VERSION "dbc-export 1 2025.20.8"

NS_ :

BS_:

BU_: APP BMS CC CMP CMPD CP DAS DI DIF DIR EPBL EPBR EVSE FC GTW HCML HCMR HVP ICR PCS PM PMF PMR PTC SCCM SCM SCS SDCR TAS UMC VC VCFRONT VCLEFT VCRIGHT VCSEC

BO_ 1962 HVP_debugMessage: 8 HVP
 SG_ HVP_debugMessageMultiplexer M : 0|4@1+ (1,0) [0|15] "" Vector__XXX
 SG_ HVP_gpioPassivePyroDepl m0 : 4|1@1+ (1,0) [0|1] "" Vector__XXX
 SG_ HVP_gpioPyroIsoEn m0 : 5|1@1+ (1,0) [0|1] "" Vector__XXX
 SG_ HVP_gpioCpFaultIn m0 : 6|1@1+ (1,0) [0|1] "" Vector__XXX
 SG_ HVP_gpioPackContPowerEn m0 : 7|1@1+ (1,0) [0|1] "" Vector__XXX
 SG_ HVP_gpioHvCablesOk m0 : 8|1@1+ (1,0) [0|1] "" Vector__XXX
 SG_ HVP_gpioHvpSelfEnable m0 : 9|1@1+ (1,0) [0|1] "" Vector__XXX
 SG_ HVP_gpioLed m0 : 10|1@1+ (1,0) [0|1] "" Vector__XXX
 SG_ HVP_gpioCrashSignal m0 : 11|1@1+ (1,0) [0|1] "" Vector__XXX
 SG_ HVP_gpioShuntDataReady m0 : 12|1@1+ (1,0) [0|1] "" Vector__XXX
 SG_ HVP_gpioFcContPosAux m0 : 13|1@1+ (1,0) [0|1] "" Vector__XXX
 SG_ HVP_gpioFcContNegAux m0 : 14|1@1+ (1,0) [0|1] "" Vector__XXX
 SG_ HVP_gpioBmsEout m0 : 15|1@1+ (1,0) [0|1] "" Vector__XXX
 SG_ HVP_gpioCpFaultOut m0 : 16|1@1+ (1,0) [0|1] "" Vector__XXX
 SG_ HVP_gpioPyroPor m0 : 17|1@1+ (1,0) [0|1] "" Vector__XXX
 SG_ HVP_gpioShuntEn m0 : 18|1@1+ (1,0) [0|1] "" Vector__XXX
 SG_ HVP_gpioHvpVerEn m0 : 19|1@1+ (1,0) [0|1] "" Vector__XXX
 SG_ HVP_gpioFcContFlywheelEnable m0 : 20|1@1+ (1,0) [0|1] "" Vector__XXX
 SG_ HVP_gpioCpLatchEnable m0 : 21|1@1+ (1,0) [0|1] "" Vector__XXX
 SG_ HVP_gpioFcContPowerEnable m0 : 22|1@1+ (1,0) [0|1] "" Vector__XXX
 SG_ HVP_gpioHvilEnable m0 : 23|1@1+ (1,0) [0|1] "" Vector__XXX
 SG_ HVP_gpioPortSelSpiRdy m0 : 24|1@1+ (1,0) [0|1] "" Vector__XXX
 SG_ HVP_gpioPyroUnlock m0 : 25|1@1+ (1,0) [0|1] "" Vector__XXX
 SG_ HVP_hvp1v5Ref m0 : 26|12@1+ (0.1,0) [0|3] "V" Vector__XXX
 SG_ HVP_packCurrentMia m0 : 38|1@1+ (1,0) [0|1] "" Vector__XXX
 SG_ HVP_auxCurrentMia m0 : 39|1@1+ (1,0) [0|1] "" Vector__XXX
 SG_ HVP_currentSenseMia m0 : 40|1@1+ (1,0) [0|1] "" Vector__XXX
 SG_ HVP_shuntRefVoltageMismatch m0 : 41|1@1+ (1,0) [0|1] "" Vector__XXX
 SG_ HVP_shuntThermistorMissing m0 : 42|1@1+ (1,0) [0|1] "" Vector__XXX
 SG_ HVP_shuntThermistorExpected m0 : 43|1@1+ (1,0) [0|1] "" Vector__XXX
 SG_ HVP_shuntThermistorMia m0 : 44|1@1+ (1,0) [0|1] "" Vector__XXX
 SG_ HVP_shuntUnexpectedThermistor m0 : 45|1@1+ (1,0) [0|1] "" Vector__XXX
 SG_ HVP_shuntHwMia m0 : 46|1@1+ (1,0) [0|1] "" Vector__XXX
 SG_ HVP_shuntCurrentIrrational m0 : 47|1@1+ (1,0) [0|1] "" Vector__XXX
 SG_ HVP_shuntAsicTCompActive m0 : 48|1@1+ (1,0) [0|1] "" Vector__XXX
 SG_ HVP_ecuLogUploadRequest m0 : 49|2@1+ (1,0) [0|3] "" Vector__XXX
 SG_ HVP_packContVoltage m2 : 4|12@1+ (0.1,0) [0|30] "V" Vector__XXX
 SG_ HVP_packNegativeV m2 : 16|16@1- (0.1,0) [-550|550] "V" Vector__XXX
 SG_ HVP_packPositiveV m2 : 32|16@1- (0.1,0) [-550|550] "V" Vector__XXX
 SG_ HVP_pyroAnalog m2 : 48|12@1+ (0.1,0) [0|3] "V" Vector__XXX
 SG_ HVP_fcContCoilCurrent m4 : 4|12@1+ (0.1,0) [0|7.5] "A" Vector__XXX
 SG_ HVP_fcContVoltage m4 : 16|12@1+ (0.1,0) [0|30] "V" Vector__XXX
 SG_ HVP_hvilInVoltage m4 : 28|12@1+ (0.1,0) [0|30] "V" Vector__XXX
 SG_ HVP_hvilOutVoltage m4 : 40|12@1+ (0.1,0) [0|30] "V" Vector__XXX
 SG_ HVP_shuntGainInvalidCountDbg m4 : 56|8@1+ (1,0) [0|255] "counts" Vector__XXX
 SG_ HVP_fcLinkPositiveV m5 : 8|16@1- (0.1,0) [-550|550] "V" Vector__XXX
 SG_ HVP_packContCoilCurrent m5 : 24|12@1+ (0.1,0) [0|7.5] "A" Vector__XXX
 SG_ HVP_battery12V m5 : 36|12@1+ (0.1,0) [0|30] "V" Vector__XXX
 SG_ HVP_shuntRefVoltageDbg m5 : 48|16@1- (0.001,0) [-32.768|32.767] "V" Vector__XXX

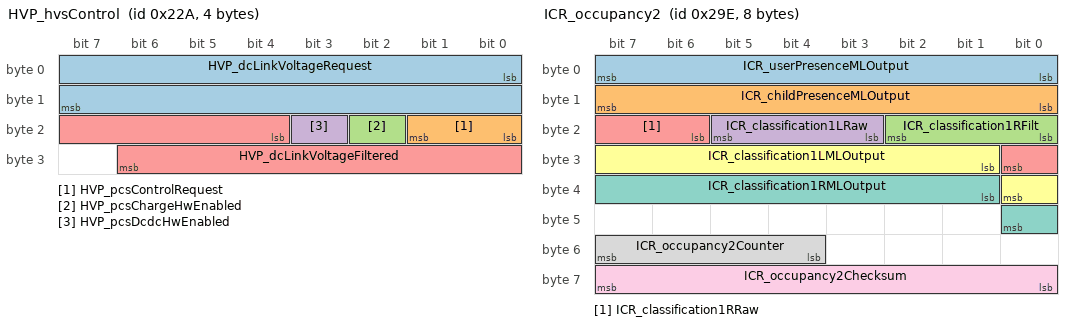
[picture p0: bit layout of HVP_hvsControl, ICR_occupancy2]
BO_ 554 HVP_hvsControl: 4 HVP
 SG_ HVP_dcLinkVoltageRequest : 0|16@1- (0.1,0) [-550|550] "V" Vector__XXX
 SG_ HVP_pcsControlRequest : 16|2@1+ (1,0) [0|3] "" Vector__XXX
 SG_ HVP_pcsChargeHwEnabled : 18|1@1+ (1,0) [0|1] "" Vector__XXX
 SG_ HVP_pcsDcdcHwEnabled : 19|1@1+ (1,0) [0|1] "" Vector__XXX
 SG_ HVP_dcLinkVoltageFiltered : 20|11@1- (1,0) [-550|550] "V" Vector__XXX

BO_ 784 HVP_info: 8 HVP
 SG_ HVP_infoIndex M : 0|8@1+ (1,0) [0|255] "" Vector__XXX
 SG_ HVP_buildType m10 : 8|3@1+ (1,0) [0|7] "" Vector__XXX
 SG_ HVP_buildConfigId m10 : 16|16@1+ (1,0) [0|65535] "" Vector__XXX
 SG_ HVP_hardwareId m10 : 32|16@1+ (1,0) [0|65535] "" Vector__XXX
 SG_ HVP_componentId m10 : 48|16@1+ (1,0) [0|65535] "" Vector__XXX
 SG_ HVP_pcbaId m11 : 16|8@1+ (1,0) [0|255] "" Vector__XXX
 SG_ HVP_assemblyId m11 : 24|8@1+ (1,0) [0|255] "" Vector__XXX
 SG_ HVP_usageId m11 : 32|16@1+ (1,0) [0|65535] "" Vector__XXX
 SG_ HVP_subUsageId m11 : 48|16@1+ (1,0) [0|65535] "" Vector__XXX
 SG_ HVP_platformType m13 : 8|8@1+ (1,0) [0|255] "" Vector__XXX
 SG_ HVP_appCrc m13 : 32|32@1+ (1,0) [0|4294967295] "" Vector__XXX
 SG_ HVP_appGitHash m17 : 8|56@1+ (1,0) [0|7.20575940379e+16] "" Vector__XXX
 SG_ HVP_bootGitHash m18 : 8|56@1+ (1,0) [0|7.20575940379e+16] "" Vector__XXX
 SG_ HVP_bootUdsProtoVersion m20 : 8|8@1+ (1,0) [0|255] "" Vector__XXX
 SG_ HVP_bootCrc m20 : 32|32@1+ (1,0) [0|4294967295] "" Vector__XXX

BO_ 1914 HVP_log1hz: 8 HVP
 SG_ HVP_log1HzIndex M : 0|3@1+ (1,0) [0|7] "" Vector__XXX
 SG_ HVP_bmbAsicType m0 : 3|2@1+ (1,0) [0|3] "" Vector__XXX
 SG_ HVP_shuntCurrentAuxLog m0 : 8|24@1- (0.001,0) [-8388.607|8388.607] "A" Vector__XXX
 SG_ HVP_pyroSquibResistance m0 : 32|16@1+ (0.001,0) [0|65.534] "Ohm" Vector__XXX
 SG_ HVP_shuntAsicChipXCoordinate m0 : 48|8@1+ (1,0) [0|255] "" Vector__XXX
 SG_ HVP_shuntAsicChipYCoordinate m0 : 56|8@1+ (1,0) [0|255] "" Vector__XXX
 SG_ HVP_hvilCalType m1 : 3|2@1+ (1,0) [0|3] "" Vector__XXX
 SG_ HVP_gpioPcsDcdcPwmEnable m1 : 5|1@1+ (1,0) [0|1] "" Vector__XXX
 SG_ HVP_gpioPcsChargePwmEnable m1 : 6|1@1+ (1,0) [0|1] "" Vector__XXX
 SG_ HVP_gpioPcsEnable m1 : 7|1@1+ (1,0) [0|1] "" Vector__XXX
 SG_ HVP_shuntAsicChipWaferNumber m1 : 8|8@1+ (1,0) [0|255] "" Vector__XXX
 SG_ HVP_energyReserveMin m1 : 16|16@1- (0.001,0) [-32.768|32.767] "V" Vector__XXX
 SG_ HVP_energyReserveMax m1 : 32|16@1- (0.001,0) [-32.768|32.767] "V" Vector__XXX
 SG_ HVP_energyReserveAvg m1 : 48|16@1- (0.001,0) [-32.768|32.767] "V" Vector__XXX

BO_ 1208 ICR_alertLog: 8 ICR
 SG_ ICR_alertID M : 0|8@1+ (1,0) [0|255] "" Vector__XXX
 SG_ ICR_alertState : 15|1@1+ (1,0) [0|1] "" Vector__XXX
 SG_ ICR_a001_watchdogTaskAppDPM m1 : 16|1@1+ (1,0) [0|1] "" Vector__XXX
 SG_ ICR_a001_watchdogTaskMMWControl m1 : 17|1@1+ (1,0) [0|1] "" Vector__XXX
 SG_ ICR_a001_watchdogTaskSentinelInt m1 : 18|1@1+ (1,0) [0|1] "" Vector__XXX
 SG_ ICR_a001_watchdogTaskSentinelMod m1 : 19|1@1+ (1,0) [0|1] "" Vector__XXX
 SG_ ICR_a001_watchdogTaskComTXRAD m1 : 20|1@1+ (1,0) [0|1] "" Vector__XXX
 SG_ ICR_a001_watchdogTaskComRX m1 : 21|1@1+ (1,0) [0|1] "" Vector__XXX
 SG_ ICR_a001_watchdogTaskComTXVEH m1 : 22|1@1+ (1,0) [0|1] "" Vector__XXX
 SG_ ICR_a001_watchdogTaskComUDS m1 : 23|1@1+ (1,0) [0|1] "" Vector__XXX
 SG_ ICR_a001_watchdogTaskCommonError m1 : 24|1@1+ (1,0) [0|1] "" Vector__XXX
 SG_ ICR_a001_watchdogTaskUARTLog m1 : 25|1@1+ (1,0) [0|1] "" Vector__XXX
 SG_ ICR_a001_watchdogTaskDataDump m1 : 26|1@1+ (1,0) [0|1] "" Vector__XXX
 SG_ ICR_a001_watchdogRTOSAppRun10MS m1 : 27|1@1+ (1,0) [0|1] "" Vector__XXX
 SG_ ICR_a001_watchdogRTOSAppRun1MS m1 : 28|1@1+ (1,0) [0|1] "" Vector__XXX
 SG_ ICR_a001_InternalWatchdog m1 : 29|1@1+ (1,0) [0|1] "" Vector__XXX
 SG_ ICR_a002_CPUUndervoltage m2 : 16|1@1+ (1,0) [0|1] "" Vector__XXX
 SG_ ICR_a002_PowerOnReset m2 : 17|1@1+ (1,0) [0|1] "" Vector__XXX
 SG_ ICR_a015_NVMMMemOverflow m15 : 16|1@1+ (1,0) [0|1] "" Vector__XXX
 SG_ ICR_a015_NVMMFilesystemError m15 : 17|1@1+ (1,0) [0|1] "" Vector__XXX
 SG_ ICR_a015_NVMMRecordIDError m15 : 18|1@1+ (1,0) [0|1] "" Vector__XXX
 SG_ ICR_a059_voltageDrop m59 : 16|12@1+ (0.005443676,0) [0|22.29185322] "V" Vector__XXX
 SG_ ICR_a059_resistanceEstimate m59 : 28|12@1+ (0.00244,0) [0|9.9918] "Ohms" Vector__XXX
 SG_ ICR_a059_current m59 : 40|12@1+ (0.05,0) [0|204.75] "A" Vector__XXX
 SG_ ICR_a063_switchChannel m63 : 16|8@1+ (1,0) [0|255] "" Vector__XXX
 SG_ ICR_a063_switchType m63 : 24|8@1+ (1,0) [0|255] "" Vector__XXX
 SG_ ICR_a063_ADCVoltage m63 : 32|8@1+ (0.025,0) [0|6.375] "V" Vector__XXX
 SG_ ICR_a063_disconnected m63 : 40|1@1+ (1,0) [0|1] "" Vector__XXX
 SG_ ICR_a063_indeterminate m63 : 41|1@1+ (1,0) [0|1] "" Vector__XXX
 SG_ ICR_a063_stuckActive m63 : 42|1@1+ (1,0) [0|1] "" Vector__XXX
 SG_ ICR_a063_faulted m63 : 43|1@1+ (1,0) [0|1] "" Vector__XXX
 SG_ ICR_a133_nearClutter m133 : 16|8@1- (0.2,0) [-25.6|25.4] "dB" Vector__XXX
 SG_ ICR_a133_farClutter m133 : 24|8@1- (0.2,0) [-25.6|25.4] "dB" Vector__XXX
 SG_ ICR_a137_nearClutter m137 : 16|8@1- (0.2,0) [-25.6|25.4] "dB" Vector__XXX
 SG_ ICR_a137_farClutter m137 : 24|8@1- (0.2,0) [-25.6|25.4] "dB" Vector__XXX
 SG_ ICR_a139_nearClutter m139 : 16|8@1- (0.2,0) [-25.6|25.4] "dB" Vector__XXX
 SG_ ICR_a139_farClutter m139 : 24|8@1- (0.2,0) [-25.6|25.4] "dB" Vector__XXX

BO_ 952 ICR_alertMatrix: 8 ICR
 SG_ ICR_matrixIndex M : 0|4@1+ (1,0) [0|15] "" Vector__XXX
 SG_ ICR_a001_WatchdogReset m0 : 4|1@1+ (1,0) [0|1] "" Vector__XXX
 SG_ ICR_a002_PowerLossReset m0 : 5|1@1+ (1,0) [0|1] "" Vector__XXX
 SG_ ICR_a003_SWAssertion m0 : 6|1@1+ (1,0) [0|1] "" Vector__XXX
 SG_ ICR_a005_CANTXError m0 : 8|1@1+ (1,0) [0|1] "" Vector__XXX
 SG_ ICR_a006_CANTX_cyclicError m0 : 9|1@1+ (1,0) [0|1] "" Vector__XXX
 SG_ ICR_a012_CPUReset m0 : 15|1@1+ (1,0) [0|1] "" Vector__XXX
 SG_ ICR_a013_AlertManagerFault m0 : 16|1@1+ (1,0) [0|1] "" Vector__XXX
 SG_ ICR_a015_NVMMError m0 : 18|1@1+ (1,0) [0|1] "" Vector__XXX
 SG_ ICR_a016_NVMMRecordError m0 : 19|1@1+ (1,0) [0|1] "" Vector__XXX
 SG_ ICR_a021_TaskSchedulerError m0 : 24|1@1+ (1,0) [0|1] "" Vector__XXX
 SG_ ICR_a022_TaskInitError m0 : 25|1@1+ (1,0) [0|1] "" Vector__XXX
 SG_ ICR_a029_CoreDump m0 : 32|1@1+ (1,0) [0|1] "" Vector__XXX
 SG_ ICR_a030_ECULogUploadRequest m0 : 33|1@1+ (1,0) [0|1] "" Vector__XXX
 SG_ ICR_a031_UDSActive m0 : 34|1@1+ (1,0) [0|1] "" Vector__XXX
 SG_ ICR_a041_HighCPULoad m0 : 44|1@1+ (1,0) [0|1] "" Vector__XXX
 SG_ ICR_a042_HighStackUsage m0 : 45|1@1+ (1,0) [0|1] "" Vector__XXX
 SG_ ICR_a043_Task1msError m0 : 46|1@1+ (1,0) [0|1] "" Vector__XXX
 SG_ ICR_a044_Task10msError m0 : 47|1@1+ (1,0) [0|1] "" Vector__XXX
 SG_ ICR_a045_Task100msError m0 : 48|1@1+ (1,0) [0|1] "" Vector__XXX
 SG_ ICR_a046_Task1000msError m0 : 49|1@1+ (1,0) [0|1] "" Vector__XXX
 SG_ ICR_a058_inputRHighSyncDebug m0 : 61|1@1+ (1,0) [0|1] "" Vector__XXX
 SG_ ICR_a059_inputResistanceHigh m0 : 62|1@1+ (1,0) [0|1] "" Vector__XXX
 SG_ ICR_a060_engineeringBuild m0 : 63|1@1+ (1,0) [0|1] "" Vector__XXX
 SG_ ICR_a061_XCPConnected m1 : 4|1@1+ (1,0) [0|1] "" Vector__XXX
 SG_ ICR_a062_XCPWasConnected m1 : 5|1@1+ (1,0) [0|1] "" Vector__XXX
 SG_ ICR_a063_SwitchFault m1 : 6|1@1+ (1,0) [0|1] "" Vector__XXX
 SG_ ICR_a064_busSleepReqTimeout m1 : 7|1@1+ (1,0) [0|1] "" Vector__XXX
 SG_ ICR_a133_radarBlocked m2 : 16|1@1+ (1,0) [0|1] "" Vector__XXX
 SG_ ICR_a134_radarPgood m2 : 17|1@1+ (1,0) [0|1] "" Vector__XXX
 SG_ ICR_a135_radarTxBallBreak m2 : 18|1@1+ (1,0) [0|1] "" Vector__XXX
 SG_ ICR_a136_radarHighTemperature m2 : 19|1@1+ (1,0) [0|1] "" Vector__XXX
 SG_ ICR_a137_radarBlocked m2 : 20|1@1+ (1,0) [0|1] "" Vector__XXX
 SG_ ICR_a138_DriverSideMismatch m2 : 21|1@1+ (1,0) [0|1] "" Vector__XXX
 SG_ ICR_a139_AbnormalBlockageDetecte m2 : 22|1@1+ (1,0) [0|1] "" Vector__XXX
 SG_ ICR_a140_OccupancyExceptionEncou m2 : 23|1@1+ (1,0) [0|1] "" Vector__XXX
 SG_ ICR_a141_RequiresReplacement m2 : 24|1@1+ (1,0) [0|1] "" Vector__XXX
 SG_ ICR_a142_ModeOverrideActive m2 : 25|1@1+ (1,0) [0|1] "" Vector__XXX

BO_ 941 ICR_info: 8 ICR
 SG_ ICR_infoIndex M : 0|8@1+ (1,0) [0|255] "" Vector__XXX
 SG_ ICR_infoBuildType m10 : 8|3@1+ (1,0) [0|7] "" Vector__XXX
 SG_ ICR_infoPcbaId m11 : 32|8@1+ (1,0) [0|255] "" Vector__XXX
 SG_ ICR_infoAssemblyId m11 : 40|8@1+ (1,0) [0|255] "" Vector__XXX
 SG_ ICR_infoUsageId m11 : 48|16@1+ (1,0) [0|65535] "" Vector__XXX
 SG_ ICR_infoAppCrc m13 : 8|32@1+ (1,0) [0|4294967295] "" Vector__XXX
 SG_ ICR_infoBoardPartNumber17 m25 : 8|56@1+ (1,0) [0|7.20575940379e+16] "" Vector__XXX
 SG_ ICR_infoBoardPartNumber814 m26 : 8|56@1+ (1,0) [0|7.20575940379e+16] "" Vector__XXX
 SG_ ICR_infoBoardPartNumber1520 m27 : 8|48@1+ (1,0) [0|281474976710655] "" Vector__XXX

BO_ 536 ICR_occupancy: 8 ICR
 SG_ ICR_occupancy1LRaw : 0|2@1+ (1,0) [0|2] "" Vector__XXX
 SG_ ICR_occupancy1RRaw : 2|2@1+ (1,0) [0|2] "" Vector__XXX
 SG_ ICR_occupancy1LVoteCnt : 4|6@1- (1,0) [-32|31] "" Vector__XXX
 SG_ ICR_occupancy1RVoteCnt : 10|6@1- (1,0) [-32|31] "" Vector__XXX
 SG_ ICR_userPresenceFilt : 16|2@1+ (1,0) [0|2] "" Vector__XXX
 SG_ ICR_userPresenceRaw : 19|2@1+ (1,0) [0|2] "" Vector__XXX
 SG_ ICR_occupancy1LFilt : 21|2@1+ (1,0) [0|2] "" Vector__XXX
 SG_ ICR_occupancy1RFilt : 23|2@1+ (1,0) [0|2] "" Vector__XXX
 SG_ ICR_occupancy2LFilt : 25|2@1+ (1,0) [0|2] "" Vector__XXX
 SG_ ICR_occupancy2CFilt : 27|2@1+ (1,0) [0|2] "" Vector__XXX
 SG_ ICR_occupancy2RFilt : 29|2@1+ (1,0) [0|2] "" Vector__XXX
 SG_ ICR_childPresenceFilt : 31|3@1+ (1,0) [1|7] "" Vector__XXX
 SG_ ICR_childPresenceRaw : 34|3@1+ (1,0) [1|7] "" Vector__XXX
 SG_ ICR_classification1LFilt : 37|3@1+ (1,0) [1|7] "" Vector__XXX
 SG_ ICR_classification1RqF : 40|1@1+ (1,0) [0|1] "" Vector__XXX
 SG_ ICR_occupancy1RFiltExp : 41|2@1+ (1,0) [0|2] "" Vector__XXX
 SG_ ICR_occupancyCounter : 52|4@1+ (1,0) [0|15] "" Vector__XXX
 SG_ ICR_occupancyChecksum : 56|8@1+ (1,0) [0|255] "" Vector__XXX

BO_ 670 ICR_occupancy2: 8 ICR
 SG_ ICR_userPresenceMLOutput : 0|8@1+ (0.004,0) [0|1.016] "points" Vector__XXX
 SG_ ICR_childPresenceMLOutput : 8|8@1+ (0.004,0) [0|1.016] "points" Vector__XXX
 SG_ ICR_classification1RFilt : 16|3@1+ (1,0) [1|7] "" Vector__XXX
 SG_ ICR_classification1LRaw : 19|3@1+ (1,0) [1|7] "" Vector__XXX
 SG_ ICR_classification1RRaw : 22|3@1+ (1,0) [1|7] "" Vector__XXX
 SG_ ICR_classification1LMLOutput : 25|8@1+ (0.004,0) [0|1.016] "points" Vector__XXX
 SG_ ICR_classification1RMLOutput : 33|8@1+ (0.004,0) [0|1.016] "points" Vector__XXX
 SG_ ICR_occupancy2Counter : 52|4@1+ (1,0) [0|15] "" Vector__XXX
 SG_ ICR_occupancy2Checksum : 56|8@1+ (1,0) [0|255] "" Vector__XXX

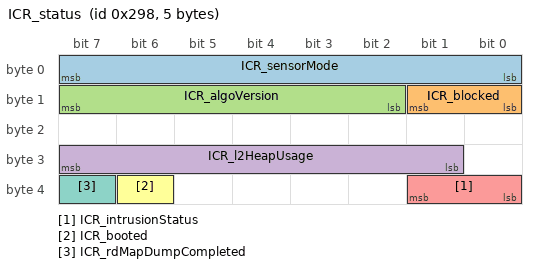
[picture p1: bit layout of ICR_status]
BO_ 664 ICR_status: 5 ICR
 SG_ ICR_sensorMode : 0|8@1+ (1,0) [0|255] "" Vector__XXX
 SG_ ICR_blocked : 8|2@1+ (1,0) [1|3] "" Vector__XXX
 SG_ ICR_algoVersion : 10|6@1+ (1,0) [0|63] "" Vector__XXX
 SG_ ICR_l2HeapUsage : 25|7@1+ (1,0) [0|127] "PCT" Vector__XXX
 SG_ ICR_intrusionStatus : 32|2@1+ (1,0) [0|3] "" Vector__XXX
 SG_ ICR_booted : 38|1@1+ (1,0) [0|1] "" Vector__XXX
 SG_ ICR_rdMapDumpCompleted : 39|1@1+ (1,0) [0|1] "" Vector__XXX

BO_ 1012 LS_lightShow: 8 GTW
 SG_ LS_lightShowIndex M : 0|5@1+ (1,0) [0|31] "" Vector__XXX
 SG_ LS_lightLeftRampedChannel1Reques m0 : 5|1@1+ (1,0) [0|1] "" Vector__XXX
 SG_ LS_lightLeftRampedChannel1Durati m0 : 6|2@1+ (1,0) [0|3] "" Vector__XXX
 SG_ LS_lightLeftRampedChannel2Reques m0 : 8|1@1+ (1,0) [0|1] "" Vector__XXX
 SG_ LS_lightLeftRampedChannel2Durati m0 : 9|2@1+ (1,0) [0|3] "" Vector__XXX
 SG_ LS_lightLeftRampedChannel3Reques m0 : 11|1@1+ (1,0) [0|1] "" Vector__XXX
 SG_ LS_lightLeftRampedChannel3Durati m0 : 12|2@1+ (1,0) [0|3] "" Vector__XXX
 SG_ LS_lightLeftRampedChannel4Reques m0 : 14|1@1+ (1,0) [0|1] "" Vector__XXX
 SG_ LS_lightLeftRampedChannel4Durati m0 : 16|2@1+ (1,0) [0|3] "" Vector__XXX
 SG_ LS_lightLeftRampedChannel5Reques m0 : 18|1@1+ (1,0) [0|1] "" Vector__XXX
 SG_ LS_lightLeftRampedChannel5Durati m0 : 19|2@1+ (1,0) [0|3] "" Vector__XXX
 SG_ LS_lightLeftRampedChannel6Reques m0 : 21|1@1+ (1,0) [0|1] "" Vector__XXX
 SG_ LS_lightLeftRampedChannel6Durati m0 : 22|2@1+ (1,0) [0|3] "" Vector__XXX
 SG_ LS_lightLeftRampedChannel7Reques m0 : 24|1@1+ (1,0) [0|1] "" Vector__XXX
 SG_ LS_lightLeftRampedChannel7Durati m0 : 25|2@1+ (1,0) [0|3] "" Vector__XXX
 SG_ LS_lightRightRampedChannel1Reque m0 : 27|1@1+ (1,0) [0|1] "" Vector__XXX
 SG_ LS_lightRightRampedChannel1Durat m0 : 28|2@1+ (1,0) [0|3] "" Vector__XXX
 SG_ LS_lightRightRampedChannel2Reque m0 : 30|1@1+ (1,0) [0|1] "" Vector__XXX
 SG_ LS_lightRightRampedChannel2Durat m0 : 31|2@1+ (1,0) [0|3] "" Vector__XXX
 SG_ LS_lightRightRampedChannel3Reque m0 : 33|1@1+ (1,0) [0|1] "" Vector__XXX
 SG_ LS_lightRightRampedChannel3Durat m0 : 34|2@1+ (1,0) [0|3] "" Vector__XXX
 SG_ LS_lightRightRampedChannel4Reque m0 : 36|1@1+ (1,0) [0|1] "" Vector__XXX
 SG_ LS_lightRightRampedChannel4Durat m0 : 37|2@1+ (1,0) [0|3] "" Vector__XXX
 SG_ LS_lightRightRampedChannel5Reque m0 : 39|1@1+ (1,0) [0|1] "" Vector__XXX
 SG_ LS_lightRightRampedChannel5Durat m0 : 40|2@1+ (1,0) [0|3] "" Vector__XXX
 SG_ LS_lightRightRampedChannel6Reque m0 : 42|1@1+ (1,0) [0|1] "" Vector__XXX
 SG_ LS_lightRightRampedChannel6Durat m0 : 43|2@1+ (1,0) [0|3] "" Vector__XXX
 SG_ LS_lightRightRampedChannel7Reque m0 : 45|1@1+ (1,0) [0|1] "" Vector__XXX
 SG_ LS_lightRightRampedChannel7Durat m0 : 46|2@1+ (1,0) [0|3] "" Vector__XXX
 SG_ LS_lightRearTurnLeftRequest m0 : 48|1@1+ (1,0) [0|1] "" Vector__XXX
 SG_ LS_lightRearTurnRightRequest m0 : 49|1@1+ (1,0) [0|1] "" Vector__XXX
 SG_ LS_lightSideRepeaterLeftRequest m0 : 50|1@1+ (1,0) [0|1] "" Vector__XXX
 SG_ LS_lightSideRepeaterRightRequest m0 : 51|1@1+ (1,0) [0|1] "" Vector__XXX
 SG_ LS_lightSideMarkerLeftRequest m0 : 52|1@1+ (1,0) [0|1] "" Vector__XXX
 SG_ LS_lightSideMarkerRightRequest m0 : 53|1@1+ (1,0) [0|1] "" Vector__XXX
 SG_ LS_lightFrontFogLeftRequest m0 : 54|1@1+ (1,0) [0|1] "" Vector__XXX
 SG_ LS_lightFrontFogRightRequest m0 : 55|1@1+ (1,0) [0|1] "" Vector__XXX
 SG_ LS_lightRearFogRequest m0 : 56|1@1+ (1,0) [0|1] "" Vector__XXX
 SG_ LS_lightBrakeRequest m0 : 57|1@1+ (1,0) [0|1] "" Vector__XXX
 SG_ LS_lightTailLeftRequest m0 : 58|1@1+ (1,0) [0|1] "" Vector__XXX
 SG_ LS_lightTailRightRequest m0 : 59|1@1+ (1,0) [0|1] "" Vector__XXX
 SG_ LS_lightLicensePlateRequest m0 : 60|1@1+ (1,0) [0|1] "" Vector__XXX
 SG_ LS_lightReverseRequest m0 : 61|1@1+ (1,0) [0|1] "" Vector__XXX
 SG_ LS_lightAuxParkLeftRequest m0 : 62|1@1+ (1,0) [0|1] "" Vector__XXX
 SG_ LS_lightAuxParkRightRequest m0 : 63|1@1+ (1,0) [0|1] "" Vector__XXX
 SG_ LS_mirrorRequestLeft m1 : 5|3@1+ (1,0) [0|7] "" Vector__XXX
 SG_ LS_mirrorRequestRight m1 : 8|3@1+ (1,0) [0|7] "" Vector__XXX
 SG_ LS_liftgateRequest m1 : 11|3@1+ (1,0) [0|7] "" Vector__XXX
 SG_ LS_windowRequestLF m1 : 16|3@1+ (1,0) [0|7] "" Vector__XXX
 SG_ LS_windowRequestLR m1 : 19|3@1+ (1,0) [0|7] "" Vector__XXX
 SG_ LS_windowRequestRF m1 : 24|3@1+ (1,0) [0|7] "" Vector__XXX
 SG_ LS_windowRequestRR m1 : 27|3@1+ (1,0) [0|7] "" Vector__XXX
 SG_ LS_presentingHandleRequestLF m1 : 32|3@1+ (1,0) [0|7] "" Vector__XXX
 SG_ LS_presentingHandleRequestLR m1 : 35|3@1+ (1,0) [0|7] "" Vector__XXX
 SG_ LS_presentingHandleRequestRF m1 : 40|3@1+ (1,0) [0|7] "" Vector__XXX
 SG_ LS_presentingHandleRequestRR m1 : 43|3@1+ (1,0) [0|7] "" Vector__XXX
 SG_ LS_powerFrontDoorRequestLeft m1 : 46|3@1+ (1,0) [0|7] "" Vector__XXX
 SG_ LS_powerFrontDoorRequestRight m1 : 49|3@1+ (1,0) [0|7] "" Vector__XXX
 SG_ LS_falconDoorRequestLeft m1 : 52|3@1+ (1,0) [0|7] "" Vector__XXX
 SG_ LS_falconDoorRequestRight m1 : 55|3@1+ (1,0) [0|7] "" Vector__XXX
 SG_ LS_chargePortRequest m1 : 58|2@1+ (1,0) [0|2] "" Vector__XXX
 SG_ LS_chargePortRaveRequest m1 : 60|1@1+ (1,0) [0|1] "" Vector__XXX
 SG_ LS_suspensionRequest m1 : 61|2@1+ (1,0) [0|2] "" Vector__XXX
 SG_ LS_rgbIPFLRed m2 : 8|8@1+ (1,0) [0|255] "" Vector__XXX
 SG_ LS_rgbIPFLGreen m2 : 16|8@1+ (1,0) [0|255] "" Vector__XXX
 SG_ LS_rgbIPFLBlue m2 : 24|8@1+ (1,0) [0|255] "" Vector__XXX
 SG_ LS_rgbIPFRRed m2 : 32|8@1+ (1,0) [0|255] "" Vector__XXX
 SG_ LS_rgbIPFRGreen m2 : 40|8@1+ (1,0) [0|255] "" Vector__XXX
 SG_ LS_rgbIPFRBlue m2 : 48|8@1+ (1,0) [0|255] "" Vector__XXX
 SG_ LS_rgbDoorFLForeRed m3 : 8|8@1+ (1,0) [0|255] "" Vector__XXX
 SG_ LS_rgbDoorFLForeGreen m3 : 16|8@1+ (1,0) [0|255] "" Vector__XXX
 SG_ LS_rgbDoorFLForeBlue m3 : 24|8@1+ (1,0) [0|255] "" Vector__XXX
 SG_ LS_rgbDoorFLAftRed m3 : 32|8@1+ (1,0) [0|255] "" Vector__XXX
 SG_ LS_rgbDoorFLAftGreen m3 : 40|8@1+ (1,0) [0|255] "" Vector__XXX
 SG_ LS_rgbDoorFLAftBlue m3 : 48|8@1+ (1,0) [0|255] "" Vector__XXX
 SG_ LS_rgbDoorFRForeRed m4 : 8|8@1+ (1,0) [0|255] "" Vector__XXX
 SG_ LS_rgbDoorFRForeGreen m4 : 16|8@1+ (1,0) [0|255] "" Vector__XXX
 SG_ LS_rgbDoorFRForeBlue m4 : 24|8@1+ (1,0) [0|255] "" Vector__XXX
 SG_ LS_rgbDoorFRAftRed m4 : 32|8@1+ (1,0) [0|255] "" Vector__XXX
 SG_ LS_rgbDoorFRAftGreen m4 : 40|8@1+ (1,0) [0|255] "" Vector__XXX
 SG_ LS_rgbDoorFRAftBlue m4 : 48|8@1+ (1,0) [0|255] "" Vector__XXX
 SG_ LS_rgbDoorRLForeRed m5 : 8|8@1+ (1,0) [0|255] "" Vector__XXX
 SG_ LS_rgbDoorRLForeGreen m5 : 16|8@1+ (1,0) [0|255] "" Vector__XXX
 SG_ LS_rgbDoorRLForeBlue m5 : 24|8@1+ (1,0) [0|255] "" Vector__XXX
 SG_ LS_rgbDoorRLAftRed m5 : 32|8@1+ (1,0) [0|255] "" Vector__XXX
 SG_ LS_rgbDoorRLAftGreen m5 : 40|8@1+ (1,0) [0|255] "" Vector__XXX
 SG_ LS_rgbDoorRLAftBlue m5 : 48|8@1+ (1,0) [0|255] "" Vector__XXX
 SG_ LS_rgbDoorRRForeRed m6 : 8|8@1+ (1,0) [0|255] "" Vector__XXX
 SG_ LS_rgbDoorRRForeGreen m6 : 16|8@1+ (1,0) [0|255] "" Vector__XXX
 SG_ LS_rgbDoorRRForeBlue m6 : 24|8@1+ (1,0) [0|255] "" Vector__XXX
 SG_ LS_rgbDoorRRAftRed m6 : 32|8@1+ (1,0) [0|255] "" Vector__XXX
 SG_ LS_rgbDoorRRAftGreen m6 : 40|8@1+ (1,0) [0|255] "" Vector__XXX
 SG_ LS_rgbDoorRRAftBlue m6 : 48|8@1+ (1,0) [0|255] "" Vector__XXX
 SG_ LS_frontMatrix0 m7 : 8|8@1+ (1,0) [0|255] "" Vector__XXX
 SG_ LS_frontMatrix1 m7 : 16|8@1+ (1,0) [0|255] "" Vector__XXX
 SG_ LS_frontMatrix2 m7 : 24|8@1+ (1,0) [0|255] "" Vector__XXX
 SG_ LS_frontMatrix3 m7 : 32|8@1+ (1,0) [0|255] "" Vector__XXX
 SG_ LS_frontMatrix4 m7 : 40|8@1+ (1,0) [0|255] "" Vector__XXX
 SG_ LS_frontMatrix5 m7 : 48|8@1+ (1,0) [0|255] "" Vector__XXX
 SG_ LS_frontMatrix6 m7 : 56|8@1+ (1,0) [0|255] "" Vector__XXX
 SG_ LS_frontMatrix7 m8 : 8|8@1+ (1,0) [0|255] "" Vector__XXX
 SG_ LS_frontMatrix8 m8 : 16|8@1+ (1,0) [0|255] "" Vector__XXX
 SG_ LS_frontMatrix9 m8 : 24|8@1+ (1,0) [0|255] "" Vector__XXX
 SG_ LS_frontMatrix10 m8 : 32|8@1+ (1,0) [0|255] "" Vector__XXX
 SG_ LS_frontMatrix11 m8 : 40|8@1+ (1,0) [0|255] "" Vector__XXX
 SG_ LS_frontMatrix12 m8 : 48|8@1+ (1,0) [0|255] "" Vector__XXX
 SG_ LS_frontMatrix13 m8 : 56|8@1+ (1,0) [0|255] "" Vector__XXX
 SG_ LS_frontMatrix14 m9 : 8|8@1+ (1,0) [0|255] "" Vector__XXX
 SG_ LS_frontMatrix15 m9 : 16|8@1+ (1,0) [0|255] "" Vector__XXX
 SG_ LS_frontMatrix16 m9 : 24|8@1+ (1,0) [0|255] "" Vector__XXX
 SG_ LS_frontMatrix17 m9 : 32|8@1+ (1,0) [0|255] "" Vector__XXX
 SG_ LS_frontMatrix18 m9 : 40|8@1+ (1,0) [0|255] "" Vector__XXX
 SG_ LS_frontMatrix19 m9 : 48|8@1+ (1,0) [0|255] "" Vector__XXX
 SG_ LS_frontMatrix20 m9 : 56|8@1+ (1,0) [0|255] "" Vector__XXX
 SG_ LS_frontMatrix21 m10 : 8|8@1+ (1,0) [0|255] "" Vector__XXX
 SG_ LS_frontMatrix22 m10 : 16|8@1+ (1,0) [0|255] "" Vector__XXX
 SG_ LS_frontMatrix23 m10 : 24|8@1+ (1,0) [0|255] "" Vector__XXX
 SG_ LS_frontMatrix24 m10 : 32|8@1+ (1,0) [0|255] "" Vector__XXX
 SG_ LS_frontMatrix25 m10 : 40|8@1+ (1,0) [0|255] "" Vector__XXX
 SG_ LS_frontMatrix26 m10 : 48|8@1+ (1,0) [0|255] "" Vector__XXX
 SG_ LS_frontMatrix27 m10 : 56|8@1+ (1,0) [0|255] "" Vector__XXX
 SG_ LS_frontMatrix28 m11 : 8|8@1+ (1,0) [0|255] "" Vector__XXX
 SG_ LS_frontMatrix29 m11 : 16|8@1+ (1,0) [0|255] "" Vector__XXX
 SG_ LS_frontMatrix30 m11 : 24|8@1+ (1,0) [0|255] "" Vector__XXX
 SG_ LS_frontMatrix31 m11 : 32|8@1+ (1,0) [0|255] "" Vector__XXX
 SG_ LS_frontMatrix32 m11 : 40|8@1+ (1,0) [0|255] "" Vector__XXX
 SG_ LS_frontMatrix33 m11 : 48|8@1+ (1,0) [0|255] "" Vector__XXX
 SG_ LS_frontMatrix34 m11 : 56|8@1+ (1,0) [0|255] "" Vector__XXX
 SG_ LS_frontMatrix35 m12 : 8|8@1+ (1,0) [0|255] "" Vector__XXX
 SG_ LS_frontMatrix36 m12 : 16|8@1+ (1,0) [0|255] "" Vector__XXX
 SG_ LS_frontMatrix37 m12 : 24|8@1+ (1,0) [0|255] "" Vector__XXX
 SG_ LS_frontMatrix38 m12 : 32|8@1+ (1,0) [0|255] "" Vector__XXX
 SG_ LS_frontMatrix39 m12 : 40|8@1+ (1,0) [0|255] "" Vector__XXX
 SG_ LS_frontMatrix40 m12 : 48|8@1+ (1,0) [0|255] "" Vector__XXX
 SG_ LS_frontMatrix41 m12 : 56|8@1+ (1,0) [0|255] "" Vector__XXX
 SG_ LS_frontMatrix42 m13 : 8|8@1+ (1,0) [0|255] "" Vector__XXX
 SG_ LS_frontMatrix43 m13 : 16|8@1+ (1,0) [0|255] "" Vector__XXX
 SG_ LS_frontMatrix44 m13 : 24|8@1+ (1,0) [0|255] "" Vector__XXX
 SG_ LS_frontMatrix45 m13 : 32|8@1+ (1,0) [0|255] "" Vector__XXX
 SG_ LS_frontMatrix46 m13 : 40|8@1+ (1,0) [0|255] "" Vector__XXX
 SG_ LS_frontMatrix47 m13 : 48|8@1+ (1,0) [0|255] "" Vector__XXX
 SG_ LS_frontMatrix48 m13 : 56|8@1+ (1,0) [0|255] "" Vector__XXX
 SG_ LS_frontMatrix49 m14 : 8|8@1+ (1,0) [0|255] "" Vector__XXX
 SG_ LS_frontMatrix50 m14 : 16|8@1+ (1,0) [0|255] "" Vector__XXX
 SG_ LS_frontMatrix51 m14 : 24|8@1+ (1,0) [0|255] "" Vector__XXX
 SG_ LS_frontMatrix52 m14 : 32|8@1+ (1,0) [0|255] "" Vector__XXX
 SG_ LS_frontMatrix53 m14 : 40|8@1+ (1,0) [0|255] "" Vector__XXX
 SG_ LS_frontMatrix54 m14 : 48|8@1+ (1,0) [0|255] "" Vector__XXX
 SG_ LS_frontMatrix55 m14 : 56|8@1+ (1,0) [0|255] "" Vector__XXX
 SG_ LS_frontMatrix56 m15 : 8|8@1+ (1,0) [0|255] "" Vector__XXX
 SG_ LS_frontMatrix57 m15 : 16|8@1+ (1,0) [0|255] "" Vector__XXX
 SG_ LS_frontMatrix58 m15 : 24|8@1+ (1,0) [0|255] "" Vector__XXX
 SG_ LS_frontMatrix59 m15 : 32|8@1+ (1,0) [0|255] "" Vector__XXX
 SG_ LS_rearMatrix0 m15 : 40|8@1+ (1,0) [0|255] "" Vector__XXX
 SG_ LS_rearMatrix1 m15 : 48|8@1+ (1,0) [0|255] "" Vector__XXX
 SG_ LS_rearMatrix2 m15 : 56|8@1+ (1,0) [0|255] "" Vector__XXX
 SG_ LS_rearMatrix3 m16 : 8|8@1+ (1,0) [0|255] "" Vector__XXX
 SG_ LS_rearMatrix4 m16 : 16|8@1+ (1,0) [0|255] "" Vector__XXX
 SG_ LS_rearMatrix5 m16 : 24|8@1+ (1,0) [0|255] "" Vector__XXX
 SG_ LS_rearMatrix6 m16 : 32|8@1+ (1,0) [0|255] "" Vector__XXX
 SG_ LS_rearMatrix7 m16 : 40|8@1+ (1,0) [0|255] "" Vector__XXX
 SG_ LS_rearMatrix8 m16 : 48|8@1+ (1,0) [0|255] "" Vector__XXX
 SG_ LS_rearMatrix9 m16 : 56|8@1+ (1,0) [0|255] "" Vector__XXX
 SG_ LS_rearMatrix10 m17 : 8|8@1+ (1,0) [0|255] "" Vector__XXX
 SG_ LS_rearMatrix11 m17 : 16|8@1+ (1,0) [0|255] "" Vector__XXX
 SG_ LS_rearMatrix12 m17 : 24|8@1+ (1,0) [0|255] "" Vector__XXX
 SG_ LS_rearMatrix13 m17 : 32|8@1+ (1,0) [0|255] "" Vector__XXX
 SG_ LS_rearMatrix14 m17 : 40|8@1+ (1,0) [0|255] "" Vector__XXX
 SG_ LS_rearMatrix15 m17 : 48|8@1+ (1,0) [0|255] "" Vector__XXX
 SG_ LS_rearMatrix16 m17 : 56|8@1+ (1,0) [0|255] "" Vector__XXX
 SG_ LS_rearMatrix17 m18 : 8|8@1+ (1,0) [0|255] "" Vector__XXX
 SG_ LS_rearMatrix18 m18 : 16|8@1+ (1,0) [0|255] "" Vector__XXX
 SG_ LS_rearMatrix19 m18 : 24|8@1+ (1,0) [0|255] "" Vector__XXX
 SG_ LS_rearMatrix20 m18 : 32|8@1+ (1,0) [0|255] "" Vector__XXX
 SG_ LS_rearMatrix21 m18 : 40|8@1+ (1,0) [0|255] "" Vector__XXX
 SG_ LS_rearMatrix22 m18 : 48|8@1+ (1,0) [0|255] "" Vector__XXX
 SG_ LS_rearMatrix23 m18 : 56|8@1+ (1,0) [0|255] "" Vector__XXX
 SG_ LS_rearMatrix24 m19 : 8|8@1+ (1,0) [0|255] "" Vector__XXX
 SG_ LS_rearMatrix25 m19 : 16|8@1+ (1,0) [0|255] "" Vector__XXX
 SG_ LS_rearMatrix26 m19 : 24|8@1+ (1,0) [0|255] "" Vector__XXX
 SG_ LS_rearMatrix27 m19 : 32|8@1+ (1,0) [0|255] "" Vector__XXX
 SG_ LS_rearMatrix28 m19 : 40|8@1+ (1,0) [0|255] "" Vector__XXX
 SG_ LS_rearMatrix29 m19 : 48|8@1+ (1,0) [0|255] "" Vector__XXX
 SG_ LS_rearMatrix30 m19 : 56|8@1+ (1,0) [0|255] "" Vector__XXX
 SG_ LS_rearMatrix31 m20 : 8|8@1+ (1,0) [0|255] "" Vector__XXX
 SG_ LS_rearMatrix32 m20 : 16|8@1+ (1,0) [0|255] "" Vector__XXX
 SG_ LS_rearMatrix33 m20 : 24|8@1+ (1,0) [0|255] "" Vector__XXX
 SG_ LS_rearMatrix34 m20 : 32|8@1+ (1,0) [0|255] "" Vector__XXX
 SG_ LS_rearMatrix35 m20 : 40|8@1+ (1,0) [0|255] "" Vector__XXX
 SG_ LS_rearMatrix36 m20 : 48|8@1+ (1,0) [0|255] "" Vector__XXX
 SG_ LS_rearMatrix37 m20 : 56|8@1+ (1,0) [0|255] "" Vector__XXX
 SG_ LS_rearMatrix38 m21 : 8|8@1+ (1,0) [0|255] "" Vector__XXX
 SG_ LS_rearMatrix39 m21 : 16|8@1+ (1,0) [0|255] "" Vector__XXX
 SG_ LS_rearMatrix40 m21 : 24|8@1+ (1,0) [0|255] "" Vector__XXX
 SG_ LS_rearMatrix41 m21 : 32|8@1+ (1,0) [0|255] "" Vector__XXX
 SG_ LS_rearMatrix42 m21 : 40|8@1+ (1,0) [0|255] "" Vector__XXX
 SG_ LS_rearMatrix43 m21 : 48|8@1+ (1,0) [0|255] "" Vector__XXX
 SG_ LS_rearMatrix44 m21 : 56|8@1+ (1,0) [0|255] "" Vector__XXX
 SG_ LS_rearMatrix45 m22 : 8|8@1+ (1,0) [0|255] "" Vector__XXX
 SG_ LS_rearMatrix46 m22 : 16|8@1+ (1,0) [0|255] "" Vector__XXX
 SG_ LS_rearMatrix47 m22 : 24|8@1+ (1,0) [0|255] "" Vector__XXX
 SG_ LS_rearMatrix48 m22 : 32|8@1+ (1,0) [0|255] "" Vector__XXX
 SG_ LS_rearMatrix49 m22 : 40|8@1+ (1,0) [0|255] "" Vector__XXX
 SG_ LS_rearMatrix50 m22 : 48|8@1+ (1,0) [0|255] "" Vector__XXX
 SG_ LS_rearMatrix51 m22 : 56|8@1+ (1,0) [0|255] "" Vector__XXX
 SG_ LS_rearMatrix52 m23 : 8|8@1+ (1,0) [0|255] "" Vector__XXX
 SG_ LS_rearMatrix53 m23 : 16|8@1+ (1,0) [0|255] "" Vector__XXX
 SG_ LS_rearMatrix54 m23 : 24|8@1+ (1,0) [0|255] "" Vector__XXX
 SG_ LS_rearMatrix55 m23 : 32|8@1+ (1,0) [0|255] "" Vector__XXX
 SG_ LS_rearMatrix56 m23 : 40|8@1+ (1,0) [0|255] "" Vector__XXX
 SG_ LS_rearMatrix57 m23 : 48|8@1+ (1,0) [0|255] "" Vector__XXX
 SG_ LS_rearMatrix58 m23 : 56|8@1+ (1,0) [0|255] "" Vector__XXX
 SG_ LS_rearMatrix59 m24 : 8|8@1+ (1,0) [0|255] "" Vector__XXX
 SG_ LS_offroadLightBar0 m24 : 16|8@1+ (1,0) [0|255] "" Vector__XXX
 SG_ LS_offroadLightBar1 m24 : 24|8@1+ (1,0) [0|255] "" Vector__XXX
 SG_ LS_offroadLightBar2 m24 : 32|8@1+ (1,0) [0|255] "" Vector__XXX
 SG_ LS_offroadLightBar3 m24 : 40|8@1+ (1,0) [0|255] "" Vector__XXX
 SG_ LS_offroadLightBar4 m24 : 48|8@1+ (1,0) [0|255] "" Vector__XXX
 SG_ LS_offroadLightBar5 m24 : 56|8@1+ (1,0) [0|255] "" Vector__XXX

BO_ 1060 PCS_alertLog: 8 PCS
 SG_ PCS_alertID M : 0|7@1+ (1,0) [0|127] "" Vector__XXX
 SG_ PCS_alertSet : 15|1@1+ (1,0) [0|1] "" Vector__XXX
 SG_ PCS_alertSource : 61|3@1+ (1,0) [0|7] "" Vector__XXX
 SG_ PCS_a001_llcFrequency m1 : 16|8@1+ (1,50) [50|305] "kHz" Vector__XXX
 SG_ PCS_a001_llcCurrent m1 : 24|8@1+ (0.1,0) [0|25.5] "A" Vector__XXX
 SG_ PCS_a001_phState m1 : 32|4@1+ (1,0) [0|15] "" Vector__XXX
 SG_ PCS_a001_pfcCurrentRms m1 : 36|9@1+ (0.1,0) [0|51.1] "A" Vector__XXX
 SG_ PCS_a001_intBusV m1 : 45|9@1+ (1,0) [0|511] "V" Vector__XXX
 SG_ PCS_a002_phState m2 : 16|4@1+ (1,0) [0|15] "" Vector__XXX
 SG_ PCS_a003_phState m3 : 16|4@1+ (1,0) [0|15] "" Vector__XXX
 SG_ PCS_a004_phState m4 : 16|4@1+ (1,0) [0|15] "" Vector__XXX
 SG_ PCS_a005_outputV m5 : 16|8@1+ (2,0) [0|510] "V" Vector__XXX
 SG_ PCS_a005_outputVOvThreshold m5 : 24|8@1+ (2,0) [0|510] "V" Vector__XXX
 SG_ PCS_a006_phState m6 : 16|4@1+ (1,0) [0|15] "" Vector__XXX
 SG_ PCS_a006_intBusPrechargeTarget m6 : 20|9@1+ (1,0) [0|511] "V" Vector__XXX
 SG_ PCS_a006_intBusV m6 : 29|9@1+ (1,0) [0|511] "V" Vector__XXX
 SG_ PCS_a006_inputVrms m6 : 38|9@1+ (1,0) [0|511] "V" Vector__XXX
 SG_ PCS_a006_inputVToIntBusDeltaMax m6 : 47|7@1+ (1,0) [0|127] "V" Vector__XXX
 SG_ PCS_a006_inputFrequency m6 : 54|7@1+ (1,40) [40|167] "Hz" Vector__XXX
 SG_ PCS_a007_phATemperature m7 : 16|7@1+ (1,0) [0|127] "C" Vector__XXX
 SG_ PCS_a007_phBTemperature m7 : 23|7@1+ (1,0) [0|127] "C" Vector__XXX
 SG_ PCS_a007_phCTemperature m7 : 30|7@1+ (1,0) [0|127] "C" Vector__XXX
 SG_ PCS_a007_ambientTemperature m7 : 37|7@1+ (1,0) [0|127] "C" Vector__XXX
 SG_ PCS_a007_inputVrms m7 : 44|9@1+ (1,0) [0|511] "V" Vector__XXX
 SG_ PCS_a007_inputIrms m7 : 53|8@1+ (0.5,0) [0|127.5] "A" Vector__XXX
 SG_ PCS_a008_phState m8 : 16|4@1+ (1,0) [0|15] "" Vector__XXX
 SG_ PCS_a008_phaseTemperature m8 : 20|11@1- (0.1,40) [-62.4|142.3] "C" Vector__XXX
 SG_ PCS_a008_inputVrms m8 : 31|9@1+ (1,0) [0|511] "V" Vector__XXX
 SG_ PCS_a008_inputIrms m8 : 40|10@1+ (0.1,0) [0|102.3] "A" Vector__XXX
 SG_ PCS_a009_phState m9 : 16|4@1+ (1,0) [0|15] "" Vector__XXX
 SG_ PCS_a009_pfcCurrentRms m9 : 20|9@1+ (0.1,0) [0|51.1] "A" Vector__XXX
 SG_ PCS_a009_pfcCurrentTarget m9 : 32|12@1+ (0.01,0) [0|40.95] "A" Vector__XXX
 SG_ PCS_a009_llcCurrent m9 : 44|8@1+ (0.1,0) [0|25.5] "A" Vector__XXX
 SG_ PCS_a009_intBusV m9 : 52|8@1+ (2,0) [0|510] "V" Vector__XXX
 SG_ PCS_a010_phState m10 : 16|4@1+ (1,0) [0|15] "" Vector__XXX
 SG_ PCS_a010_pfcCurrentRms m10 : 20|9@1+ (0.1,0) [0|51.1] "A" Vector__XXX
 SG_ PCS_a010_llcCurrent m10 : 32|8@1+ (0.1,0) [0|25.5] "A" Vector__XXX
 SG_ PCS_a010_intBusV m10 : 40|9@1+ (1,0) [0|511] "V" Vector__XXX
 SG_ PCS_a010_intBusVTarget m10 : 49|9@1+ (1,0) [0|511] "V" Vector__XXX
 SG_ PCS_a011_phState m11 : 16|4@1+ (1,0) [0|15] "" Vector__XXX
 SG_ PCS_a011_llcCurrent m11 : 20|8@1+ (0.1,0) [0|25.5] "A" Vector__XXX
 SG_ PCS_a011_llcCurrentTarget m11 : 28|8@1+ (0.1,0) [0|25.5] "A" Vector__XXX
 SG_ PCS_a011_llcFrequency m11 : 36|8@1+ (1,50) [50|305] "kHz" Vector__XXX
 SG_ PCS_a011_intBusV m11 : 44|8@1+ (2,0) [0|510] "V" Vector__XXX
 SG_ PCS_a011_outputV m11 : 52|8@1+ (2,0) [0|510] "V" Vector__XXX
 SG_ PCS_a012_phState m12 : 16|4@1+ (1,0) [0|15] "" Vector__XXX
 SG_ PCS_a012_llcFrequency m12 : 20|8@1+ (1,50) [50|305] "kHz" Vector__XXX
 SG_ PCS_a012_llcCurrent m12 : 28|8@1+ (0.1,0) [0|25.5] "A" Vector__XXX
 SG_ PCS_a012_outOfIBandDuration m12 : 36|7@1+ (0.05,0) [0|6.35] "us" Vector__XXX
 SG_ PCS_a012_batteryV m12 : 43|9@1+ (1,0) [0|511] "V" Vector__XXX
 SG_ PCS_a012_transientRetryCount m12 : 52|9@1+ (0.1,0) [0|51.1] "-" Vector__XXX
 SG_ PCS_a013_phState m13 : 16|4@1+ (1,0) [0|15] "" Vector__XXX
 SG_ PCS_a013_intBusPrechargeTarget m13 : 20|9@1+ (1,0) [0|511] "V" Vector__XXX
 SG_ PCS_a013_intBusV m13 : 29|9@1+ (1,0) [0|511] "V" Vector__XXX
 SG_ PCS_a013_inputVrms m13 : 38|9@1+ (1,0) [0|511] "V" Vector__XXX
 SG_ PCS_a013_inputVToIntBusDeltaMax m13 : 47|7@1+ (1,0) [0|127] "V" Vector__XXX
 SG_ PCS_a013_inputFrequency m13 : 54|7@1+ (1,40) [40|167] "Hz" Vector__XXX
 SG_ PCS_a014_phaTemperature m14 : 16|11@1- (0.1,40) [-62.4|142.3] "C" Vector__XXX
 SG_ PCS_a014_phbTemperature m14 : 27|11@1- (0.1,40) [-62.4|142.3] "C" Vector__XXX
 SG_ PCS_a014_phcTemperature m14 : 40|11@1- (0.1,40) [-62.4|142.3] "C" Vector__XXX
 SG_ PCS_a015_lvBusVoltage m15 : 16|8@1+ (0.15625,0) [0|39.84375] "V" Vector__XXX
 SG_ PCS_a016_phAVoltSrcMissingDetect m16 : 16|1@1+ (1,0) [0|1] "" Vector__XXX
 SG_ PCS_a016_phBVoltSrcMissingDetect m16 : 17|1@1+ (1,0) [0|1] "" Vector__XXX
 SG_ PCS_a016_phCVoltSrcMissingDetect m16 : 18|1@1+ (1,0) [0|1] "" Vector__XXX
 SG_ PCS_a018_PhaseDiff_L1N_L2N m18 : 16|9@1+ (1,-1) [-1|510] "deg" Vector__XXX
 SG_ PCS_a018_PhaseDiff_L2N_L3N m18 : 25|9@1+ (1,-1) [-1|510] "deg" Vector__XXX
 SG_ PCS_a018_PhaseDiff_L1N_L3N m18 : 34|9@1+ (1,-1) [-1|510] "deg" Vector__XXX
 SG_ PCS_a018_PhaseDiff_L1L2_L1N m18 : 43|9@1+ (1,-1) [-1|510] "deg" Vector__XXX
 SG_ PCS_a018_L1NLocked m18 : 52|1@1+ (1,0) [0|1] "" Vector__XXX
 SG_ PCS_a018_L2NLocked m18 : 53|1@1+ (1,0) [0|1] "" Vector__XXX
 SG_ PCS_a018_L3NLocked m18 : 54|1@1+ (1,0) [0|1] "" Vector__XXX
 SG_ PCS_a018_L1L2Locked m18 : 55|1@1+ (1,0) [0|1] "" Vector__XXX
 SG_ PCS_a019_pcsMaxAvailablePower m19 : 16|8@1+ (0.1,0) [0|25.5] "kW" Vector__XXX
 SG_ PCS_a019_utilityPowerAvailable m19 : 24|8@1+ (0.1,0) [0|25.5] "kW" Vector__XXX
 SG_ PCS_a019_userPowerRequest m19 : 32|8@1+ (0.1,0) [0|25.5] "kW" Vector__XXX
 SG_ PCS_a019_phAFaulted m19 : 40|1@1+ (1,0) [0|1] "" Vector__XXX
 SG_ PCS_a019_phBFaulted m19 : 41|1@1+ (1,0) [0|1] "" Vector__XXX
 SG_ PCS_a019_phCFaulted m19 : 42|1@1+ (1,0) [0|1] "" Vector__XXX
 SG_ PCS_a020_chargeEnableLine m20 : 16|1@1+ (1,0) [0|1] "" Vector__XXX
 SG_ PCS_a020_chargeEnableCan m20 : 17|1@1+ (1,0) [0|1] "" Vector__XXX
 SG_ PCS_a021_HVP_hvsControl m21 : 16|1@1+ (1,0) [0|1] "" Vector__XXX
 SG_ PCS_a022_BMS_pcsRequest m22 : 16|1@1+ (1,0) [0|1] "" Vector__XXX
 SG_ PCS_a022_BMS_chargeStatus m22 : 17|1@1+ (1,0) [0|1] "" Vector__XXX
 SG_ PCS_a023_CP_chargeStatus m23 : 16|1@1+ (1,0) [0|1] "" Vector__XXX
 SG_ PCS_a023_CP_status m23 : 17|1@1+ (1,0) [0|1] "" Vector__XXX
 SG_ PCS_a024_VCFRONT_sensors m24 : 16|1@1+ (1,0) [0|1] "" Vector__XXX
 SG_ PCS_a024_VCFRONT_vehicleStatus m24 : 17|1@1+ (1,0) [0|1] "" Vector__XXX
 SG_ PCS_a024_VCFRONT_systemStatus m24 : 18|1@1+ (1,0) [0|1] "" Vector__XXX
 SG_ PCS_a024_VCFRONT_coolant m24 : 19|1@1+ (1,0) [0|1] "" Vector__XXX
 SG_ PCS_a024_VCFRONT_vehNm m24 : 20|1@1+ (1,0) [0|1] "" Vector__XXX
 SG_ PCS_a025_cpu2ErrorCode m25 : 16|4@1+ (1,0) [0|15] "" Vector__XXX
 SG_ PCS_a025_bootromStatus m25 : 20|4@1+ (1,0) [0|15] "" Vector__XXX
 SG_ PCS_a025_bootloaderStatus m25 : 24|4@1+ (1,0) [0|15] "" Vector__XXX
 SG_ PCS_a025_bootromRequestFlag m25 : 28|1@1+ (1,0) [0|1] "" Vector__XXX
 SG_ PCS_a025_bootromRequestStatusFla m25 : 29|1@1+ (1,0) [0|1] "" Vector__XXX
 SG_ PCS_a025_cpu2StoredAppCrcLsb16 m25 : 32|16@1+ (1,0) [0|65535] "" Vector__XXX
 SG_ PCS_a027_chgPhATemp m27 : 16|8@1- (1,40) [-88|167] "C" Vector__XXX
 SG_ PCS_a027_chgPhBTemp m27 : 24|8@1- (1,40) [-88|167] "C" Vector__XXX
 SG_ PCS_a027_chgPhCTemp m27 : 32|8@1- (1,40) [-88|167] "C" Vector__XXX
 SG_ PCS_a027_chgPhANoFlowBucket m27 : 40|5@1+ (0.2,0) [0|6.2] "-" Vector__XXX
 SG_ PCS_a027_chgPhBNoFlowBucket m27 : 48|5@1+ (0.2,0) [0|6.2] "-" Vector__XXX
 SG_ PCS_a027_chgPhCNoFlowBucket m27 : 56|5@1+ (0.2,0) [0|6.2] "-" Vector__XXX
 SG_ PCS_a028_outputV m28 : 16|10@1+ (0.5,0) [0|511.5] "V" Vector__XXX
 SG_ PCS_a028_outputVUvThreshold m28 : 26|10@1+ (0.5,0) [0|511.5] "V" Vector__XXX
 SG_ PCS_a029_inputVrms m29 : 16|9@1+ (1,0) [0|511] "V" Vector__XXX
 SG_ PCS_a029_chgInputPower m29 : 32|8@1+ (0.1,0) [0|25.5] "kW" Vector__XXX
 SG_ PCS_a029_bmsPowerCommand m29 : 40|8@1+ (0.1,0) [0|25.5] "kW" Vector__XXX
 SG_ PCS_a029_phaseConfig m29 : 48|4@1+ (1,0) [1|15] "" Vector__XXX
 SG_ PCS_a030_canRxErrorType m30 : 16|3@1+ (1,0) [0|7] "" Vector__XXX
 SG_ PCS_a030_canID m30 : 24|16@1+ (1,0) [0|65535] "" Vector__XXX
 SG_ PCS_a032_phATransientRetryCount m32 : 16|9@1+ (0.1,0) [0|51.1] "-" Vector__XXX
 SG_ PCS_a032_phBTransientRetryCount m32 : 25|9@1+ (0.1,0) [0|51.1] "-" Vector__XXX
 SG_ PCS_a032_phCTransientRetryCount m32 : 34|9@1+ (0.1,0) [0|51.1] "-" Vector__XXX
 SG_ PCS_a032_phAFaulted m32 : 43|1@1+ (1,0) [0|1] "" Vector__XXX
 SG_ PCS_a032_phBFaulted m32 : 44|1@1+ (1,0) [0|1] "" Vector__XXX
 SG_ PCS_a032_phCFaulted m32 : 45|1@1+ (1,0) [0|1] "" Vector__XXX
 SG_ PCS_a033_HV_busV m33 : 16|12@1+ (0.146484375,0) [0|599.853515625] "V" Vector__XXX
 SG_ PCS_a034_HV_busV m34 : 16|12@1+ (0.146484375,0) [0|599.853515625] "V" Vector__XXX
 SG_ PCS_a035_LV_busV m35 : 16|12@1+ (0.009765625,0) [0|39.990234375] "V" Vector__XXX
 SG_ PCS_a036_LV_busV m36 : 16|12@1+ (0.009765625,0) [0|39.990234375] "V" Vector__XXX
 SG_ PCS_a037_dcdcPwmDeassertedCount m37 : 16|8@1+ (1,0) [0|255] "" Vector__XXX
 SG_ PCS_a038_dcdcClaFaultCode m38 : 16|4@1+ (1,0) [0|15] "" Vector__XXX
 SG_ PCS_a038_dcdcSubState m38 : 20|5@1+ (1,0) [0|31] "" Vector__XXX
 SG_ PCS_a038_dcdcLvBusV m38 : 25|8@1+ (0.15625,0) [0|39.84375] "V" Vector__XXX
 SG_ PCS_a038_dcdcHvBusV m38 : 33|10@1+ (0.5859375,0) [0|599.4140625] "V" Vector__XXX
 SG_ PCS_a038_dcdcLvBusCurrent_A m38 : 43|10@1- (0.78125,0) [-400|399.21875] "A" Vector__XXX
 SG_ PCS_a038_dcdcPwmEnableDeasserted m38 : 53|7@1+ (1,0) [0|127] "" Vector__XXX
 SG_ PCS_a038_dcdcPwmEnableLine m38 : 60|1@1+ (1,0) [0|1] "" Vector__XXX
 SG_ PCS_a039_SDModuleClockFault_HV m39 : 16|1@1+ (1,0) [0|1] "" Vector__XXX
 SG_ PCS_a039_SDModuleClockFault_LV m39 : 17|1@1+ (1,0) [0|1] "" Vector__XXX
 SG_ PCS_a040_dcdcLvVoltageTarget m40 : 16|8@1+ (0.1,0) [0|25.5] "V" Vector__XXX
 SG_ PCS_a040_dcdcLvVoltage m40 : 24|8@1+ (0.1,0) [0|25.5] "V" Vector__XXX
 SG_ PCS_a040_dcdcLvOutputCurrent m40 : 32|13@1- (0.1,0) [-409.6|409.5] "A" Vector__XXX
 SG_ PCS_a041_dcdcTemperature m41 : 16|11@1- (0.1,40) [-62.4|142.3] "C" Vector__XXX
 SG_ PCS_a042_dcdcEnableLine m42 : 16|1@1+ (1,0) [0|1] "" Vector__XXX
 SG_ PCS_a042_dcdcEnableCan m42 : 17|1@1+ (1,0) [0|1] "" Vector__XXX
 SG_ PCS_a043_dcdcLvBusV m43 : 16|10@1+ (0.0390625,0) [0|39.9609375] "V" Vector__XXX
 SG_ PCS_a043_dcdcHvBusV m43 : 26|12@1+ (0.146484375,0) [0|599.853515625] "V" Vector__XXX
 SG_ PCS_a043_hvPrechargeTargetV m43 : 40|12@1+ (0.146484375,0) [0|599.853515625] "V" Vector__XXX
 SG_ PCS_a044_FaultReasonCode m44 : 16|2@1+ (1,0) [1|3] "" Vector__XXX
 SG_ PCS_a044_shortTime_us m44 : 18|10@1+ (0.0312805473804,0) [0|31.9999999701] "us" Vector__XXX
 SG_ PCS_a044_dcdcLvBusCurrent_A m44 : 28|10@1+ (0.391006857157,0) [0|400.000014872] "A" Vector__XXX
 SG_ PCS_a044_vTankPeak_abs_V m44 : 38|10@1+ (1,0) [0|1023] "V" Vector__XXX
 SG_ PCS_a045_hvBusEstimated_C_uF m45 : 16|10@1+ (7.820137,0) [0|8000.000151] "uF" Vector__XXX
 SG_ PCS_a045_hvBusEstimated_R_kOhm m45 : 26|10@1+ (0.0488758571446,0) [0|50.0000018589] "kOhm" Vector__XXX
 SG_ PCS_a046_hvBusEstimated_C_uF m46 : 16|10@1+ (7.820137,0) [0|8000.000151] "uF" Vector__XXX
 SG_ PCS_a046_hvBusEstimated_R_kOhm m46 : 26|10@1+ (0.0488758571446,0) [0|50.0000018589] "kOhm" Vector__XXX
 SG_ PCS_a047_cpu1BootLoaderCrcMismat m47 : 16|1@1+ (1,0) [0|1] "" Vector__XXX
 SG_ PCS_a047_cpu2BootLoaderCrcMismat m47 : 17|1@1+ (1,0) [0|1] "" Vector__XXX
 SG_ PCS_a047_calculatedBootloaderCrc m47 : 24|32@1+ (1,0) [0|4294967295] "" Vector__XXX
 SG_ PCS_a049_dcdcTemperature m49 : 16|11@1- (0.1,40) [-62.4|142.3] "C" Vector__XXX
 SG_ PCS_a051_phState m51 : 16|4@1+ (1,0) [0|15] "" Vector__XXX
 SG_ PCS_a051_pfcCurrentRms m51 : 20|9@1+ (0.1,0) [0|51.1] "A" Vector__XXX
 SG_ PCS_a051_llcCurrent m51 : 29|8@1+ (0.1,0) [0|25.5] "A" Vector__XXX
 SG_ PCS_a051_intBusV m51 : 37|9@1+ (1,0) [0|511] "V" Vector__XXX
 SG_ PCS_a051_intBusVTarget m51 : 46|9@1+ (1,0) [0|511] "V" Vector__XXX
 SG_ PCS_a051_intBusStaticRipple m51 : 55|6@1+ (1,0) [0|63] "V" Vector__XXX
 SG_ PCS_a052_inputVrms m52 : 16|9@1+ (1,0) [0|511] "V" Vector__XXX
 SG_ PCS_a053_inputVrms m53 : 16|9@1+ (1,0) [0|511] "V" Vector__XXX
 SG_ PCS_a053_inputIrms m53 : 25|10@1+ (0.1,0) [0|102.3] "A" Vector__XXX
 SG_ PCS_a053_acChargeCurrentLimit m53 : 40|7@1+ (1,0) [0|127] "A" Vector__XXX
 SG_ PCS_a053_startingInputVrms m53 : 47|9@1+ (1,0) [0|511] "V" Vector__XXX
 SG_ PCS_a053_phaseConfig m53 : 56|4@1+ (1,0) [1|15] "" Vector__XXX
 SG_ PCS_a054_inputVrms m54 : 16|9@1+ (1,0) [0|511] "V" Vector__XXX
 SG_ PCS_a054_inputIrms m54 : 25|10@1+ (0.1,0) [0|102.3] "A" Vector__XXX
 SG_ PCS_a054_acChargeCurrentLimit m54 : 40|7@1+ (1,0) [0|127] "A" Vector__XXX
 SG_ PCS_a054_startingInputVrms m54 : 47|9@1+ (1,0) [0|511] "V" Vector__XXX
 SG_ PCS_a054_phaseConfig m54 : 56|4@1+ (1,0) [1|15] "" Vector__XXX
 SG_ PCS_a057_inputVrms m57 : 16|10@1+ (0.5,0) [0|511.5] "V" Vector__XXX
 SG_ PCS_a057_inputFrequency m57 : 26|9@1+ (0.1,40) [40|91.1] "Hz" Vector__XXX
 SG_ PCS_a058_inputVrms m58 : 16|10@1+ (0.5,0) [0|511.5] "V" Vector__XXX
 SG_ PCS_a058_inputFrequency m58 : 26|12@1+ (0.01,40) [40|80.95] "Hz" Vector__XXX
 SG_ PCS_a059_inputVrms m59 : 16|10@1+ (0.5,0) [0|511.5] "V" Vector__XXX
 SG_ PCS_a059_inputOvRmsThreshold m59 : 26|10@1+ (0.5,0) [0|511.5] "V" Vector__XXX
 SG_ PCS_a060_inputVPeak m60 : 16|10@1+ (0.5,0) [0|511.5] "V" Vector__XXX
 SG_ PCS_a060_inputOvPeakThreshold m60 : 26|10@1+ (0.5,0) [0|511.5] "V" Vector__XXX
 SG_ PCS_a061_chgInputVdcOffset_L1N m61 : 16|8@1+ (1,0) [0|255] "V" Vector__XXX
 SG_ PCS_a061_chgInputVdcOffset_L2N m61 : 24|8@1+ (1,0) [0|255] "V" Vector__XXX
 SG_ PCS_a061_chgInputVdcOffset_L3N m61 : 32|8@1+ (1,0) [0|255] "V" Vector__XXX
 SG_ PCS_a061_chgInputVdcOffset_L1L2 m61 : 40|8@1+ (1,0) [0|255] "V" Vector__XXX
 SG_ PCS_a061_PllSourceIrrational_L1N m61 : 48|1@1+ (1,0) [0|1] "" Vector__XXX
 SG_ PCS_a061_PllSourceIrrational_L2N m61 : 49|1@1+ (1,0) [0|1] "" Vector__XXX
 SG_ PCS_a061_PllSourceIrrational_L3N m61 : 50|1@1+ (1,0) [0|1] "" Vector__XXX
 SG_ PCS_a061_PllSourceIrrational_L1L m61 : 51|1@1+ (1,0) [0|1] "" Vector__XXX
 SG_ PCS_a062_chgInputIOffset m62 : 16|12@1- (0.01,0) [-20.48|20.47] "A" Vector__XXX
 SG_ PCS_a063_chgOutputV m63 : 16|10@1+ (1,0) [0|1023] "V" Vector__XXX
 SG_ PCS_a063_hvpHvLinkVoltage m63 : 26|11@1- (1,0) [-1024|1023] "V" Vector__XXX
 SG_ PCS_a064_chgOutputIOffset m64 : 16|12@1- (0.01,0) [-20.48|20.47] "A" Vector__XXX
 SG_ PCS_a065_inputVrms m65 : 16|10@1+ (0.5,0) [0|511.5] "V" Vector__XXX
 SG_ PCS_a065_inputFrequency m65 : 26|9@1+ (0.1,40) [40|91.1] "Hz" Vector__XXX
 SG_ PCS_a066_dcdcHvBusVolt m66 : 16|14@1+ (0.1,0) [0|1638.3] "V" Vector__XXX
 SG_ PCS_a066_hvpHvLinkVoltage m66 : 32|11@1- (1,0) [-1024|1023] "V" Vector__XXX
 SG_ PCS_a067_dcdcLvBusVolt m67 : 16|13@1+ (0.01,0) [0|81.91] "V" Vector__XXX
 SG_ PCS_a067_vcfrontPcsEFuseV m67 : 29|10@1+ (0.1,0) [0|102.2] "V" Vector__XXX
 SG_ PCS_a067_vcfrontVcrightVoltage m67 : 40|10@1+ (0.1,0) [0|102.2] "V" Vector__XXX
 SG_ PCS_a068_dcdcTankVolt m68 : 16|16@1- (0.030517578125,0) [-1000|999.969482422] "V" Vector__XXX
 SG_ PCS_a068_dcdcTankVoltOffset m68 : 32|16@1- (0.00152587890625,0) [-50|49.9984741211] "V" Vector__XXX
 SG_ PCS_a069_phState m69 : 16|4@1+ (1,0) [0|15] "" Vector__XXX
 SG_ PCS_a069_inputIDelta m69 : 20|10@1+ (0.1,0) [0|102.3] "A" Vector__XXX
 SG_ PCS_a069_inputVrms m69 : 30|10@1+ (0.5,0) [0|511.5] "V" Vector__XXX
 SG_ PCS_a069_intBusV m69 : 40|9@1+ (1,0) [0|511] "V" Vector__XXX
 SG_ PCS_a069_inputFrequency m69 : 49|9@1+ (0.1,40) [40|91.1] "Hz" Vector__XXX
 SG_ PCS_a070_phState m70 : 16|4@1+ (1,0) [0|15] "" Vector__XXX
 SG_ PCS_a070_inputVDelta m70 : 20|10@1+ (0.1,0) [0|102.3] "V" Vector__XXX
 SG_ PCS_a070_inputVrms m70 : 30|10@1+ (0.5,0) [0|511.5] "V" Vector__XXX
 SG_ PCS_a070_intBusV m70 : 40|9@1+ (1,0) [0|511] "V" Vector__XXX
 SG_ PCS_a070_inputFrequency m70 : 49|9@1+ (0.1,40) [40|91.1] "Hz" Vector__XXX
 SG_ PCS_a071_phState m71 : 16|4@1+ (1,0) [0|15] "" Vector__XXX
 SG_ PCS_a071_inputVrms m71 : 20|10@1+ (0.5,0) [0|511.5] "V" Vector__XXX
 SG_ PCS_a071_intBusV m71 : 30|9@1+ (1,0) [0|511] "V" Vector__XXX
 SG_ PCS_a071_inputFrequency m71 : 39|9@1+ (0.1,40) [40|91.1] "Hz" Vector__XXX
 SG_ PCS_a071_llcFrequency m71 : 48|8@1+ (1,50) [50|305] "kHz" Vector__XXX
 SG_ PCS_a072_task1Stopped m72 : 16|1@1+ (1,0) [0|1] "" Vector__XXX
 SG_ PCS_a072_task2Stopped m72 : 17|1@1+ (1,0) [0|1] "" Vector__XXX
 SG_ PCS_a073_inputL1NVrms m73 : 16|9@1+ (1,0) [0|511] "V" Vector__XXX
 SG_ PCS_a073_inputL2NVrms m73 : 25|9@1+ (1,0) [0|511] "V" Vector__XXX
 SG_ PCS_a073_inputL3NVrms m73 : 34|9@1+ (1,0) [0|511] "V" Vector__XXX
 SG_ PCS_a073_inputNGVrms m73 : 43|9@1+ (1,0) [0|511] "V" Vector__XXX
 SG_ PCS_a073_phaseConfig m73 : 52|4@1+ (1,0) [1|15] "" Vector__XXX
 SG_ PCS_a073_cpType m73 : 56|2@1+ (1,0) [0|3] "" Vector__XXX
 SG_ PCS_a074_dcdcLvBusV m74 : 16|10@1+ (0.0390625,0) [0|39.9609375] "V" Vector__XXX
 SG_ PCS_a074_dcdcHvBusV m74 : 26|12@1+ (0.146484375,0) [0|599.853515625] "V" Vector__XXX
 SG_ PCS_a075_dcdcLvBusV m75 : 16|10@1+ (0.0390625,0) [0|39.9609375] "V" Vector__XXX
 SG_ PCS_a075_dcdcHvBusV m75 : 26|12@1+ (0.146484375,0) [0|599.853515625] "V" Vector__XXX
 SG_ PCS_a075_dcdcSubState m75 : 40|5@1+ (1,0) [0|31] "" Vector__XXX
 SG_ PCS_a076_pcsControlRequest m76 : 16|2@1+ (1,0) [0|3] "" Vector__XXX
 SG_ PCS_a076_dcdcSubState m76 : 18|5@1+ (1,0) [0|31] "" Vector__XXX
 SG_ PCS_a076_dcdcEnableLine m76 : 23|1@1+ (1,0) [0|1] "" Vector__XXX
 SG_ PCS_a076_dcdcPwmEnableDeasserted m76 : 24|8@1+ (1,0) [0|255] "" Vector__XXX
 SG_ PCS_a078_phaTemperature m78 : 16|8@1- (1,40) [-88|167] "C" Vector__XXX
 SG_ PCS_a078_phbTemperature m78 : 24|8@1- (1,40) [-88|167] "C" Vector__XXX
 SG_ PCS_a078_phcTemperature m78 : 32|8@1- (1,40) [-88|167] "C" Vector__XXX
 SG_ PCS_a078_dcdcTemperature m78 : 40|8@1- (1,40) [-88|167] "C" Vector__XXX
 SG_ PCS_a078_ptCoolantTemp m78 : 48|8@1- (1,40) [-88|167] "C" Vector__XXX
 SG_ PCS_a079_eepromOperation m79 : 16|4@1+ (1,0) [0|14] "" Vector__XXX
 SG_ PCS_a079_eepromOperationRegion m79 : 20|2@1+ (1,0) [0|3] "" Vector__XXX
 SG_ PCS_a079_recordID m79 : 24|8@1+ (1,0) [0|255] "" Vector__XXX
 SG_ PCS_a079_eepromOperationErrorCod m79 : 32|5@1+ (1,0) [0|31] "" Vector__XXX
 SG_ PCS_a079_operationAddress m79 : 40|16@1+ (1,0) [0|65535] "" Vector__XXX
 SG_ PCS_a079_eepromErrorCount m79 : 56|5@1+ (1,0) [0|31] "" Vector__XXX
 SG_ PCS_a080_phADamaged m80 : 16|1@1+ (1,0) [0|1] "" Vector__XXX
 SG_ PCS_a080_phBDamaged m80 : 17|1@1+ (1,0) [0|1] "" Vector__XXX
 SG_ PCS_a080_phCDamaged m80 : 18|1@1+ (1,0) [0|1] "" Vector__XXX
 SG_ PCS_a080_phANVRAMStoredState m80 : 19|3@1+ (1,0) [0|7] "" Vector__XXX
 SG_ PCS_a080_phBNVRAMStoredState m80 : 24|3@1+ (1,0) [0|7] "" Vector__XXX
 SG_ PCS_a080_phCNVRAMStoredState m80 : 27|3@1+ (1,0) [0|7] "" Vector__XXX
 SG_ PCS_a081_dcdcLvBusV m81 : 16|10@1+ (0.0390625,0) [0|39.9609375] "V" Vector__XXX
 SG_ PCS_a081_dcdcHvBusV m81 : 26|12@1+ (0.146484375,0) [0|599.853515625] "V" Vector__XXX
 SG_ PCS_a081_faultedSubstate m81 : 40|5@1+ (1,0) [0|31] "" Vector__XXX
 SG_ PCS_a082_dcdcLvBusV m82 : 16|10@1+ (0.0390625,0) [0|39.9609375] "V" Vector__XXX
 SG_ PCS_a082_dcdcHvBusV m82 : 26|12@1+ (0.146484375,0) [0|599.853515625] "V" Vector__XXX
 SG_ PCS_a082_faultedSubstate m82 : 40|5@1+ (1,0) [0|31] "" Vector__XXX
 SG_ PCS_a085_dcdcHalfPeriodUs m85 : 16|16@1+ (0.005,0) [0|327.675] "us" Vector__XXX
 SG_ PCS_a086_dcdcTemperature m86 : 16|12@1- (0.1,0) [-204.8|204.7] "C" Vector__XXX
 SG_ PCS_a086_pcsAmbientTemperature m86 : 28|12@1- (0.1,0) [-204.8|204.7] "C" Vector__XXX
 SG_ PCS_a086_vcfrontPTCoolantTemp m86 : 40|12@1- (0.1,0) [-204.8|204.7] "C" Vector__XXX
 SG_ PCS_a088_gridConfig m88 : 16|4@1+ (1,0) [1|15] "" Vector__XXX
 SG_ PCS_a088_phAFrequency m88 : 20|12@1+ (0.01,40) [40|80.95] "Hz" Vector__XXX
 SG_ PCS_a088_phBFrequency m88 : 32|12@1+ (0.01,40) [40|80.95] "Hz" Vector__XXX
 SG_ PCS_a088_phCFrequency m88 : 44|12@1+ (0.01,40) [40|80.95] "Hz" Vector__XXX
 SG_ PCS_a089_hvSlewRate m89 : 16|8@1- (2,0) [-256|254] "V/sec" Vector__XXX
 SG_ PCS_a089_avgSlewRate m89 : 24|8@1- (2,0) [-256|254] "V/sec" Vector__XXX
 SG_ PCS_a089_G m89 : 32|4@1+ (0.2,0) [0|3] "-" Vector__XXX
 SG_ PCS_a089_HV_busV m89 : 36|9@1+ (0.8203125,0) [0|419.1796875] "V" Vector__XXX
 SG_ PCS_a089_PhaseShift m89 : 45|5@1+ (0.5,0) [0|15.5] "-" Vector__XXX
 SG_ PCS_a089_Freq m89 : 50|9@1+ (1,0) [0|511] "kHz" Vector__XXX
 SG_ PCS_a089_fastDischargeMode m89 : 59|1@1+ (1,0) [0|1] "" Vector__XXX
 SG_ PCS_a089_slowDischargeMode m89 : 60|1@1+ (1,0) [0|1] "" Vector__XXX
 SG_ PCS_a090_vRmsL1N m90 : 16|9@1+ (1,0) [0|511] "V" Vector__XXX
 SG_ PCS_a090_vRmsL2N m90 : 25|9@1+ (1,0) [0|511] "V" Vector__XXX
 SG_ PCS_a090_vRmsL3N m90 : 34|9@1+ (1,0) [0|511] "V" Vector__XXX
 SG_ PCS_a090_vRmsL1L2 m90 : 43|9@1+ (1,0) [0|511] "V" Vector__XXX
 SG_ PCS_a090_evaluatedGridConfig m90 : 52|4@1+ (1,0) [1|15] "" Vector__XXX
 SG_ PCS_a090_phASourceMissing m90 : 56|1@1+ (1,0) [0|1] "" Vector__XXX
 SG_ PCS_a090_phBSourceMissing m90 : 57|1@1+ (1,0) [0|1] "" Vector__XXX
 SG_ PCS_a090_phCSourceMissing m90 : 58|1@1+ (1,0) [0|1] "" Vector__XXX
 SG_ PCS_a091_intBusTarget m91 : 16|9@1+ (1,0) [0|511] "V" Vector__XXX
 SG_ PCS_a091_intBusMaxRippleLevel m91 : 25|9@1+ (0.1,0) [0|51.1] "V" Vector__XXX
 SG_ PCS_a091_pfcCurrentIrms m91 : 34|8@1+ (0.1,0) [0|25.5] "A" Vector__XXX
 SG_ PCS_a091_phaseInputVrms m91 : 42|9@1+ (1,0) [0|511] "A" Vector__XXX
 SG_ PCS_a091_phaseTemp m91 : 51|8@1- (1,0) [-128|127] "C" Vector__XXX
 SG_ PCS_a092_pfcIrmsPhA m92 : 16|7@1+ (0.2,0) [0|25.4] "A" Vector__XXX
 SG_ PCS_a092_pfcIrmsPhB m92 : 23|7@1+ (0.2,0) [0|25.4] "A" Vector__XXX
 SG_ PCS_a092_pfcIrmsPhC m92 : 30|7@1+ (0.2,0) [0|25.4] "A" Vector__XXX
 SG_ PCS_a092_chgTempPhA m92 : 37|8@1- (1,40) [-88|167] "C" Vector__XXX
 SG_ PCS_a092_chgTempPhB m92 : 45|8@1- (1,40) [-88|167] "C" Vector__XXX
 SG_ PCS_a092_chgTempPhC m92 : 53|8@1- (1,40) [-88|167] "C" Vector__XXX
 SG_ PCS_a093_powerRail5VN m93 : 16|10@1+ (0.01,0) [0|10.23] "V" Vector__XXX
 SG_ PCS_a093_powerRail3V3 m93 : 26|10@1+ (0.01,0) [0|10.23] "V" Vector__XXX
 SG_ PCS_a093_powerRail1V5 m93 : 40|8@1+ (0.01,0) [0|2.55] "V" Vector__XXX
 SG_ PCS_a093_powerRail1V2 m93 : 48|8@1+ (0.01,0) [0|2.55] "V" Vector__XXX
 SG_ PCS_a093_irrational1V2Rail m93 : 56|1@1+ (1,0) [0|1] "" Vector__XXX
 SG_ PCS_a093_irrational1V5Rail m93 : 57|1@1+ (1,0) [0|1] "" Vector__XXX
 SG_ PCS_a093_irrational3V3Rail m93 : 58|1@1+ (1,0) [0|1] "" Vector__XXX
 SG_ PCS_a093_irrational5VNRail m93 : 59|1@1+ (1,0) [0|1] "" Vector__XXX
 SG_ PCS_a094_malfunctionCode m94 : 16|2@1+ (1,0) [0|3] "" Vector__XXX
 SG_ PCS_a095_powerRail5VN m95 : 16|10@1+ (0.01,0) [0|10.23] "V" Vector__XXX
 SG_ PCS_a095_pcsControlRequest m95 : 26|2@1+ (1,0) [0|3] "" Vector__XXX
 SG_ PCS_a096_gridConfig m96 : 16|4@1+ (1,0) [1|15] "" Vector__XXX
 SG_ PCS_a096_phAFrequency m96 : 20|12@1+ (0.01,40) [40|80.95] "Hz" Vector__XXX
 SG_ PCS_a096_phBFrequency m96 : 32|12@1+ (0.01,40) [40|80.95] "Hz" Vector__XXX
 SG_ PCS_a096_phCFrequency m96 : 44|12@1+ (0.01,40) [40|80.95] "Hz" Vector__XXX
 SG_ PCS_a097_phADamaged m97 : 16|1@1+ (1,0) [0|1] "" Vector__XXX
 SG_ PCS_a097_phBDamaged m97 : 17|1@1+ (1,0) [0|1] "" Vector__XXX
 SG_ PCS_a097_phCDamaged m97 : 18|1@1+ (1,0) [0|1] "" Vector__XXX
 SG_ PCS_a097_phANVRAMStoredState m97 : 19|3@1+ (1,0) [0|7] "" Vector__XXX
 SG_ PCS_a097_phBNVRAMStoredState m97 : 24|3@1+ (1,0) [0|7] "" Vector__XXX
 SG_ PCS_a097_phCNVRAMStoredState m97 : 27|3@1+ (1,0) [0|7] "" Vector__XXX
 SG_ PCS_a100_inputVrms m100 : 16|9@1+ (1,0) [0|511] "V" Vector__XXX
 SG_ PCS_a100_phIntBusVolt m100 : 25|9@1+ (1,0) [0|511] "V" Vector__XXX
 SG_ PCS_a100_phKwhCounter m100 : 34|13@1+ (1,0) [0|8191] "kwh" Vector__XXX
 SG_ PCS_a100_phKwhCounterDeltaFromMa m100 : 48|13@1+ (1,0) [0|8191] "kwh" Vector__XXX
 SG_ PCS_a102_pcsControlRequest m102 : 16|2@1+ (1,0) [0|3] "" Vector__XXX
 SG_ PCS_a102_NMIFlagRegisters m102 : 18|11@1+ (1,0) [0|2047] "" Vector__XXX
 SG_ PCS_a102_systemResetRegisters m102 : 29|11@1+ (1,0) [0|2047] "" Vector__XXX
 SG_ PCS_a102_dcdcEnableLine m102 : 40|1@1+ (1,0) [0|1] "" Vector__XXX
 SG_ PCS_a104_ambientTemperature m104 : 16|11@1- (0.1,40) [-62.4|142.3] "C" Vector__XXX
 SG_ PCS_a107_VC_pcsInterface m107 : 16|1@1+ (1,0) [0|1] "" Vector__XXX
 SG_ PCS_a108_installedInAWrongPlatfo m108 : 16|1@1+ (1,0) [0|1] "" Vector__XXX
 SG_ PCS_a109_inputL2NVrms m109 : 16|9@1+ (1,0) [0|511] "V" Vector__XXX
 SG_ PCS_a109_inputL3NVrms m109 : 25|9@1+ (1,0) [0|511] "V" Vector__XXX

BO_TX_BU_ 1962 : HVP;
BO_TX_BU_ 554 : HVP;
BO_TX_BU_ 784 : HVP;
BO_TX_BU_ 1914 : HVP;
BO_TX_BU_ 1208 : ICR;
BO_TX_BU_ 952 : ICR;
BO_TX_BU_ 941 : ICR;
BO_TX_BU_ 536 : ICR;
BO_TX_BU_ 670 : ICR;
BO_TX_BU_ 664 : ICR;
BO_TX_BU_ 1012 : GTW;
BO_TX_BU_ 1060 : PCS;
CM_ BO_ 1962 "High-voltage processor (pack contactor and isolation controller) message: debug message";
CM_ SG_ 1962 HVP_debugMessageMultiplexer "High-voltage processor (pack contactor and isolation controller): debug message multiplexer";
CM_ SG_ 1962 HVP_gpioPassivePyroDepl "High-voltage processor (pack contactor and isolation controller): gpio passive pyro depl";
CM_ SG_ 1962 HVP_gpioPyroIsoEn "High-voltage processor (pack contactor and isolation controller): gpio pyro iso en";
CM_ SG_ 1962 HVP_gpioCpFaultIn "High-voltage processor (pack contactor and isolation controller): gpio cp fault in";
CM_ SG_ 1962 HVP_gpioPackContPowerEn "High-voltage processor (pack contactor and isolation controller): gpio pack cont power en";
CM_ SG_ 1962 HVP_gpioHvCablesOk "CPIL fault monitoring signal";
CM_ SG_ 1962 HVP_gpioHvpSelfEnable "High-voltage processor (pack contactor and isolation controller): gpio hvp self enable";
CM_ SG_ 1962 HVP_gpioLed "High-voltage processor (pack contactor and isolation controller): gpio led";
CM_ SG_ 1962 HVP_gpioCrashSignal "Crash signal from RCM";
CM_ SG_ 1962 HVP_gpioShuntDataReady "High-voltage processor (pack contactor and isolation controller): gpio shunt data ready";
CM_ SG_ 1962 HVP_gpioFcContPosAux "Aux contact line from positive FC contactor";
CM_ SG_ 1962 HVP_gpioFcContNegAux "Aux contact line from negative FC contactor";
CM_ SG_ 1962 HVP_gpioBmsEout "High-voltage processor (pack contactor and isolation controller): gpio bms eout";
CM_ SG_ 1962 HVP_gpioCpFaultOut "High-voltage processor (pack contactor and isolation controller): gpio cp fault out";
CM_ SG_ 1962 HVP_gpioPyroPor "High-voltage processor (pack contactor and isolation controller): gpio pyro por";
CM_ SG_ 1962 HVP_gpioShuntEn "High-voltage processor (pack contactor and isolation controller): gpio shunt en";
CM_ SG_ 1962 HVP_gpioHvpVerEn "High-voltage processor (pack contactor and isolation controller): gpio hvp ver en";
CM_ SG_ 1962 HVP_gpioFcContFlywheelEnable "High-voltage processor (pack contactor and isolation controller): gpio fc cont flywheel enable";
CM_ SG_ 1962 HVP_gpioCpLatchEnable "High-voltage processor (pack contactor and isolation controller): gpio cp latch enable";
CM_ SG_ 1962 HVP_gpioFcContPowerEnable "High-voltage processor (pack contactor and isolation controller): gpio fc cont power enable";
CM_ SG_ 1962 HVP_gpioHvilEnable "High-voltage processor (pack contactor and isolation controller): gpio hvil enable";
CM_ SG_ 1962 HVP_gpioPortSelSpiRdy "High-voltage processor (pack contactor and isolation controller): gpio port sel spi rdy";
CM_ SG_ 1962 HVP_gpioPyroUnlock "High-voltage processor (pack contactor and isolation controller): gpio pyro unlock";
CM_ SG_ 1962 HVP_hvp1v5Ref "High-voltage processor (pack contactor and isolation controller): hvp1v5 ref";
CM_ SG_ 1962 HVP_packCurrentMia "High-voltage processor (pack contactor and isolation controller): pack current mia";
CM_ SG_ 1962 HVP_auxCurrentMia "High-voltage processor (pack contactor and isolation controller): aux current mia";
CM_ SG_ 1962 HVP_currentSenseMia "High-voltage processor (pack contactor and isolation controller): current sense mia";
CM_ SG_ 1962 HVP_shuntRefVoltageMismatch "High-voltage processor (pack contactor and isolation controller): shunt ref voltage mismatch";
CM_ SG_ 1962 HVP_shuntThermistorMissing "High-voltage processor (pack contactor and isolation controller): shunt thermistor missing";
CM_ SG_ 1962 HVP_shuntThermistorExpected "High-voltage processor (pack contactor and isolation controller): shunt thermistor expected";
CM_ SG_ 1962 HVP_shuntThermistorMia "High-voltage processor (pack contactor and isolation controller): shunt thermistor mia";
CM_ SG_ 1962 HVP_shuntUnexpectedThermistor "High-voltage processor (pack contactor and isolation controller): shunt unexpected thermistor";
CM_ SG_ 1962 HVP_shuntHwMia "High-voltage processor (pack contactor and isolation controller): shunt hw mia";
CM_ SG_ 1962 HVP_shuntCurrentIrrational "High-voltage processor (pack contactor and isolation controller): shunt current irrational";
CM_ SG_ 1962 HVP_shuntAsicTCompActive "High-voltage processor (pack contactor and isolation controller): shunt asic t comp active";
CM_ SG_ 1962 HVP_ecuLogUploadRequest "High-voltage processor (pack contactor and isolation controller): ecu log upload request";
CM_ SG_ 1962 HVP_packContVoltage "High-voltage processor (pack contactor and isolation controller): pack cont voltage";
CM_ SG_ 1962 HVP_packNegativeV "The HVP's common-mode measurement of PACK-HV-SENSE-NEG relative to chassis ground";
CM_ SG_ 1962 HVP_packPositiveV "The HVP's common-mode measurement of PACK-HV-SENSE-POS relative to chassis ground";
CM_ SG_ 1962 HVP_pyroAnalog "High-voltage processor (pack contactor and isolation controller): pyro analog";
CM_ SG_ 1962 HVP_fcContCoilCurrent "High-voltage processor (pack contactor and isolation controller): fc cont coil current";
CM_ SG_ 1962 HVP_fcContVoltage "High-voltage processor (pack contactor and isolation controller): fc cont voltage";
CM_ SG_ 1962 HVP_hvilInVoltage "Measured HVIL input voltage";
CM_ SG_ 1962 HVP_hvilOutVoltage "Measured HVIL output voltage";
CM_ SG_ 1962 HVP_shuntGainInvalidCountDbg "High-voltage processor (pack contactor and isolation controller): shunt gain invalid count dbg";
CM_ SG_ 1962 HVP_fcLinkPositiveV "High-voltage processor (pack contactor and isolation controller): fc link positive v";
CM_ SG_ 1962 HVP_packContCoilCurrent "High-voltage processor (pack contactor and isolation controller): pack cont coil current";
CM_ SG_ 1962 HVP_battery12V "Monitored voltage sense of 12V battery";
CM_ SG_ 1962 HVP_shuntRefVoltageDbg "High-voltage processor (pack contactor and isolation controller): shunt ref voltage dbg";
CM_ BO_ 554 "High-voltage processor (pack contactor and isolation controller) message: hvs control";
CM_ SG_ 554 HVP_dcLinkVoltageRequest "High-voltage processor (pack contactor and isolation controller): dc link voltage request";
CM_ SG_ 554 HVP_pcsControlRequest "The operating state that the HVP would like the PCS to be in";
CM_ SG_ 554 HVP_pcsChargeHwEnabled "The state of the PCS's charge enable line";
CM_ SG_ 554 HVP_pcsDcdcHwEnabled "The state of the PCS's DCDC enable line";
CM_ SG_ 554 HVP_dcLinkVoltageFiltered "High-voltage processor (pack contactor and isolation controller): dc link voltage filtered; raw 1498 = signal not available (SNA)";
CM_ BO_ 784 "High-voltage processor (pack contactor and isolation controller) message: info";
CM_ SG_ 784 HVP_infoIndex "High-voltage processor (pack contactor and isolation controller): info index";
CM_ SG_ 784 HVP_buildType "High-voltage processor (pack contactor and isolation controller): build type";
CM_ SG_ 784 HVP_buildConfigId "High-voltage processor (pack contactor and isolation controller): build config id";
CM_ SG_ 784 HVP_hardwareId "High-voltage processor (pack contactor and isolation controller): hardware id";
CM_ SG_ 784 HVP_componentId "High-voltage processor (pack contactor and isolation controller): component id";
CM_ SG_ 784 HVP_pcbaId "High-voltage processor (pack contactor and isolation controller): pcba id";
CM_ SG_ 784 HVP_assemblyId "HVP's assigned assembly ID";
CM_ SG_ 784 HVP_usageId "HVP's assigned usage ID";
CM_ SG_ 784 HVP_subUsageId "HVP's assigned subusage ID";
CM_ SG_ 784 HVP_platformType "High-voltage processor (pack contactor and isolation controller): platform type";
CM_ SG_ 784 HVP_appCrc "High-voltage processor (pack contactor and isolation controller): app crc";
CM_ SG_ 784 HVP_appGitHash "High-voltage processor (pack contactor and isolation controller): app git hash";
CM_ SG_ 784 HVP_bootGitHash "High-voltage processor (pack contactor and isolation controller): boot git hash";
CM_ SG_ 784 HVP_bootUdsProtoVersion "High-voltage processor (pack contactor and isolation controller): boot uds proto version";
CM_ SG_ 784 HVP_bootCrc "High-voltage processor (pack contactor and isolation controller): boot crc";
CM_ BO_ 1914 "High-voltage processor (pack contactor and isolation controller) message: log1hz";
CM_ SG_ 1914 HVP_log1HzIndex "High-voltage processor (pack contactor and isolation controller): log1 hz index";
CM_ SG_ 1914 HVP_bmbAsicType "The BMB Asic type being used by this battery pack for reading brick data";
CM_ SG_ 1914 HVP_shuntCurrentAuxLog "High-voltage processor (pack contactor and isolation controller): shunt current aux log";
CM_ SG_ 1914 HVP_pyroSquibResistance "The pyro resistance measured on attempt to close contactor or by the Pyro selftest; raw 65535 = signal not available (SNA)";
CM_ SG_ 1914 HVP_shuntAsicChipXCoordinate "High-voltage processor (pack contactor and isolation controller): shunt asic chip x coordinate";
CM_ SG_ 1914 HVP_shuntAsicChipYCoordinate "High-voltage processor (pack contactor and isolation controller): shunt asic chip y coordinate";
CM_ SG_ 1914 HVP_hvilCalType "High-voltage processor (pack contactor and isolation controller): hvil cal type";
CM_ SG_ 1914 HVP_gpioPcsDcdcPwmEnable "High-voltage processor (pack contactor and isolation controller): gpio pcs dcdc pwm enable";
CM_ SG_ 1914 HVP_gpioPcsChargePwmEnable "High-voltage processor (pack contactor and isolation controller): gpio pcs charge pwm enable";
CM_ SG_ 1914 HVP_gpioPcsEnable "HVP GPIO control for PCS logic power enable line";
CM_ SG_ 1914 HVP_shuntAsicChipWaferNumber "High-voltage processor (pack contactor and isolation controller): shunt asic chip wafer number";
CM_ SG_ 1914 HVP_energyReserveMin "a lowest energy reserve value measured over sliding window";
CM_ SG_ 1914 HVP_energyReserveMax "a highest energy reserve value measured over sliding window";
CM_ SG_ 1914 HVP_energyReserveAvg "an average energy reserve value measured over sliding window";
CM_ BO_ 1208 "ICR ECU message: alert log";
CM_ SG_ 1208 ICR_alertID "ICR ECU: alert ID";
CM_ SG_ 1208 ICR_alertState "ICR ECU: alert state";
CM_ SG_ 1208 ICR_a001_watchdogTaskAppDPM "ICR ECU: a001 watchdog task app DPM";
CM_ SG_ 1208 ICR_a001_watchdogTaskMMWControl "ICR ECU: a001 watchdog task MMW control";
CM_ SG_ 1208 ICR_a001_watchdogTaskSentinelInt "ICR ECU: a001 watchdog task sentinel interface";
CM_ SG_ 1208 ICR_a001_watchdogTaskSentinelMod "ICR ECU: a001 watchdog task sentinel mode change";
CM_ SG_ 1208 ICR_a001_watchdogTaskComTXRAD "ICR ECU: a001 watchdog task com TXRAD";
CM_ SG_ 1208 ICR_a001_watchdogTaskComRX "ICR ECU: a001 watchdog task com RX";
CM_ SG_ 1208 ICR_a001_watchdogTaskComTXVEH "ICR ECU: a001 watchdog task com TXVEH";
CM_ SG_ 1208 ICR_a001_watchdogTaskComUDS "ICR ECU: a001 watchdog task com UDS";
CM_ SG_ 1208 ICR_a001_watchdogTaskCommonError "ICR ECU: a001 watchdog task common error";
CM_ SG_ 1208 ICR_a001_watchdogTaskUARTLog "ICR ECU: a001 watchdog task UART log";
CM_ SG_ 1208 ICR_a001_watchdogTaskDataDump "ICR ECU: a001 watchdog task data dump";
CM_ SG_ 1208 ICR_a001_watchdogRTOSAppRun10MS "ICR ECU: a001 watchdog RTOS app run10 MS";
CM_ SG_ 1208 ICR_a001_watchdogRTOSAppRun1MS "ICR ECU: a001 watchdog RTOS app run1 MS";
CM_ SG_ 1208 ICR_a001_InternalWatchdog "ICR ECU: a001 internal watchdog";
CM_ SG_ 1208 ICR_a002_CPUUndervoltage "ICR ECU: a002 CPU undervoltage";
CM_ SG_ 1208 ICR_a002_PowerOnReset "ICR ECU: a002 power on reset";
CM_ SG_ 1208 ICR_a015_NVMMMemOverflow "ICR ECU: a015 NVMM mem overflow";
CM_ SG_ 1208 ICR_a015_NVMMFilesystemError "ICR ECU: a015 NVMM filesystem error";
CM_ SG_ 1208 ICR_a015_NVMMRecordIDError "ICR ECU: a015 NVMM record ID error";
CM_ SG_ 1208 ICR_a059_voltageDrop "ICR ECU: a059 voltage drop";
CM_ SG_ 1208 ICR_a059_resistanceEstimate "ICR ECU: a059 resistance estimate";
CM_ SG_ 1208 ICR_a059_current "ICR ECU: a059 current";
CM_ SG_ 1208 ICR_a063_switchChannel "ICR ECU: a063 switch channel";
CM_ SG_ 1208 ICR_a063_switchType "ICR ECU: a063 switch type";
CM_ SG_ 1208 ICR_a063_ADCVoltage "ICR ECU: a063 ADC voltage";
CM_ SG_ 1208 ICR_a063_disconnected "ICR ECU: a063 disconnected";
CM_ SG_ 1208 ICR_a063_indeterminate "ICR ECU: a063 indeterminate";
CM_ SG_ 1208 ICR_a063_stuckActive "ICR ECU: a063 stuck active";
CM_ SG_ 1208 ICR_a063_faulted "ICR ECU: a063 faulted";
CM_ SG_ 1208 ICR_a133_nearClutter "ICR ECU: a133 near clutter";
CM_ SG_ 1208 ICR_a133_farClutter "ICR ECU: a133 far clutter";
CM_ SG_ 1208 ICR_a137_nearClutter "ICR ECU: a137 near clutter";
CM_ SG_ 1208 ICR_a137_farClutter "ICR ECU: a137 far clutter";
CM_ SG_ 1208 ICR_a139_nearClutter "ICR ECU: a139 near clutter";
CM_ SG_ 1208 ICR_a139_farClutter "ICR ECU: a139 far clutter";
CM_ BO_ 952 "ICR ECU message: alert matrix";
CM_ SG_ 952 ICR_matrixIndex "ICR ECU: matrix index";
CM_ SG_ 952 ICR_a001_WatchdogReset "ICR ECU: a001 watchdog reset";
CM_ SG_ 952 ICR_a002_PowerLossReset "ICR ECU: a002 power loss reset";
CM_ SG_ 952 ICR_a003_SWAssertion "ICR ECU: a003 SW assertion";
CM_ SG_ 952 ICR_a005_CANTXError "ICR ECU: a005 CANTX error";
CM_ SG_ 952 ICR_a006_CANTX_cyclicError "ICR ECU: a006 CANTX cyclic error";
CM_ SG_ 952 ICR_a012_CPUReset "ICR ECU: a012 CPU reset";
CM_ SG_ 952 ICR_a013_AlertManagerFault "ICR ECU: a013 alert manager fault";
CM_ SG_ 952 ICR_a015_NVMMError "ICR ECU: a015 NVMM error";
CM_ SG_ 952 ICR_a016_NVMMRecordError "ICR ECU: a016 NVMM record error";
CM_ SG_ 952 ICR_a021_TaskSchedulerError "ICR ECU: a021 task scheduler error";
CM_ SG_ 952 ICR_a022_TaskInitError "ICR ECU: a022 task init error";
CM_ SG_ 952 ICR_a029_CoreDump "ICR ECU: a029 core dump";
CM_ SG_ 952 ICR_a030_ECULogUploadRequest "ICR ECU: a030 ECU log upload request";
CM_ SG_ 952 ICR_a031_UDSActive "ICR ECU: a031 UDS active";
CM_ SG_ 952 ICR_a041_HighCPULoad "ICR ECU: a041 high CPU load";
CM_ SG_ 952 ICR_a042_HighStackUsage "ICR ECU: a042 high stack usage";
CM_ SG_ 952 ICR_a043_Task1msError "ICR ECU: a043 task1ms error";
CM_ SG_ 952 ICR_a044_Task10msError "ICR ECU: a044 task10ms error";
CM_ SG_ 952 ICR_a045_Task100msError "ICR ECU: a045 task100ms error";
CM_ SG_ 952 ICR_a046_Task1000msError "ICR ECU: a046 task1000ms error";
CM_ SG_ 952 ICR_a058_inputRHighSyncDebug "ICR ECU: a058 input r high sync debug";
CM_ SG_ 952 ICR_a059_inputResistanceHigh "ICR ECU: a059 input resistance high";
CM_ SG_ 952 ICR_a060_engineeringBuild "ICR ECU: a060 engineering build";
CM_ SG_ 952 ICR_a061_XCPConnected "ICR ECU: a061 XCP connected";
CM_ SG_ 952 ICR_a062_XCPWasConnected "ICR ECU: a062 XCP was connected";
CM_ SG_ 952 ICR_a063_SwitchFault "ICR ECU: a063 switch fault";
CM_ SG_ 952 ICR_a064_busSleepReqTimeout "ICR ECU: a064 bus sleep req timeout";
CM_ SG_ 952 ICR_a133_radarBlocked "ICR ECU: a133 radar blocked";
CM_ SG_ 952 ICR_a134_radarPgood "ICR ECU: a134 radar pgood";
CM_ SG_ 952 ICR_a135_radarTxBallBreak "ICR ECU: a135 radar tx ball break";
CM_ SG_ 952 ICR_a136_radarHighTemperature "ICR ECU: a136 radar high temperature";
CM_ SG_ 952 ICR_a137_radarBlocked "ICR ECU: a137 radar blocked";
CM_ SG_ 952 ICR_a138_DriverSideMismatch "ICR ECU: a138 driver side mismatch";
CM_ SG_ 952 ICR_a139_AbnormalBlockageDetecte "ICR ECU: a139 abnormal blockage detected";
CM_ SG_ 952 ICR_a140_OccupancyExceptionEncou "ICR ECU: a140 occupancy exception encountered";
CM_ SG_ 952 ICR_a141_RequiresReplacement "ICR ECU: a141 requires replacement";
CM_ SG_ 952 ICR_a142_ModeOverrideActive "ICR ECU: a142 mode override active";
CM_ BO_ 941 "ICR ECU message: info";
CM_ SG_ 941 ICR_infoIndex "ICR ECU: info index";
CM_ SG_ 941 ICR_infoBuildType "ICR ECU: info build type";
CM_ SG_ 941 ICR_infoPcbaId "ICR ECU: info pcba id";
CM_ SG_ 941 ICR_infoAssemblyId "ICR ECU: info assembly id";
CM_ SG_ 941 ICR_infoUsageId "ICR ECU: info usage id";
CM_ SG_ 941 ICR_infoAppCrc "ICR ECU: info app crc";
CM_ SG_ 941 ICR_infoBoardPartNumber17 "ICR ECU: info board part number17";
CM_ SG_ 941 ICR_infoBoardPartNumber814 "ICR ECU: info board part number814";
CM_ SG_ 941 ICR_infoBoardPartNumber1520 "ICR ECU: info board part number1520";
CM_ BO_ 536 "ICR ECU message: occupancy";
CM_ SG_ 536 ICR_occupancy1LRaw "(Non-Functional Interface) Occupancy detection status of First Row left seat; raw 3 = signal not available (SNA)";
CM_ SG_ 536 ICR_occupancy1RRaw "(Non-Functional Interface) Occupancy detection status of First Row right seat; raw 3 = signal not available (SNA)";
CM_ SG_ 536 ICR_occupancy1LVoteCnt "ICR ECU: occupancy1 l vote cnt";
CM_ SG_ 536 ICR_occupancy1RVoteCnt "ICR ECU: occupancy1 r vote cnt";
CM_ SG_ 536 ICR_userPresenceFilt "Detection status of User Presence Detection feature; raw 3 = signal not available (SNA)";
CM_ SG_ 536 ICR_userPresenceRaw "ICR ECU: user presence raw; raw 3 = signal not available (SNA)";
CM_ SG_ 536 ICR_occupancy1LFilt "(Non-Functional Interface) Occupancy detection status of First Row left seat; raw 3 = signal not available (SNA)";
CM_ SG_ 536 ICR_occupancy1RFilt "(Non-Functional Interface) Occupancy detection status of First Row right seat; raw 3 = signal not available (SNA)";
CM_ SG_ 536 ICR_occupancy2LFilt "ICR ECU: occupancy2 l filt; raw 3 = signal not available (SNA)";
CM_ SG_ 536 ICR_occupancy2CFilt "ICR ECU: occupancy2 c filt; raw 3 = signal not available (SNA)";
CM_ SG_ 536 ICR_occupancy2RFilt "ICR ECU: occupancy2 r filt; raw 3 = signal not available (SNA)";
CM_ SG_ 536 ICR_childPresenceFilt "ICR ECU: child presence filt; raw 0 = signal not available (SNA)";
CM_ SG_ 536 ICR_childPresenceRaw "ICR ECU: child presence raw; raw 0 = signal not available (SNA)";
CM_ SG_ 536 ICR_classification1LFilt "ICR ECU: classification1 l filt; raw 0 = signal not available (SNA)";
CM_ SG_ 536 ICR_classification1RqF "ICR ECU: classification1 rq f";
CM_ SG_ 536 ICR_occupancy1RFiltExp "ICR ECU: occupancy1 r filt exp; raw 3 = signal not available (SNA)";
CM_ SG_ 536 ICR_occupancyCounter "ICR ECU: occupancy counter";
CM_ SG_ 536 ICR_occupancyChecksum "ICR ECU: occupancy checksum";
CM_ BO_ 670 "ICR ECU message: occupancy2";
CM_ SG_ 670 ICR_userPresenceMLOutput "ICR ECU: user presence ML output; raw 255 = signal not available (SNA)";
CM_ SG_ 670 ICR_childPresenceMLOutput "ICR ECU: child presence ML output; raw 255 = signal not available (SNA)";
CM_ SG_ 670 ICR_classification1RFilt "Occupant classification status of First Row Right seat; raw 0 = signal not available (SNA)";
CM_ SG_ 670 ICR_classification1LRaw "ICR ECU: classification1 l raw; raw 0 = signal not available (SNA)";
CM_ SG_ 670 ICR_classification1RRaw "ICR ECU: classification1 r raw; raw 0 = signal not available (SNA)";
CM_ SG_ 670 ICR_classification1LMLOutput "ICR ECU: classification1 LML output; raw 255 = signal not available (SNA)";
CM_ SG_ 670 ICR_classification1RMLOutput "ICR ECU: classification1 RML output; raw 255 = signal not available (SNA)";
CM_ SG_ 670 ICR_occupancy2Counter "ICR ECU: occupancy2 counter";
CM_ SG_ 670 ICR_occupancy2Checksum "ICR ECU: occupancy2 checksum";
CM_ BO_ 664 "ICR ECU message: status";
CM_ SG_ 664 ICR_sensorMode "ICR ECU: sensor mode";
CM_ SG_ 664 ICR_blocked "Indicates if sensor is blocked or not; raw 0 = signal not available (SNA)";
CM_ SG_ 664 ICR_algoVersion "ICR ECU: algo version";
CM_ SG_ 664 ICR_l2HeapUsage "ICR ECU: l2 heap usage";
CM_ SG_ 664 ICR_intrusionStatus "ICR ECU: intrusion status";
CM_ SG_ 664 ICR_booted "Indicates if ICR has rebooted";
CM_ SG_ 664 ICR_rdMapDumpCompleted "ICR ECU: rd map dump completed";
CM_ BO_ 1012 "LS ECU message: light show; forwarded onto this bus by the gateway";
CM_ SG_ 1012 LS_lightShowIndex "LS ECU: light show index";
CM_ SG_ 1012 LS_lightLeftRampedChannel1Reques "LS ECU: light left ramped channel1 request";
CM_ SG_ 1012 LS_lightLeftRampedChannel1Durati "LS ECU: light left ramped channel1 duration";
CM_ SG_ 1012 LS_lightLeftRampedChannel2Reques "LS ECU: light left ramped channel2 request";
CM_ SG_ 1012 LS_lightLeftRampedChannel2Durati "LS ECU: light left ramped channel2 duration";
CM_ SG_ 1012 LS_lightLeftRampedChannel3Reques "LS ECU: light left ramped channel3 request";
CM_ SG_ 1012 LS_lightLeftRampedChannel3Durati "LS ECU: light left ramped channel3 duration";
CM_ SG_ 1012 LS_lightLeftRampedChannel4Reques "LS ECU: light left ramped channel4 request";
CM_ SG_ 1012 LS_lightLeftRampedChannel4Durati "LS ECU: light left ramped channel4 duration";
CM_ SG_ 1012 LS_lightLeftRampedChannel5Reques "LS ECU: light left ramped channel5 request";
CM_ SG_ 1012 LS_lightLeftRampedChannel5Durati "LS ECU: light left ramped channel5 duration";
CM_ SG_ 1012 LS_lightLeftRampedChannel6Reques "LS ECU: light left ramped channel6 request";
CM_ SG_ 1012 LS_lightLeftRampedChannel6Durati "LS ECU: light left ramped channel6 duration";
CM_ SG_ 1012 LS_lightLeftRampedChannel7Reques "LS ECU: light left ramped channel7 request";
CM_ SG_ 1012 LS_lightLeftRampedChannel7Durati "LS ECU: light left ramped channel7 duration";
CM_ SG_ 1012 LS_lightRightRampedChannel1Reque "LS ECU: light right ramped channel1 request";
CM_ SG_ 1012 LS_lightRightRampedChannel1Durat "LS ECU: light right ramped channel1 duration; raw 1 = signal not available (SNA)";
CM_ SG_ 1012 LS_lightRightRampedChannel2Reque "LS ECU: light right ramped channel2 request";
CM_ SG_ 1012 LS_lightRightRampedChannel2Durat "LS ECU: light right ramped channel2 duration; raw 1 = signal not available (SNA)";
CM_ SG_ 1012 LS_lightRightRampedChannel3Reque "LS ECU: light right ramped channel3 request";
CM_ SG_ 1012 LS_lightRightRampedChannel3Durat "LS ECU: light right ramped channel3 duration";
CM_ SG_ 1012 LS_lightRightRampedChannel4Reque "LS ECU: light right ramped channel4 request";
CM_ SG_ 1012 LS_lightRightRampedChannel4Durat "LS ECU: light right ramped channel4 duration";
CM_ SG_ 1012 LS_lightRightRampedChannel5Reque "LS ECU: light right ramped channel5 request";
CM_ SG_ 1012 LS_lightRightRampedChannel5Durat "LS ECU: light right ramped channel5 duration";
CM_ SG_ 1012 LS_lightRightRampedChannel6Reque "LS ECU: light right ramped channel6 request";
CM_ SG_ 1012 LS_lightRightRampedChannel6Durat "LS ECU: light right ramped channel6 duration";
CM_ SG_ 1012 LS_lightRightRampedChannel7Reque "LS ECU: light right ramped channel7 request";
CM_ SG_ 1012 LS_lightRightRampedChannel7Durat "LS ECU: light right ramped channel7 duration";
CM_ SG_ 1012 LS_lightRearTurnLeftRequest "LS ECU: light rear turn left request";
CM_ SG_ 1012 LS_lightRearTurnRightRequest "LS ECU: light rear turn right request";
CM_ SG_ 1012 LS_lightSideRepeaterLeftRequest "LS ECU: light side repeater left request";
CM_ SG_ 1012 LS_lightSideRepeaterRightRequest "LS ECU: light side repeater right request";
CM_ SG_ 1012 LS_lightSideMarkerLeftRequest "LS ECU: light side marker left request";
CM_ SG_ 1012 LS_lightSideMarkerRightRequest "LS ECU: light side marker right request";
CM_ SG_ 1012 LS_lightFrontFogLeftRequest "LS ECU: light front fog left request";
CM_ SG_ 1012 LS_lightFrontFogRightRequest "LS ECU: light front fog right request";
CM_ SG_ 1012 LS_lightRearFogRequest "LS ECU: light rear fog request";
CM_ SG_ 1012 LS_lightBrakeRequest "LS ECU: light brake request";
CM_ SG_ 1012 LS_lightTailLeftRequest "LS ECU: light tail left request";
CM_ SG_ 1012 LS_lightTailRightRequest "LS ECU: light tail right request";
CM_ SG_ 1012 LS_lightLicensePlateRequest "LS ECU: light license plate request";
CM_ SG_ 1012 LS_lightReverseRequest "LS ECU: light reverse request";
CM_ SG_ 1012 LS_lightAuxParkLeftRequest "LS ECU: light aux park left request";
CM_ SG_ 1012 LS_lightAuxParkRightRequest "LS ECU: light aux park right request";
CM_ SG_ 1012 LS_mirrorRequestLeft "LS ECU: mirror request left";
CM_ SG_ 1012 LS_mirrorRequestRight "LS ECU: mirror request right";
CM_ SG_ 1012 LS_liftgateRequest "LS ECU: liftgate request";
CM_ SG_ 1012 LS_windowRequestLF "LS ECU: window request LF";
CM_ SG_ 1012 LS_windowRequestLR "LS ECU: window request LR";
CM_ SG_ 1012 LS_windowRequestRF "LS ECU: window request RF";
CM_ SG_ 1012 LS_windowRequestRR "LS ECU: window request RR";
CM_ SG_ 1012 LS_presentingHandleRequestLF "LS ECU: presenting handle request LF";
CM_ SG_ 1012 LS_presentingHandleRequestLR "LS ECU: presenting handle request LR";
CM_ SG_ 1012 LS_presentingHandleRequestRF "LS ECU: presenting handle request RF";
CM_ SG_ 1012 LS_presentingHandleRequestRR "LS ECU: presenting handle request RR";
CM_ SG_ 1012 LS_powerFrontDoorRequestLeft "LS ECU: power front door request left";
CM_ SG_ 1012 LS_powerFrontDoorRequestRight "LS ECU: power front door request right";
CM_ SG_ 1012 LS_falconDoorRequestLeft "LS ECU: falcon door request left";
CM_ SG_ 1012 LS_falconDoorRequestRight "LS ECU: falcon door request right";
CM_ SG_ 1012 LS_chargePortRequest "LS ECU: charge port request; raw 3 = signal not available (SNA)";
CM_ SG_ 1012 LS_chargePortRaveRequest "LS ECU: charge port rave request";
CM_ SG_ 1012 LS_suspensionRequest "LS ECU: suspension request; raw 3 = signal not available (SNA)";
CM_ SG_ 1012 LS_rgbIPFLRed "LS ECU: rgb IPFL red";
CM_ SG_ 1012 LS_rgbIPFLGreen "LS ECU: rgb IPFL green";
CM_ SG_ 1012 LS_rgbIPFLBlue "LS ECU: rgb IPFL blue";
CM_ SG_ 1012 LS_rgbIPFRRed "LS ECU: rgb IPFR red";
CM_ SG_ 1012 LS_rgbIPFRGreen "LS ECU: rgb IPFR green";
CM_ SG_ 1012 LS_rgbIPFRBlue "LS ECU: rgb IPFR blue";
CM_ SG_ 1012 LS_rgbDoorFLForeRed "LS ECU: rgb door FL fore red";
CM_ SG_ 1012 LS_rgbDoorFLForeGreen "LS ECU: rgb door FL fore green";
CM_ SG_ 1012 LS_rgbDoorFLForeBlue "LS ECU: rgb door FL fore blue";
CM_ SG_ 1012 LS_rgbDoorFLAftRed "LS ECU: rgb door FL aft red";
CM_ SG_ 1012 LS_rgbDoorFLAftGreen "LS ECU: rgb door FL aft green";
CM_ SG_ 1012 LS_rgbDoorFLAftBlue "LS ECU: rgb door FL aft blue";
CM_ SG_ 1012 LS_rgbDoorFRForeRed "LS ECU: rgb door FR fore red";
CM_ SG_ 1012 LS_rgbDoorFRForeGreen "LS ECU: rgb door FR fore green";
CM_ SG_ 1012 LS_rgbDoorFRForeBlue "LS ECU: rgb door FR fore blue";
CM_ SG_ 1012 LS_rgbDoorFRAftRed "LS ECU: rgb door FR aft red";
CM_ SG_ 1012 LS_rgbDoorFRAftGreen "LS ECU: rgb door FR aft green";
CM_ SG_ 1012 LS_rgbDoorFRAftBlue "LS ECU: rgb door FR aft blue";
CM_ SG_ 1012 LS_rgbDoorRLForeRed "LS ECU: rgb door RL fore red";
CM_ SG_ 1012 LS_rgbDoorRLForeGreen "LS ECU: rgb door RL fore green";
CM_ SG_ 1012 LS_rgbDoorRLForeBlue "LS ECU: rgb door RL fore blue";
CM_ SG_ 1012 LS_rgbDoorRLAftRed "LS ECU: rgb door RL aft red";
CM_ SG_ 1012 LS_rgbDoorRLAftGreen "LS ECU: rgb door RL aft green";
CM_ SG_ 1012 LS_rgbDoorRLAftBlue "LS ECU: rgb door RL aft blue";
CM_ SG_ 1012 LS_rgbDoorRRForeRed "LS ECU: rgb door RR fore red";
CM_ SG_ 1012 LS_rgbDoorRRForeGreen "LS ECU: rgb door RR fore green";
CM_ SG_ 1012 LS_rgbDoorRRForeBlue "LS ECU: rgb door RR fore blue";
CM_ SG_ 1012 LS_rgbDoorRRAftRed "LS ECU: rgb door RR aft red";
CM_ SG_ 1012 LS_rgbDoorRRAftGreen "LS ECU: rgb door RR aft green";
CM_ SG_ 1012 LS_rgbDoorRRAftBlue "LS ECU: rgb door RR aft blue";
CM_ SG_ 1012 LS_frontMatrix0 "LS ECU: front matrix0";
CM_ SG_ 1012 LS_frontMatrix1 "LS ECU: front matrix1";
CM_ SG_ 1012 LS_frontMatrix2 "LS ECU: front matrix2";
CM_ SG_ 1012 LS_frontMatrix3 "LS ECU: front matrix3";
CM_ SG_ 1012 LS_frontMatrix4 "LS ECU: front matrix4";
CM_ SG_ 1012 LS_frontMatrix5 "LS ECU: front matrix5";
CM_ SG_ 1012 LS_frontMatrix6 "LS ECU: front matrix6";
CM_ SG_ 1012 LS_frontMatrix7 "LS ECU: front matrix7";
CM_ SG_ 1012 LS_frontMatrix8 "LS ECU: front matrix8";
CM_ SG_ 1012 LS_frontMatrix9 "LS ECU: front matrix9";
CM_ SG_ 1012 LS_frontMatrix10 "LS ECU: front matrix10";
CM_ SG_ 1012 LS_frontMatrix11 "LS ECU: front matrix11";
CM_ SG_ 1012 LS_frontMatrix12 "LS ECU: front matrix12";
CM_ SG_ 1012 LS_frontMatrix13 "LS ECU: front matrix13";
CM_ SG_ 1012 LS_frontMatrix14 "LS ECU: front matrix14";
CM_ SG_ 1012 LS_frontMatrix15 "LS ECU: front matrix15";
CM_ SG_ 1012 LS_frontMatrix16 "LS ECU: front matrix16";
CM_ SG_ 1012 LS_frontMatrix17 "LS ECU: front matrix17";
CM_ SG_ 1012 LS_frontMatrix18 "LS ECU: front matrix18";
CM_ SG_ 1012 LS_frontMatrix19 "LS ECU: front matrix19";
CM_ SG_ 1012 LS_frontMatrix20 "LS ECU: front matrix20";
CM_ SG_ 1012 LS_frontMatrix21 "LS ECU: front matrix21";
CM_ SG_ 1012 LS_frontMatrix22 "LS ECU: front matrix22";
CM_ SG_ 1012 LS_frontMatrix23 "LS ECU: front matrix23";
CM_ SG_ 1012 LS_frontMatrix24 "LS ECU: front matrix24";
CM_ SG_ 1012 LS_frontMatrix25 "LS ECU: front matrix25";
CM_ SG_ 1012 LS_frontMatrix26 "LS ECU: front matrix26";
CM_ SG_ 1012 LS_frontMatrix27 "LS ECU: front matrix27";
CM_ SG_ 1012 LS_frontMatrix28 "LS ECU: front matrix28";
CM_ SG_ 1012 LS_frontMatrix29 "LS ECU: front matrix29";
CM_ SG_ 1012 LS_frontMatrix30 "LS ECU: front matrix30";
CM_ SG_ 1012 LS_frontMatrix31 "LS ECU: front matrix31";
CM_ SG_ 1012 LS_frontMatrix32 "LS ECU: front matrix32";
CM_ SG_ 1012 LS_frontMatrix33 "LS ECU: front matrix33";
CM_ SG_ 1012 LS_frontMatrix34 "LS ECU: front matrix34";
CM_ SG_ 1012 LS_frontMatrix35 "LS ECU: front matrix35";
CM_ SG_ 1012 LS_frontMatrix36 "LS ECU: front matrix36";
CM_ SG_ 1012 LS_frontMatrix37 "LS ECU: front matrix37";
CM_ SG_ 1012 LS_frontMatrix38 "LS ECU: front matrix38";
CM_ SG_ 1012 LS_frontMatrix39 "LS ECU: front matrix39";
CM_ SG_ 1012 LS_frontMatrix40 "LS ECU: front matrix40";
CM_ SG_ 1012 LS_frontMatrix41 "LS ECU: front matrix41";
CM_ SG_ 1012 LS_frontMatrix42 "LS ECU: front matrix42";
CM_ SG_ 1012 LS_frontMatrix43 "LS ECU: front matrix43";
CM_ SG_ 1012 LS_frontMatrix44 "LS ECU: front matrix44";
CM_ SG_ 1012 LS_frontMatrix45 "LS ECU: front matrix45";
CM_ SG_ 1012 LS_frontMatrix46 "LS ECU: front matrix46";
CM_ SG_ 1012 LS_frontMatrix47 "LS ECU: front matrix47";
CM_ SG_ 1012 LS_frontMatrix48 "LS ECU: front matrix48";
CM_ SG_ 1012 LS_frontMatrix49 "LS ECU: front matrix49";
CM_ SG_ 1012 LS_frontMatrix50 "LS ECU: front matrix50";
CM_ SG_ 1012 LS_frontMatrix51 "LS ECU: front matrix51";
CM_ SG_ 1012 LS_frontMatrix52 "LS ECU: front matrix52";
CM_ SG_ 1012 LS_frontMatrix53 "LS ECU: front matrix53";
CM_ SG_ 1012 LS_frontMatrix54 "LS ECU: front matrix54";
CM_ SG_ 1012 LS_frontMatrix55 "LS ECU: front matrix55";
CM_ SG_ 1012 LS_frontMatrix56 "LS ECU: front matrix56";
CM_ SG_ 1012 LS_frontMatrix57 "LS ECU: front matrix57";
CM_ SG_ 1012 LS_frontMatrix58 "LS ECU: front matrix58";
CM_ SG_ 1012 LS_frontMatrix59 "LS ECU: front matrix59";
CM_ SG_ 1012 LS_rearMatrix0 "LS ECU: rear matrix0";
CM_ SG_ 1012 LS_rearMatrix1 "LS ECU: rear matrix1";
CM_ SG_ 1012 LS_rearMatrix2 "LS ECU: rear matrix2";
CM_ SG_ 1012 LS_rearMatrix3 "LS ECU: rear matrix3";
CM_ SG_ 1012 LS_rearMatrix4 "LS ECU: rear matrix4";
CM_ SG_ 1012 LS_rearMatrix5 "LS ECU: rear matrix5";
CM_ SG_ 1012 LS_rearMatrix6 "LS ECU: rear matrix6";
CM_ SG_ 1012 LS_rearMatrix7 "LS ECU: rear matrix7";
CM_ SG_ 1012 LS_rearMatrix8 "LS ECU: rear matrix8";
CM_ SG_ 1012 LS_rearMatrix9 "LS ECU: rear matrix9";
CM_ SG_ 1012 LS_rearMatrix10 "LS ECU: rear matrix10";
CM_ SG_ 1012 LS_rearMatrix11 "LS ECU: rear matrix11";
CM_ SG_ 1012 LS_rearMatrix12 "LS ECU: rear matrix12";
CM_ SG_ 1012 LS_rearMatrix13 "LS ECU: rear matrix13";
CM_ SG_ 1012 LS_rearMatrix14 "LS ECU: rear matrix14";
CM_ SG_ 1012 LS_rearMatrix15 "LS ECU: rear matrix15";
CM_ SG_ 1012 LS_rearMatrix16 "LS ECU: rear matrix16";
CM_ SG_ 1012 LS_rearMatrix17 "LS ECU: rear matrix17";
CM_ SG_ 1012 LS_rearMatrix18 "LS ECU: rear matrix18";
CM_ SG_ 1012 LS_rearMatrix19 "LS ECU: rear matrix19";
CM_ SG_ 1012 LS_rearMatrix20 "LS ECU: rear matrix20";
CM_ SG_ 1012 LS_rearMatrix21 "LS ECU: rear matrix21";
CM_ SG_ 1012 LS_rearMatrix22 "LS ECU: rear matrix22";
CM_ SG_ 1012 LS_rearMatrix23 "LS ECU: rear matrix23";
CM_ SG_ 1012 LS_rearMatrix24 "LS ECU: rear matrix24";
CM_ SG_ 1012 LS_rearMatrix25 "LS ECU: rear matrix25";
CM_ SG_ 1012 LS_rearMatrix26 "LS ECU: rear matrix26";
CM_ SG_ 1012 LS_rearMatrix27 "LS ECU: rear matrix27";
CM_ SG_ 1012 LS_rearMatrix28 "LS ECU: rear matrix28";
CM_ SG_ 1012 LS_rearMatrix29 "LS ECU: rear matrix29";
CM_ SG_ 1012 LS_rearMatrix30 "LS ECU: rear matrix30";
CM_ SG_ 1012 LS_rearMatrix31 "LS ECU: rear matrix31";
CM_ SG_ 1012 LS_rearMatrix32 "LS ECU: rear matrix32";
CM_ SG_ 1012 LS_rearMatrix33 "LS ECU: rear matrix33";
CM_ SG_ 1012 LS_rearMatrix34 "LS ECU: rear matrix34";
CM_ SG_ 1012 LS_rearMatrix35 "LS ECU: rear matrix35";
CM_ SG_ 1012 LS_rearMatrix36 "LS ECU: rear matrix36";
CM_ SG_ 1012 LS_rearMatrix37 "LS ECU: rear matrix37";
CM_ SG_ 1012 LS_rearMatrix38 "LS ECU: rear matrix38";
CM_ SG_ 1012 LS_rearMatrix39 "LS ECU: rear matrix39";
CM_ SG_ 1012 LS_rearMatrix40 "LS ECU: rear matrix40";
CM_ SG_ 1012 LS_rearMatrix41 "LS ECU: rear matrix41";
CM_ SG_ 1012 LS_rearMatrix42 "LS ECU: rear matrix42";
CM_ SG_ 1012 LS_rearMatrix43 "LS ECU: rear matrix43";
CM_ SG_ 1012 LS_rearMatrix44 "LS ECU: rear matrix44";
CM_ SG_ 1012 LS_rearMatrix45 "LS ECU: rear matrix45";
CM_ SG_ 1012 LS_rearMatrix46 "LS ECU: rear matrix46";
CM_ SG_ 1012 LS_rearMatrix47 "LS ECU: rear matrix47";
CM_ SG_ 1012 LS_rearMatrix48 "LS ECU: rear matrix48";
CM_ SG_ 1012 LS_rearMatrix49 "LS ECU: rear matrix49";
CM_ SG_ 1012 LS_rearMatrix50 "LS ECU: rear matrix50";
CM_ SG_ 1012 LS_rearMatrix51 "LS ECU: rear matrix51";
CM_ SG_ 1012 LS_rearMatrix52 "LS ECU: rear matrix52";
CM_ SG_ 1012 LS_rearMatrix53 "LS ECU: rear matrix53";
CM_ SG_ 1012 LS_rearMatrix54 "LS ECU: rear matrix54";
CM_ SG_ 1012 LS_rearMatrix55 "LS ECU: rear matrix55";
CM_ SG_ 1012 LS_rearMatrix56 "LS ECU: rear matrix56";
CM_ SG_ 1012 LS_rearMatrix57 "LS ECU: rear matrix57";
CM_ SG_ 1012 LS_rearMatrix58 "LS ECU: rear matrix58";
CM_ SG_ 1012 LS_rearMatrix59 "LS ECU: rear matrix59";
CM_ SG_ 1012 LS_offroadLightBar0 "LS ECU: offroad light bar0";
CM_ SG_ 1012 LS_offroadLightBar1 "LS ECU: offroad light bar1";
CM_ SG_ 1012 LS_offroadLightBar2 "LS ECU: offroad light bar2";
CM_ SG_ 1012 LS_offroadLightBar3 "LS ECU: offroad light bar3";
CM_ SG_ 1012 LS_offroadLightBar4 "LS ECU: offroad light bar4";
CM_ SG_ 1012 LS_offroadLightBar5 "LS ECU: offroad light bar5";
CM_ BO_ 1060 "Power conversion system (on-board charger and DC-DC converter) message: alert log";
CM_ SG_ 1060 PCS_alertID "Power conversion system (on-board charger and DC-DC converter): alert ID";
CM_ SG_ 1060 PCS_alertSet "Power conversion system (on-board charger and DC-DC converter): alert set";
CM_ SG_ 1060 PCS_alertSource "Power conversion system (on-board charger and DC-DC converter): alert source";
CM_ SG_ 1060 PCS_a001_llcFrequency "Power conversion system (on-board charger and DC-DC converter): a001 llc frequency";
CM_ SG_ 1060 PCS_a001_llcCurrent "Power conversion system (on-board charger and DC-DC converter): a001 llc current";
CM_ SG_ 1060 PCS_a001_phState "Power conversion system (on-board charger and DC-DC converter): a001 ph state";
CM_ SG_ 1060 PCS_a001_pfcCurrentRms "Power conversion system (on-board charger and DC-DC converter): a001 pfc current rms";
CM_ SG_ 1060 PCS_a001_intBusV "Power conversion system (on-board charger and DC-DC converter): a001 int bus v";
CM_ SG_ 1060 PCS_a002_phState "Power conversion system (on-board charger and DC-DC converter): a002 ph state";
CM_ SG_ 1060 PCS_a003_phState "Power conversion system (on-board charger and DC-DC converter): a003 ph state";
CM_ SG_ 1060 PCS_a004_phState "Power conversion system (on-board charger and DC-DC converter): a004 ph state";
CM_ SG_ 1060 PCS_a005_outputV "Power conversion system (on-board charger and DC-DC converter): a005 output v";
CM_ SG_ 1060 PCS_a005_outputVOvThreshold "Power conversion system (on-board charger and DC-DC converter): a005 output v ov threshold";
CM_ SG_ 1060 PCS_a006_phState "Power conversion system (on-board charger and DC-DC converter): a006 ph state";
CM_ SG_ 1060 PCS_a006_intBusPrechargeTarget "Power conversion system (on-board charger and DC-DC converter): a006 int bus precharge target";
CM_ SG_ 1060 PCS_a006_intBusV "Power conversion system (on-board charger and DC-DC converter): a006 int bus v";
CM_ SG_ 1060 PCS_a006_inputVrms "Power conversion system (on-board charger and DC-DC converter): a006 input vrms";
CM_ SG_ 1060 PCS_a006_inputVToIntBusDeltaMax "Power conversion system (on-board charger and DC-DC converter): a006 input v to int bus delta max";
CM_ SG_ 1060 PCS_a006_inputFrequency "Power conversion system (on-board charger and DC-DC converter): a006 input frequency";
CM_ SG_ 1060 PCS_a007_phATemperature "Power conversion system (on-board charger and DC-DC converter): a007 ph a temperature";
CM_ SG_ 1060 PCS_a007_phBTemperature "Power conversion system (on-board charger and DC-DC converter): a007 ph b temperature";
CM_ SG_ 1060 PCS_a007_phCTemperature "Power conversion system (on-board charger and DC-DC converter): a007 ph c temperature";
CM_ SG_ 1060 PCS_a007_ambientTemperature "Power conversion system (on-board charger and DC-DC converter): a007 ambient temperature";
CM_ SG_ 1060 PCS_a007_inputVrms "Power conversion system (on-board charger and DC-DC converter): a007 input vrms";
CM_ SG_ 1060 PCS_a007_inputIrms "Power conversion system (on-board charger and DC-DC converter): a007 input irms";
CM_ SG_ 1060 PCS_a008_phState "Power conversion system (on-board charger and DC-DC converter): a008 ph state";
CM_ SG_ 1060 PCS_a008_phaseTemperature "Power conversion system (on-board charger and DC-DC converter): a008 phase temperature";
CM_ SG_ 1060 PCS_a008_inputVrms "Power conversion system (on-board charger and DC-DC converter): a008 input vrms";
CM_ SG_ 1060 PCS_a008_inputIrms "Power conversion system (on-board charger and DC-DC converter): a008 input irms";
CM_ SG_ 1060 PCS_a009_phState "Power conversion system (on-board charger and DC-DC converter): a009 ph state";
CM_ SG_ 1060 PCS_a009_pfcCurrentRms "Power conversion system (on-board charger and DC-DC converter): a009 pfc current rms";
CM_ SG_ 1060 PCS_a009_pfcCurrentTarget "Power conversion system (on-board charger and DC-DC converter): a009 pfc current target";
CM_ SG_ 1060 PCS_a009_llcCurrent "Power conversion system (on-board charger and DC-DC converter): a009 llc current";
CM_ SG_ 1060 PCS_a009_intBusV "Power conversion system (on-board charger and DC-DC converter): a009 int bus v";
CM_ SG_ 1060 PCS_a010_phState "Power conversion system (on-board charger and DC-DC converter): a010 ph state";
CM_ SG_ 1060 PCS_a010_pfcCurrentRms "Power conversion system (on-board charger and DC-DC converter): a010 pfc current rms";
CM_ SG_ 1060 PCS_a010_llcCurrent "Power conversion system (on-board charger and DC-DC converter): a010 llc current";
CM_ SG_ 1060 PCS_a010_intBusV "Power conversion system (on-board charger and DC-DC converter): a010 int bus v";
CM_ SG_ 1060 PCS_a010_intBusVTarget "Power conversion system (on-board charger and DC-DC converter): a010 int bus v target";
CM_ SG_ 1060 PCS_a011_phState "Power conversion system (on-board charger and DC-DC converter): a011 ph state";
CM_ SG_ 1060 PCS_a011_llcCurrent "Power conversion system (on-board charger and DC-DC converter): a011 llc current";
CM_ SG_ 1060 PCS_a011_llcCurrentTarget "Power conversion system (on-board charger and DC-DC converter): a011 llc current target";
CM_ SG_ 1060 PCS_a011_llcFrequency "Power conversion system (on-board charger and DC-DC converter): a011 llc frequency";
CM_ SG_ 1060 PCS_a011_intBusV "Power conversion system (on-board charger and DC-DC converter): a011 int bus v";
CM_ SG_ 1060 PCS_a011_outputV "Power conversion system (on-board charger and DC-DC converter): a011 output v";
CM_ SG_ 1060 PCS_a012_phState "Power conversion system (on-board charger and DC-DC converter): a012 ph state";
CM_ SG_ 1060 PCS_a012_llcFrequency "Power conversion system (on-board charger and DC-DC converter): a012 llc frequency";
CM_ SG_ 1060 PCS_a012_llcCurrent "Power conversion system (on-board charger and DC-DC converter): a012 llc current";
CM_ SG_ 1060 PCS_a012_outOfIBandDuration "Power conversion system (on-board charger and DC-DC converter): a012 out of i band duration";
CM_ SG_ 1060 PCS_a012_batteryV "Power conversion system (on-board charger and DC-DC converter): a012 battery v";
CM_ SG_ 1060 PCS_a012_transientRetryCount "Power conversion system (on-board charger and DC-DC converter): a012 transient retry count";
CM_ SG_ 1060 PCS_a013_phState "Power conversion system (on-board charger and DC-DC converter): a013 ph state";
CM_ SG_ 1060 PCS_a013_intBusPrechargeTarget "Power conversion system (on-board charger and DC-DC converter): a013 int bus precharge target";
CM_ SG_ 1060 PCS_a013_intBusV "Power conversion system (on-board charger and DC-DC converter): a013 int bus v";
CM_ SG_ 1060 PCS_a013_inputVrms "Power conversion system (on-board charger and DC-DC converter): a013 input vrms";
CM_ SG_ 1060 PCS_a013_inputVToIntBusDeltaMax "Power conversion system (on-board charger and DC-DC converter): a013 input v to int bus delta max";
CM_ SG_ 1060 PCS_a013_inputFrequency "Power conversion system (on-board charger and DC-DC converter): a013 input frequency";
CM_ SG_ 1060 PCS_a014_phaTemperature "Power conversion system (on-board charger and DC-DC converter): a014 pha temperature";
CM_ SG_ 1060 PCS_a014_phbTemperature "Power conversion system (on-board charger and DC-DC converter): a014 phb temperature";
CM_ SG_ 1060 PCS_a014_phcTemperature "Power conversion system (on-board charger and DC-DC converter): a014 phc temperature";
CM_ SG_ 1060 PCS_a015_lvBusVoltage "Power conversion system (on-board charger and DC-DC converter): a015 lv bus voltage";
CM_ SG_ 1060 PCS_a016_phAVoltSrcMissingDetect "Power conversion system (on-board charger and DC-DC converter): a016 ph a volt src missing detected";
CM_ SG_ 1060 PCS_a016_phBVoltSrcMissingDetect "Power conversion system (on-board charger and DC-DC converter): a016 ph b volt src missing detected";
CM_ SG_ 1060 PCS_a016_phCVoltSrcMissingDetect "Power conversion system (on-board charger and DC-DC converter): a016 ph c volt src missing detected";
CM_ SG_ 1060 PCS_a018_PhaseDiff_L1N_L2N "Power conversion system (on-board charger and DC-DC converter): a018 phase diff L1 n L2 n";
CM_ SG_ 1060 PCS_a018_PhaseDiff_L2N_L3N "Power conversion system (on-board charger and DC-DC converter): a018 phase diff L2 n L3 n";
CM_ SG_ 1060 PCS_a018_PhaseDiff_L1N_L3N "Power conversion system (on-board charger and DC-DC converter): a018 phase diff L1 n L3 n";
CM_ SG_ 1060 PCS_a018_PhaseDiff_L1L2_L1N "Power conversion system (on-board charger and DC-DC converter): a018 phase diff L1 L2 L1 n";
CM_ SG_ 1060 PCS_a018_L1NLocked "Power conversion system (on-board charger and DC-DC converter): a018 L1 n locked";
CM_ SG_ 1060 PCS_a018_L2NLocked "Power conversion system (on-board charger and DC-DC converter): a018 L2 n locked";
CM_ SG_ 1060 PCS_a018_L3NLocked "Power conversion system (on-board charger and DC-DC converter): a018 L3 n locked";
CM_ SG_ 1060 PCS_a018_L1L2Locked "Power conversion system (on-board charger and DC-DC converter): a018 L1 L2 locked";
CM_ SG_ 1060 PCS_a019_pcsMaxAvailablePower "Power conversion system (on-board charger and DC-DC converter): a019 pcs max available power";
CM_ SG_ 1060 PCS_a019_utilityPowerAvailable "Power conversion system (on-board charger and DC-DC converter): a019 utility power available";
CM_ SG_ 1060 PCS_a019_userPowerRequest "Power conversion system (on-board charger and DC-DC converter): a019 user power request";
CM_ SG_ 1060 PCS_a019_phAFaulted "Power conversion system (on-board charger and DC-DC converter): a019 ph a faulted";
CM_ SG_ 1060 PCS_a019_phBFaulted "Power conversion system (on-board charger and DC-DC converter): a019 ph b faulted";
CM_ SG_ 1060 PCS_a019_phCFaulted "Power conversion system (on-board charger and DC-DC converter): a019 ph c faulted";
CM_ SG_ 1060 PCS_a020_chargeEnableLine "Power conversion system (on-board charger and DC-DC converter): a020 charge enable line";
CM_ SG_ 1060 PCS_a020_chargeEnableCan "Power conversion system (on-board charger and DC-DC converter): a020 charge enable can";
CM_ SG_ 1060 PCS_a021_HVP_hvsControl "Power conversion system (on-board charger and DC-DC converter): a021 HVP hvs control";
CM_ SG_ 1060 PCS_a022_BMS_pcsRequest "Power conversion system (on-board charger and DC-DC converter): a022 BMS pcs request";
CM_ SG_ 1060 PCS_a022_BMS_chargeStatus "Power conversion system (on-board charger and DC-DC converter): a022 BMS charge status";
CM_ SG_ 1060 PCS_a023_CP_chargeStatus "Power conversion system (on-board charger and DC-DC converter): a023 CP charge status";
CM_ SG_ 1060 PCS_a023_CP_status "Power conversion system (on-board charger and DC-DC converter): a023 CP status";
CM_ SG_ 1060 PCS_a024_VCFRONT_sensors "Power conversion system (on-board charger and DC-DC converter): a024 VCFRONT sensors";
CM_ SG_ 1060 PCS_a024_VCFRONT_vehicleStatus "Power conversion system (on-board charger and DC-DC converter): a024 VCFRONT vehicle status";
CM_ SG_ 1060 PCS_a024_VCFRONT_systemStatus "Power conversion system (on-board charger and DC-DC converter): a024 VCFRONT system status";
CM_ SG_ 1060 PCS_a024_VCFRONT_coolant "Power conversion system (on-board charger and DC-DC converter): a024 VCFRONT coolant";
CM_ SG_ 1060 PCS_a024_VCFRONT_vehNm "Power conversion system (on-board charger and DC-DC converter): a024 VCFRONT veh nm";
CM_ SG_ 1060 PCS_a025_cpu2ErrorCode "Power conversion system (on-board charger and DC-DC converter): a025 cpu2 error code";
CM_ SG_ 1060 PCS_a025_bootromStatus "Power conversion system (on-board charger and DC-DC converter): a025 bootrom status";
CM_ SG_ 1060 PCS_a025_bootloaderStatus "Power conversion system (on-board charger and DC-DC converter): a025 bootloader status";
CM_ SG_ 1060 PCS_a025_bootromRequestFlag "Power conversion system (on-board charger and DC-DC converter): a025 bootrom request flag";
CM_ SG_ 1060 PCS_a025_bootromRequestStatusFla "Power conversion system (on-board charger and DC-DC converter): a025 bootrom request status flag";
CM_ SG_ 1060 PCS_a025_cpu2StoredAppCrcLsb16 "Power conversion system (on-board charger and DC-DC converter): a025 cpu2 stored app crc lsb16";
CM_ SG_ 1060 PCS_a027_chgPhATemp "Power conversion system (on-board charger and DC-DC converter): a027 chg ph a temp";
CM_ SG_ 1060 PCS_a027_chgPhBTemp "Power conversion system (on-board charger and DC-DC converter): a027 chg ph b temp";
CM_ SG_ 1060 PCS_a027_chgPhCTemp "Power conversion system (on-board charger and DC-DC converter): a027 chg ph c temp";
CM_ SG_ 1060 PCS_a027_chgPhANoFlowBucket "Power conversion system (on-board charger and DC-DC converter): a027 chg ph a no flow bucket";
CM_ SG_ 1060 PCS_a027_chgPhBNoFlowBucket "Power conversion system (on-board charger and DC-DC converter): a027 chg ph b no flow bucket";
CM_ SG_ 1060 PCS_a027_chgPhCNoFlowBucket "Power conversion system (on-board charger and DC-DC converter): a027 chg ph c no flow bucket";
CM_ SG_ 1060 PCS_a028_outputV "Power conversion system (on-board charger and DC-DC converter): a028 output v";
CM_ SG_ 1060 PCS_a028_outputVUvThreshold "Power conversion system (on-board charger and DC-DC converter): a028 output v uv threshold";
CM_ SG_ 1060 PCS_a029_inputVrms "Power conversion system (on-board charger and DC-DC converter): a029 input vrms";
CM_ SG_ 1060 PCS_a029_chgInputPower "Power conversion system (on-board charger and DC-DC converter): a029 chg input power";
CM_ SG_ 1060 PCS_a029_bmsPowerCommand "Power conversion system (on-board charger and DC-DC converter): a029 bms power command";
CM_ SG_ 1060 PCS_a029_phaseConfig "Power conversion system (on-board charger and DC-DC converter): a029 phase config; raw 0 = signal not available (SNA)";
CM_ SG_ 1060 PCS_a030_canRxErrorType "Power conversion system (on-board charger and DC-DC converter): a030 can rx error type";
CM_ SG_ 1060 PCS_a030_canID "Power conversion system (on-board charger and DC-DC converter): a030 can ID";
CM_ SG_ 1060 PCS_a032_phATransientRetryCount "Power conversion system (on-board charger and DC-DC converter): a032 ph a transient retry count";
CM_ SG_ 1060 PCS_a032_phBTransientRetryCount "Power conversion system (on-board charger and DC-DC converter): a032 ph b transient retry count";
CM_ SG_ 1060 PCS_a032_phCTransientRetryCount "Power conversion system (on-board charger and DC-DC converter): a032 ph c transient retry count";
CM_ SG_ 1060 PCS_a032_phAFaulted "Power conversion system (on-board charger and DC-DC converter): a032 ph a faulted";
CM_ SG_ 1060 PCS_a032_phBFaulted "Power conversion system (on-board charger and DC-DC converter): a032 ph b faulted";
CM_ SG_ 1060 PCS_a032_phCFaulted "Power conversion system (on-board charger and DC-DC converter): a032 ph c faulted";
CM_ SG_ 1060 PCS_a033_HV_busV "Power conversion system (on-board charger and DC-DC converter): a033 HV bus v";
CM_ SG_ 1060 PCS_a034_HV_busV "Power conversion system (on-board charger and DC-DC converter): a034 HV bus v";
CM_ SG_ 1060 PCS_a035_LV_busV "Power conversion system (on-board charger and DC-DC converter): a035 LV bus v";
CM_ SG_ 1060 PCS_a036_LV_busV "Power conversion system (on-board charger and DC-DC converter): a036 LV bus v";
CM_ SG_ 1060 PCS_a037_dcdcPwmDeassertedCount "Power conversion system (on-board charger and DC-DC converter): a037 dcdc pwm deasserted count";
CM_ SG_ 1060 PCS_a038_dcdcClaFaultCode "Power conversion system (on-board charger and DC-DC converter): a038 dcdc cla fault code";
CM_ SG_ 1060 PCS_a038_dcdcSubState "Power conversion system (on-board charger and DC-DC converter): a038 dcdc sub state";
CM_ SG_ 1060 PCS_a038_dcdcLvBusV "Power conversion system (on-board charger and DC-DC converter): a038 dcdc lv bus v";
CM_ SG_ 1060 PCS_a038_dcdcHvBusV "Power conversion system (on-board charger and DC-DC converter): a038 dcdc hv bus v";
CM_ SG_ 1060 PCS_a038_dcdcLvBusCurrent_A "Power conversion system (on-board charger and DC-DC converter): a038 dcdc lv bus current a";
CM_ SG_ 1060 PCS_a038_dcdcPwmEnableDeasserted "Power conversion system (on-board charger and DC-DC converter): a038 dcdc pwm enable deasserted count";
CM_ SG_ 1060 PCS_a038_dcdcPwmEnableLine "Power conversion system (on-board charger and DC-DC converter): a038 dcdc pwm enable line";
CM_ SG_ 1060 PCS_a039_SDModuleClockFault_HV "Power conversion system (on-board charger and DC-DC converter): a039 SD module clock fault HV";
CM_ SG_ 1060 PCS_a039_SDModuleClockFault_LV "Power conversion system (on-board charger and DC-DC converter): a039 SD module clock fault LV";
CM_ SG_ 1060 PCS_a040_dcdcLvVoltageTarget "Power conversion system (on-board charger and DC-DC converter): a040 dcdc lv voltage target";
CM_ SG_ 1060 PCS_a040_dcdcLvVoltage "Power conversion system (on-board charger and DC-DC converter): a040 dcdc lv voltage";
CM_ SG_ 1060 PCS_a040_dcdcLvOutputCurrent "Power conversion system (on-board charger and DC-DC converter): a040 dcdc lv output current";
CM_ SG_ 1060 PCS_a041_dcdcTemperature "Power conversion system (on-board charger and DC-DC converter): a041 dcdc temperature";
CM_ SG_ 1060 PCS_a042_dcdcEnableLine "Power conversion system (on-board charger and DC-DC converter): a042 dcdc enable line";
CM_ SG_ 1060 PCS_a042_dcdcEnableCan "Power conversion system (on-board charger and DC-DC converter): a042 dcdc enable can";
CM_ SG_ 1060 PCS_a043_dcdcLvBusV "Power conversion system (on-board charger and DC-DC converter): a043 dcdc lv bus v";
CM_ SG_ 1060 PCS_a043_dcdcHvBusV "Power conversion system (on-board charger and DC-DC converter): a043 dcdc hv bus v";
CM_ SG_ 1060 PCS_a043_hvPrechargeTargetV "Power conversion system (on-board charger and DC-DC converter): a043 hv precharge target v";
CM_ SG_ 1060 PCS_a044_FaultReasonCode "Power conversion system (on-board charger and DC-DC converter): a044 fault reason code; raw 0 = signal not available (SNA)";
CM_ SG_ 1060 PCS_a044_shortTime_us "Power conversion system (on-board charger and DC-DC converter): a044 short time us";
CM_ SG_ 1060 PCS_a044_dcdcLvBusCurrent_A "Power conversion system (on-board charger and DC-DC converter): a044 dcdc lv bus current a";
CM_ SG_ 1060 PCS_a044_vTankPeak_abs_V "Power conversion system (on-board charger and DC-DC converter): a044 v tank peak abs v";
CM_ SG_ 1060 PCS_a045_hvBusEstimated_C_uF "Power conversion system (on-board charger and DC-DC converter): a045 hv bus estimated c u f";
CM_ SG_ 1060 PCS_a045_hvBusEstimated_R_kOhm "Power conversion system (on-board charger and DC-DC converter): a045 hv bus estimated r k ohm";
CM_ SG_ 1060 PCS_a046_hvBusEstimated_C_uF "Power conversion system (on-board charger and DC-DC converter): a046 hv bus estimated c u f";
CM_ SG_ 1060 PCS_a046_hvBusEstimated_R_kOhm "Power conversion system (on-board charger and DC-DC converter): a046 hv bus estimated r k ohm";
CM_ SG_ 1060 PCS_a047_cpu1BootLoaderCrcMismat "Power conversion system (on-board charger and DC-DC converter): a047 cpu1 boot loader crc mismatch";
CM_ SG_ 1060 PCS_a047_cpu2BootLoaderCrcMismat "Power conversion system (on-board charger and DC-DC converter): a047 cpu2 boot loader crc mismatch";
CM_ SG_ 1060 PCS_a047_calculatedBootloaderCrc "Power conversion system (on-board charger and DC-DC converter): a047 calculated bootloader crc";
CM_ SG_ 1060 PCS_a049_dcdcTemperature "Power conversion system (on-board charger and DC-DC converter): a049 dcdc temperature";
CM_ SG_ 1060 PCS_a051_phState "Power conversion system (on-board charger and DC-DC converter): a051 ph state";
CM_ SG_ 1060 PCS_a051_pfcCurrentRms "Power conversion system (on-board charger and DC-DC converter): a051 pfc current rms";
CM_ SG_ 1060 PCS_a051_llcCurrent "Power conversion system (on-board charger and DC-DC converter): a051 llc current";
CM_ SG_ 1060 PCS_a051_intBusV "Power conversion system (on-board charger and DC-DC converter): a051 int bus v";
CM_ SG_ 1060 PCS_a051_intBusVTarget "Power conversion system (on-board charger and DC-DC converter): a051 int bus v target";
CM_ SG_ 1060 PCS_a051_intBusStaticRipple "Power conversion system (on-board charger and DC-DC converter): a051 int bus static ripple";
CM_ SG_ 1060 PCS_a052_inputVrms "Power conversion system (on-board charger and DC-DC converter): a052 input vrms";
CM_ SG_ 1060 PCS_a053_inputVrms "Power conversion system (on-board charger and DC-DC converter): a053 input vrms";
CM_ SG_ 1060 PCS_a053_inputIrms "Power conversion system (on-board charger and DC-DC converter): a053 input irms";
CM_ SG_ 1060 PCS_a053_acChargeCurrentLimit "Power conversion system (on-board charger and DC-DC converter): a053 ac charge current limit";
CM_ SG_ 1060 PCS_a053_startingInputVrms "Power conversion system (on-board charger and DC-DC converter): a053 starting input vrms";
CM_ SG_ 1060 PCS_a053_phaseConfig "Power conversion system (on-board charger and DC-DC converter): a053 phase config; raw 0 = signal not available (SNA)";
CM_ SG_ 1060 PCS_a054_inputVrms "Power conversion system (on-board charger and DC-DC converter): a054 input vrms";
CM_ SG_ 1060 PCS_a054_inputIrms "Power conversion system (on-board charger and DC-DC converter): a054 input irms";
CM_ SG_ 1060 PCS_a054_acChargeCurrentLimit "Power conversion system (on-board charger and DC-DC converter): a054 ac charge current limit";
CM_ SG_ 1060 PCS_a054_startingInputVrms "Power conversion system (on-board charger and DC-DC converter): a054 starting input vrms";
CM_ SG_ 1060 PCS_a054_phaseConfig "Power conversion system (on-board charger and DC-DC converter): a054 phase config; raw 0 = signal not available (SNA)";
CM_ SG_ 1060 PCS_a057_inputVrms "Power conversion system (on-board charger and DC-DC converter): a057 input vrms";
CM_ SG_ 1060 PCS_a057_inputFrequency "Power conversion system (on-board charger and DC-DC converter): a057 input frequency";
CM_ SG_ 1060 PCS_a058_inputVrms "Power conversion system (on-board charger and DC-DC converter): a058 input vrms";
CM_ SG_ 1060 PCS_a058_inputFrequency "Power conversion system (on-board charger and DC-DC converter): a058 input frequency";
CM_ SG_ 1060 PCS_a059_inputVrms "Power conversion system (on-board charger and DC-DC converter): a059 input vrms";
CM_ SG_ 1060 PCS_a059_inputOvRmsThreshold "Power conversion system (on-board charger and DC-DC converter): a059 input ov rms threshold";
CM_ SG_ 1060 PCS_a060_inputVPeak "Power conversion system (on-board charger and DC-DC converter): a060 input v peak";
CM_ SG_ 1060 PCS_a060_inputOvPeakThreshold "Power conversion system (on-board charger and DC-DC converter): a060 input ov peak threshold";
CM_ SG_ 1060 PCS_a061_chgInputVdcOffset_L1N "Power conversion system (on-board charger and DC-DC converter): a061 chg input vdc offset L1 n";
CM_ SG_ 1060 PCS_a061_chgInputVdcOffset_L2N "Power conversion system (on-board charger and DC-DC converter): a061 chg input vdc offset L2 n";
CM_ SG_ 1060 PCS_a061_chgInputVdcOffset_L3N "Power conversion system (on-board charger and DC-DC converter): a061 chg input vdc offset L3 n";
CM_ SG_ 1060 PCS_a061_chgInputVdcOffset_L1L2 "Power conversion system (on-board charger and DC-DC converter): a061 chg input vdc offset L1 L2";
CM_ SG_ 1060 PCS_a061_PllSourceIrrational_L1N "Power conversion system (on-board charger and DC-DC converter): a061 pll source irrational L1 n";
CM_ SG_ 1060 PCS_a061_PllSourceIrrational_L2N "Power conversion system (on-board charger and DC-DC converter): a061 pll source irrational L2 n";
CM_ SG_ 1060 PCS_a061_PllSourceIrrational_L3N "Power conversion system (on-board charger and DC-DC converter): a061 pll source irrational L3 n";
CM_ SG_ 1060 PCS_a061_PllSourceIrrational_L1L "Power conversion system (on-board charger and DC-DC converter): a061 pll source irrational L1 L2";
CM_ SG_ 1060 PCS_a062_chgInputIOffset "Power conversion system (on-board charger and DC-DC converter): a062 chg input i offset";
CM_ SG_ 1060 PCS_a063_chgOutputV "Power conversion system (on-board charger and DC-DC converter): a063 chg output v";
CM_ SG_ 1060 PCS_a063_hvpHvLinkVoltage "Power conversion system (on-board charger and DC-DC converter): a063 hvp hv link voltage";
CM_ SG_ 1060 PCS_a064_chgOutputIOffset "Power conversion system (on-board charger and DC-DC converter): a064 chg output i offset";
CM_ SG_ 1060 PCS_a065_inputVrms "Power conversion system (on-board charger and DC-DC converter): a065 input vrms";
CM_ SG_ 1060 PCS_a065_inputFrequency "Power conversion system (on-board charger and DC-DC converter): a065 input frequency";
CM_ SG_ 1060 PCS_a066_dcdcHvBusVolt "Power conversion system (on-board charger and DC-DC converter): a066 dcdc hv bus volt";
CM_ SG_ 1060 PCS_a066_hvpHvLinkVoltage "Power conversion system (on-board charger and DC-DC converter): a066 hvp hv link voltage";
CM_ SG_ 1060 PCS_a067_dcdcLvBusVolt "Power conversion system (on-board charger and DC-DC converter): a067 dcdc lv bus volt";
CM_ SG_ 1060 PCS_a067_vcfrontPcsEFuseV "Power conversion system (on-board charger and DC-DC converter): a067 vcfront pcs e fuse v; raw 1023 = signal not available (SNA)";
CM_ SG_ 1060 PCS_a067_vcfrontVcrightVoltage "Power conversion system (on-board charger and DC-DC converter): a067 vcfront vcright voltage; raw 1023 = signal not available (SNA)";
CM_ SG_ 1060 PCS_a068_dcdcTankVolt "Power conversion system (on-board charger and DC-DC converter): a068 dcdc tank volt";
CM_ SG_ 1060 PCS_a068_dcdcTankVoltOffset "Power conversion system (on-board charger and DC-DC converter): a068 dcdc tank volt offset";
CM_ SG_ 1060 PCS_a069_phState "Power conversion system (on-board charger and DC-DC converter): a069 ph state";
CM_ SG_ 1060 PCS_a069_inputIDelta "Power conversion system (on-board charger and DC-DC converter): a069 input i delta";
CM_ SG_ 1060 PCS_a069_inputVrms "Power conversion system (on-board charger and DC-DC converter): a069 input vrms";
CM_ SG_ 1060 PCS_a069_intBusV "Power conversion system (on-board charger and DC-DC converter): a069 int bus v";
CM_ SG_ 1060 PCS_a069_inputFrequency "Power conversion system (on-board charger and DC-DC converter): a069 input frequency";
CM_ SG_ 1060 PCS_a070_phState "Power conversion system (on-board charger and DC-DC converter): a070 ph state";
CM_ SG_ 1060 PCS_a070_inputVDelta "Power conversion system (on-board charger and DC-DC converter): a070 input v delta";
CM_ SG_ 1060 PCS_a070_inputVrms "Power conversion system (on-board charger and DC-DC converter): a070 input vrms";
CM_ SG_ 1060 PCS_a070_intBusV "Power conversion system (on-board charger and DC-DC converter): a070 int bus v";
CM_ SG_ 1060 PCS_a070_inputFrequency "Power conversion system (on-board charger and DC-DC converter): a070 input frequency";
CM_ SG_ 1060 PCS_a071_phState "Power conversion system (on-board charger and DC-DC converter): a071 ph state";
CM_ SG_ 1060 PCS_a071_inputVrms "Power conversion system (on-board charger and DC-DC converter): a071 input vrms";
CM_ SG_ 1060 PCS_a071_intBusV "Power conversion system (on-board charger and DC-DC converter): a071 int bus v";
CM_ SG_ 1060 PCS_a071_inputFrequency "Power conversion system (on-board charger and DC-DC converter): a071 input frequency";
CM_ SG_ 1060 PCS_a071_llcFrequency "Power conversion system (on-board charger and DC-DC converter): a071 llc frequency";
CM_ SG_ 1060 PCS_a072_task1Stopped "Power conversion system (on-board charger and DC-DC converter): a072 task1 stopped";
CM_ SG_ 1060 PCS_a072_task2Stopped "Power conversion system (on-board charger and DC-DC converter): a072 task2 stopped";
CM_ SG_ 1060 PCS_a073_inputL1NVrms "Power conversion system (on-board charger and DC-DC converter): a073 input L1 n vrms";
CM_ SG_ 1060 PCS_a073_inputL2NVrms "Power conversion system (on-board charger and DC-DC converter): a073 input L2 n vrms";
CM_ SG_ 1060 PCS_a073_inputL3NVrms "Power conversion system (on-board charger and DC-DC converter): a073 input L3 n vrms";
CM_ SG_ 1060 PCS_a073_inputNGVrms "Power conversion system (on-board charger and DC-DC converter): a073 input NG vrms";
CM_ SG_ 1060 PCS_a073_phaseConfig "Power conversion system (on-board charger and DC-DC converter): a073 phase config; raw 0 = signal not available (SNA)";
CM_ SG_ 1060 PCS_a073_cpType "Power conversion system (on-board charger and DC-DC converter): a073 cp type";
CM_ SG_ 1060 PCS_a074_dcdcLvBusV "Power conversion system (on-board charger and DC-DC converter): a074 dcdc lv bus v";
CM_ SG_ 1060 PCS_a074_dcdcHvBusV "Power conversion system (on-board charger and DC-DC converter): a074 dcdc hv bus v";
CM_ SG_ 1060 PCS_a075_dcdcLvBusV "Power conversion system (on-board charger and DC-DC converter): a075 dcdc lv bus v";
CM_ SG_ 1060 PCS_a075_dcdcHvBusV "Power conversion system (on-board charger and DC-DC converter): a075 dcdc hv bus v";
CM_ SG_ 1060 PCS_a075_dcdcSubState "Power conversion system (on-board charger and DC-DC converter): a075 dcdc sub state";
CM_ SG_ 1060 PCS_a076_pcsControlRequest "Power conversion system (on-board charger and DC-DC converter): a076 pcs control request";
CM_ SG_ 1060 PCS_a076_dcdcSubState "Power conversion system (on-board charger and DC-DC converter): a076 dcdc sub state";
CM_ SG_ 1060 PCS_a076_dcdcEnableLine "Power conversion system (on-board charger and DC-DC converter): a076 dcdc enable line";
CM_ SG_ 1060 PCS_a076_dcdcPwmEnableDeasserted "Power conversion system (on-board charger and DC-DC converter): a076 dcdc pwm enable deasserted count";
CM_ SG_ 1060 PCS_a078_phaTemperature "Power conversion system (on-board charger and DC-DC converter): a078 pha temperature";
CM_ SG_ 1060 PCS_a078_phbTemperature "Power conversion system (on-board charger and DC-DC converter): a078 phb temperature";
CM_ SG_ 1060 PCS_a078_phcTemperature "Power conversion system (on-board charger and DC-DC converter): a078 phc temperature";
CM_ SG_ 1060 PCS_a078_dcdcTemperature "Power conversion system (on-board charger and DC-DC converter): a078 dcdc temperature";
CM_ SG_ 1060 PCS_a078_ptCoolantTemp "Power conversion system (on-board charger and DC-DC converter): a078 pt coolant temp";
CM_ SG_ 1060 PCS_a079_eepromOperation "Power conversion system (on-board charger and DC-DC converter): a079 eeprom operation; raw 15 = signal not available (SNA)";
CM_ SG_ 1060 PCS_a079_eepromOperationRegion "Power conversion system (on-board charger and DC-DC converter): a079 eeprom operation region";
CM_ SG_ 1060 PCS_a079_recordID "Power conversion system (on-board charger and DC-DC converter): a079 record ID";
CM_ SG_ 1060 PCS_a079_eepromOperationErrorCod "Power conversion system (on-board charger and DC-DC converter): a079 eeprom operation error code";
CM_ SG_ 1060 PCS_a079_operationAddress "Power conversion system (on-board charger and DC-DC converter): a079 operation address";
CM_ SG_ 1060 PCS_a079_eepromErrorCount "Power conversion system (on-board charger and DC-DC converter): a079 eeprom error count";
CM_ SG_ 1060 PCS_a080_phADamaged "Power conversion system (on-board charger and DC-DC converter): a080 ph a damaged";
CM_ SG_ 1060 PCS_a080_phBDamaged "Power conversion system (on-board charger and DC-DC converter): a080 ph b damaged";
CM_ SG_ 1060 PCS_a080_phCDamaged "Power conversion system (on-board charger and DC-DC converter): a080 ph c damaged";
CM_ SG_ 1060 PCS_a080_phANVRAMStoredState "Power conversion system (on-board charger and DC-DC converter): a080 ph ANVRAM stored state";
CM_ SG_ 1060 PCS_a080_phBNVRAMStoredState "Power conversion system (on-board charger and DC-DC converter): a080 ph BNVRAM stored state";
CM_ SG_ 1060 PCS_a080_phCNVRAMStoredState "Power conversion system (on-board charger and DC-DC converter): a080 ph CNVRAM stored state";
CM_ SG_ 1060 PCS_a081_dcdcLvBusV "Power conversion system (on-board charger and DC-DC converter): a081 dcdc lv bus v";
CM_ SG_ 1060 PCS_a081_dcdcHvBusV "Power conversion system (on-board charger and DC-DC converter): a081 dcdc hv bus v";
CM_ SG_ 1060 PCS_a081_faultedSubstate "Power conversion system (on-board charger and DC-DC converter): a081 faulted substate";
CM_ SG_ 1060 PCS_a082_dcdcLvBusV "Power conversion system (on-board charger and DC-DC converter): a082 dcdc lv bus v";
CM_ SG_ 1060 PCS_a082_dcdcHvBusV "Power conversion system (on-board charger and DC-DC converter): a082 dcdc hv bus v";
CM_ SG_ 1060 PCS_a082_faultedSubstate "Power conversion system (on-board charger and DC-DC converter): a082 faulted substate";
CM_ SG_ 1060 PCS_a085_dcdcHalfPeriodUs "Power conversion system (on-board charger and DC-DC converter): a085 dcdc half period us";
CM_ SG_ 1060 PCS_a086_dcdcTemperature "Power conversion system (on-board charger and DC-DC converter): a086 dcdc temperature";
CM_ SG_ 1060 PCS_a086_pcsAmbientTemperature "Power conversion system (on-board charger and DC-DC converter): a086 pcs ambient temperature";
CM_ SG_ 1060 PCS_a086_vcfrontPTCoolantTemp "Power conversion system (on-board charger and DC-DC converter): a086 vcfront PT coolant temp";
CM_ SG_ 1060 PCS_a088_gridConfig "Power conversion system (on-board charger and DC-DC converter): a088 grid config; raw 0 = signal not available (SNA)";
CM_ SG_ 1060 PCS_a088_phAFrequency "Power conversion system (on-board charger and DC-DC converter): a088 ph a frequency";
CM_ SG_ 1060 PCS_a088_phBFrequency "Power conversion system (on-board charger and DC-DC converter): a088 ph b frequency";
CM_ SG_ 1060 PCS_a088_phCFrequency "Power conversion system (on-board charger and DC-DC converter): a088 ph c frequency";
CM_ SG_ 1060 PCS_a089_hvSlewRate "Power conversion system (on-board charger and DC-DC converter): a089 hv slew rate";
CM_ SG_ 1060 PCS_a089_avgSlewRate "Power conversion system (on-board charger and DC-DC converter): a089 avg slew rate";
CM_ SG_ 1060 PCS_a089_G "Power conversion system (on-board charger and DC-DC converter): a089 g";
CM_ SG_ 1060 PCS_a089_HV_busV "Power conversion system (on-board charger and DC-DC converter): a089 HV bus v";
CM_ SG_ 1060 PCS_a089_PhaseShift "Power conversion system (on-board charger and DC-DC converter): a089 phase shift";
CM_ SG_ 1060 PCS_a089_Freq "Power conversion system (on-board charger and DC-DC converter): a089 freq";
CM_ SG_ 1060 PCS_a089_fastDischargeMode "Power conversion system (on-board charger and DC-DC converter): a089 fast discharge mode";
CM_ SG_ 1060 PCS_a089_slowDischargeMode "Power conversion system (on-board charger and DC-DC converter): a089 slow discharge mode";
CM_ SG_ 1060 PCS_a090_vRmsL1N "Power conversion system (on-board charger and DC-DC converter): a090 v rms L1 n";
CM_ SG_ 1060 PCS_a090_vRmsL2N "Power conversion system (on-board charger and DC-DC converter): a090 v rms L2 n";
CM_ SG_ 1060 PCS_a090_vRmsL3N "Power conversion system (on-board charger and DC-DC converter): a090 v rms L3 n";
CM_ SG_ 1060 PCS_a090_vRmsL1L2 "Power conversion system (on-board charger and DC-DC converter): a090 v rms L1 L2";
CM_ SG_ 1060 PCS_a090_evaluatedGridConfig "Power conversion system (on-board charger and DC-DC converter): a090 evaluated grid config; raw 0 = signal not available (SNA)";
CM_ SG_ 1060 PCS_a090_phASourceMissing "Power conversion system (on-board charger and DC-DC converter): a090 ph a source missing";
CM_ SG_ 1060 PCS_a090_phBSourceMissing "Power conversion system (on-board charger and DC-DC converter): a090 ph b source missing";
CM_ SG_ 1060 PCS_a090_phCSourceMissing "Power conversion system (on-board charger and DC-DC converter): a090 ph c source missing";
CM_ SG_ 1060 PCS_a091_intBusTarget "Power conversion system (on-board charger and DC-DC converter): a091 int bus target";
CM_ SG_ 1060 PCS_a091_intBusMaxRippleLevel "Power conversion system (on-board charger and DC-DC converter): a091 int bus max ripple level";
CM_ SG_ 1060 PCS_a091_pfcCurrentIrms "Power conversion system (on-board charger and DC-DC converter): a091 pfc current irms";
CM_ SG_ 1060 PCS_a091_phaseInputVrms "Power conversion system (on-board charger and DC-DC converter): a091 phase input vrms";
CM_ SG_ 1060 PCS_a091_phaseTemp "Power conversion system (on-board charger and DC-DC converter): a091 phase temp";
CM_ SG_ 1060 PCS_a092_pfcIrmsPhA "Power conversion system (on-board charger and DC-DC converter): a092 pfc irms ph a";
CM_ SG_ 1060 PCS_a092_pfcIrmsPhB "Power conversion system (on-board charger and DC-DC converter): a092 pfc irms ph b";
CM_ SG_ 1060 PCS_a092_pfcIrmsPhC "Power conversion system (on-board charger and DC-DC converter): a092 pfc irms ph c";
CM_ SG_ 1060 PCS_a092_chgTempPhA "Power conversion system (on-board charger and DC-DC converter): a092 chg temp ph a";
CM_ SG_ 1060 PCS_a092_chgTempPhB "Power conversion system (on-board charger and DC-DC converter): a092 chg temp ph b";
CM_ SG_ 1060 PCS_a092_chgTempPhC "Power conversion system (on-board charger and DC-DC converter): a092 chg temp ph c";
CM_ SG_ 1060 PCS_a093_powerRail5VN "Power conversion system (on-board charger and DC-DC converter): a093 power rail5 VN";
CM_ SG_ 1060 PCS_a093_powerRail3V3 "Power conversion system (on-board charger and DC-DC converter): a093 power rail3 V3";
CM_ SG_ 1060 PCS_a093_powerRail1V5 "Power conversion system (on-board charger and DC-DC converter): a093 power rail1 V5";
CM_ SG_ 1060 PCS_a093_powerRail1V2 "Power conversion system (on-board charger and DC-DC converter): a093 power rail1 V2";
CM_ SG_ 1060 PCS_a093_irrational1V2Rail "Power conversion system (on-board charger and DC-DC converter): a093 irrational1 V2 rail";
CM_ SG_ 1060 PCS_a093_irrational1V5Rail "Power conversion system (on-board charger and DC-DC converter): a093 irrational1 V5 rail";
CM_ SG_ 1060 PCS_a093_irrational3V3Rail "Power conversion system (on-board charger and DC-DC converter): a093 irrational3 V3 rail";
CM_ SG_ 1060 PCS_a093_irrational5VNRail "Power conversion system (on-board charger and DC-DC converter): a093 irrational5 VN rail";
CM_ SG_ 1060 PCS_a094_malfunctionCode "Power conversion system (on-board charger and DC-DC converter): a094 malfunction code";
CM_ SG_ 1060 PCS_a095_powerRail5VN "Power conversion system (on-board charger and DC-DC converter): a095 power rail5 VN";
CM_ SG_ 1060 PCS_a095_pcsControlRequest "Power conversion system (on-board charger and DC-DC converter): a095 pcs control request";
CM_ SG_ 1060 PCS_a096_gridConfig "Power conversion system (on-board charger and DC-DC converter): a096 grid config; raw 0 = signal not available (SNA)";
CM_ SG_ 1060 PCS_a096_phAFrequency "Power conversion system (on-board charger and DC-DC converter): a096 ph a frequency";
CM_ SG_ 1060 PCS_a096_phBFrequency "Power conversion system (on-board charger and DC-DC converter): a096 ph b frequency";
CM_ SG_ 1060 PCS_a096_phCFrequency "Power conversion system (on-board charger and DC-DC converter): a096 ph c frequency";
CM_ SG_ 1060 PCS_a097_phADamaged "Power conversion system (on-board charger and DC-DC converter): a097 ph a damaged";
CM_ SG_ 1060 PCS_a097_phBDamaged "Power conversion system (on-board charger and DC-DC converter): a097 ph b damaged";
CM_ SG_ 1060 PCS_a097_phCDamaged "Power conversion system (on-board charger and DC-DC converter): a097 ph c damaged";
CM_ SG_ 1060 PCS_a097_phANVRAMStoredState "Power conversion system (on-board charger and DC-DC converter): a097 ph ANVRAM stored state";
CM_ SG_ 1060 PCS_a097_phBNVRAMStoredState "Power conversion system (on-board charger and DC-DC converter): a097 ph BNVRAM stored state";
CM_ SG_ 1060 PCS_a097_phCNVRAMStoredState "Power conversion system (on-board charger and DC-DC converter): a097 ph CNVRAM stored state";
CM_ SG_ 1060 PCS_a100_inputVrms "Power conversion system (on-board charger and DC-DC converter): a100 input vrms";
CM_ SG_ 1060 PCS_a100_phIntBusVolt "Power conversion system (on-board charger and DC-DC converter): a100 ph int bus volt";
CM_ SG_ 1060 PCS_a100_phKwhCounter "Power conversion system (on-board charger and DC-DC converter): a100 ph kwh counter";
CM_ SG_ 1060 PCS_a100_phKwhCounterDeltaFromMa "Power conversion system (on-board charger and DC-DC converter): a100 ph kwh counter delta from max";
CM_ SG_ 1060 PCS_a102_pcsControlRequest "Power conversion system (on-board charger and DC-DC converter): a102 pcs control request";
CM_ SG_ 1060 PCS_a102_NMIFlagRegisters "Power conversion system (on-board charger and DC-DC converter): a102 NMI flag registers";
CM_ SG_ 1060 PCS_a102_systemResetRegisters "Power conversion system (on-board charger and DC-DC converter): a102 system reset registers";
CM_ SG_ 1060 PCS_a102_dcdcEnableLine "Power conversion system (on-board charger and DC-DC converter): a102 dcdc enable line";
CM_ SG_ 1060 PCS_a104_ambientTemperature "Power conversion system (on-board charger and DC-DC converter): a104 ambient temperature";
CM_ SG_ 1060 PCS_a107_VC_pcsInterface "Power conversion system (on-board charger and DC-DC converter): a107 VC pcs interface";
CM_ SG_ 1060 PCS_a108_installedInAWrongPlatfo "Power conversion system (on-board charger and DC-DC converter): a108 installed in a wrong platform";
CM_ SG_ 1060 PCS_a109_inputL2NVrms "Power conversion system (on-board charger and DC-DC converter): a109 input L2 n vrms";
CM_ SG_ 1060 PCS_a109_inputL3NVrms "Power conversion system (on-board charger and DC-DC converter): a109 input L3 n vrms";
BA_DEF_ BO_ "GenMsgCycleTime" INT 0 3600000;
BA_DEF_ BO_ "GenMsgSendType" ENUM "Cyclic","NotUsed","NotUsed","NotUsed","NotUsed","NotUsed","NotUsed","IfActive","NoMsgSendType","NotUsed";
BA_DEF_ BO_ "VFrameFormat" ENUM "StandardCAN","ExtendedCAN","reserved","J1939PG","reserved","reserved","reserved","reserved","reserved","reserved","reserved","reserved","reserved","reserved","StandardCAN_FD","ExtendedCAN_FD";
BA_DEF_ BO_ "CANFD_BRS" ENUM "0","1";
BA_DEF_ SG_ "GenSigSNA" STRING;
BA_DEF_ SG_ "SystemSignalLongSymbol" STRING;
BA_DEF_ SG_ "Confidence" ENUM "validated","plausible","layout-only","contradicted";
BA_DEF_DEF_ "GenMsgCycleTime" 0;
BA_DEF_DEF_ "GenMsgSendType" "NoMsgSendType";
BA_DEF_DEF_ "VFrameFormat" "StandardCAN";
BA_DEF_DEF_ "CANFD_BRS" "1";
BA_DEF_DEF_ "GenSigSNA" "";
BA_DEF_DEF_ "SystemSignalLongSymbol" "";
BA_DEF_DEF_ "Confidence" "layout-only";
BA_ "GenMsgCycleTime" BO_ 1962 1000;
BA_ "GenMsgSendType" BO_ 1962 0;
BA_ "GenMsgCycleTime" BO_ 554 100;
BA_ "GenMsgSendType" BO_ 554 0;
BA_ "GenMsgCycleTime" BO_ 784 10000;
BA_ "GenMsgSendType" BO_ 784 0;
BA_ "GenMsgCycleTime" BO_ 1914 1000;
BA_ "GenMsgSendType" BO_ 1914 0;
BA_ "GenMsgCycleTime" BO_ 952 100;
BA_ "GenMsgSendType" BO_ 952 0;
BA_ "GenMsgCycleTime" BO_ 941 10000;
BA_ "GenMsgSendType" BO_ 941 0;
BA_ "GenMsgCycleTime" BO_ 536 100;
BA_ "GenMsgSendType" BO_ 536 0;
BA_ "GenMsgCycleTime" BO_ 670 100;
BA_ "GenMsgSendType" BO_ 670 0;
BA_ "GenMsgCycleTime" BO_ 664 100;
BA_ "GenMsgSendType" BO_ 664 0;
BA_ "Confidence" SG_ 1962 HVP_debugMessageMultiplexer 1;
BA_ "Confidence" SG_ 1962 HVP_gpioPassivePyroDepl 0;
BA_ "Confidence" SG_ 1962 HVP_gpioPyroIsoEn 0;
BA_ "Confidence" SG_ 1962 HVP_gpioCpFaultIn 0;
BA_ "Confidence" SG_ 1962 HVP_gpioPackContPowerEn 0;
BA_ "Confidence" SG_ 1962 HVP_gpioHvCablesOk 0;
BA_ "Confidence" SG_ 1962 HVP_gpioHvpSelfEnable 0;
BA_ "Confidence" SG_ 1962 HVP_gpioLed 0;
BA_ "Confidence" SG_ 1962 HVP_gpioCrashSignal 0;
BA_ "Confidence" SG_ 1962 HVP_gpioShuntDataReady 0;
BA_ "Confidence" SG_ 1962 HVP_gpioFcContPosAux 0;
BA_ "Confidence" SG_ 1962 HVP_gpioFcContNegAux 0;
BA_ "Confidence" SG_ 1962 HVP_gpioBmsEout 0;
BA_ "Confidence" SG_ 1962 HVP_gpioCpFaultOut 0;
BA_ "Confidence" SG_ 1962 HVP_gpioPyroPor 0;
BA_ "Confidence" SG_ 1962 HVP_gpioShuntEn 0;
BA_ "Confidence" SG_ 1962 HVP_gpioHvpVerEn 0;
BA_ "Confidence" SG_ 1962 HVP_gpioFcContFlywheelEnable 0;
BA_ "Confidence" SG_ 1962 HVP_gpioCpLatchEnable 0;
BA_ "Confidence" SG_ 1962 HVP_gpioFcContPowerEnable 0;
BA_ "Confidence" SG_ 1962 HVP_gpioHvilEnable 0;
BA_ "Confidence" SG_ 1962 HVP_gpioPortSelSpiRdy 0;
BA_ "Confidence" SG_ 1962 HVP_gpioPyroUnlock 0;
BA_ "Confidence" SG_ 1962 HVP_hvp1v5Ref 0;
BA_ "Confidence" SG_ 1962 HVP_packCurrentMia 0;
BA_ "Confidence" SG_ 1962 HVP_auxCurrentMia 0;
BA_ "Confidence" SG_ 1962 HVP_currentSenseMia 0;
BA_ "Confidence" SG_ 1962 HVP_shuntThermistorMissing 0;
BA_ "Confidence" SG_ 1962 HVP_shuntThermistorExpected 0;
BA_ "Confidence" SG_ 1962 HVP_shuntThermistorMia 0;
BA_ "Confidence" SG_ 1962 HVP_shuntUnexpectedThermistor 0;
BA_ "Confidence" SG_ 1962 HVP_shuntHwMia 0;
BA_ "Confidence" SG_ 1962 HVP_shuntCurrentIrrational 0;
BA_ "Confidence" SG_ 1962 HVP_shuntAsicTCompActive 0;
BA_ "Confidence" SG_ 1962 HVP_ecuLogUploadRequest 1;
BA_ "Confidence" SG_ 1962 HVP_packContVoltage 0;
BA_ "Confidence" SG_ 1962 HVP_packNegativeV 0;
BA_ "Confidence" SG_ 1962 HVP_packPositiveV 0;
BA_ "Confidence" SG_ 1962 HVP_pyroAnalog 0;
BA_ "Confidence" SG_ 1962 HVP_fcContCoilCurrent 0;
BA_ "Confidence" SG_ 1962 HVP_fcContVoltage 0;
BA_ "Confidence" SG_ 1962 HVP_hvilInVoltage 0;
BA_ "Confidence" SG_ 1962 HVP_hvilOutVoltage 0;
BA_ "Confidence" SG_ 1962 HVP_shuntGainInvalidCountDbg 0;
BA_ "Confidence" SG_ 1962 HVP_fcLinkPositiveV 1;
BA_ "Confidence" SG_ 1962 HVP_packContCoilCurrent 0;
BA_ "Confidence" SG_ 1962 HVP_battery12V 0;
BA_ "Confidence" SG_ 1962 HVP_shuntRefVoltageDbg 1;
BA_ "Confidence" SG_ 554 HVP_dcLinkVoltageRequest 0;
BA_ "Confidence" SG_ 554 HVP_pcsControlRequest 0;
BA_ "Confidence" SG_ 554 HVP_pcsChargeHwEnabled 0;
BA_ "Confidence" SG_ 554 HVP_pcsDcdcHwEnabled 0;
BA_ "Confidence" SG_ 554 HVP_dcLinkVoltageFiltered 0;
BA_ "GenSigSNA" SG_ 554 HVP_dcLinkVoltageFiltered "1498";
BA_ "Confidence" SG_ 784 HVP_infoIndex 1;
BA_ "Confidence" SG_ 784 HVP_buildType 0;
BA_ "Confidence" SG_ 784 HVP_buildConfigId 0;
BA_ "Confidence" SG_ 784 HVP_hardwareId 0;
BA_ "Confidence" SG_ 784 HVP_componentId 0;
BA_ "Confidence" SG_ 784 HVP_pcbaId 0;
BA_ "Confidence" SG_ 784 HVP_assemblyId 0;
BA_ "Confidence" SG_ 784 HVP_usageId 0;
BA_ "Confidence" SG_ 784 HVP_subUsageId 0;
BA_ "Confidence" SG_ 784 HVP_platformType 0;
BA_ "Confidence" SG_ 784 HVP_appCrc 0;
BA_ "Confidence" SG_ 784 HVP_appGitHash 0;
BA_ "Confidence" SG_ 784 HVP_bootGitHash 0;
BA_ "Confidence" SG_ 784 HVP_bootUdsProtoVersion 0;
BA_ "Confidence" SG_ 784 HVP_bootCrc 0;
BA_ "Confidence" SG_ 1914 HVP_log1HzIndex 1;
BA_ "Confidence" SG_ 1914 HVP_bmbAsicType 0;
BA_ "Confidence" SG_ 1914 HVP_shuntCurrentAuxLog 0;
BA_ "Confidence" SG_ 1914 HVP_pyroSquibResistance 0;
BA_ "GenSigSNA" SG_ 1914 HVP_pyroSquibResistance "65535";
BA_ "Confidence" SG_ 1914 HVP_shuntAsicChipXCoordinate 0;
BA_ "Confidence" SG_ 1914 HVP_shuntAsicChipYCoordinate 0;
BA_ "Confidence" SG_ 1914 HVP_hvilCalType 0;
BA_ "Confidence" SG_ 1914 HVP_gpioPcsDcdcPwmEnable 0;
BA_ "Confidence" SG_ 1914 HVP_gpioPcsChargePwmEnable 0;
BA_ "Confidence" SG_ 1914 HVP_gpioPcsEnable 0;
BA_ "Confidence" SG_ 1914 HVP_shuntAsicChipWaferNumber 0;
BA_ "Confidence" SG_ 1914 HVP_energyReserveMin 0;
BA_ "Confidence" SG_ 1914 HVP_energyReserveMax 0;
BA_ "Confidence" SG_ 1914 HVP_energyReserveAvg 0;
BA_ "Confidence" SG_ 1208 ICR_alertID 1;
BA_ "Confidence" SG_ 1208 ICR_alertState 1;
BA_ "SystemSignalLongSymbol" SG_ 1208 ICR_a001_watchdogTaskSentinelInt "ICR_a001_watchdogTaskSentinelInterface";
BA_ "SystemSignalLongSymbol" SG_ 1208 ICR_a001_watchdogTaskSentinelMod "ICR_a001_watchdogTaskSentinelModeChange";
BA_ "Confidence" SG_ 1208 ICR_a059_voltageDrop 1;
BA_ "Confidence" SG_ 1208 ICR_a059_resistanceEstimate 1;
BA_ "Confidence" SG_ 1208 ICR_a059_current 1;
BA_ "Confidence" SG_ 1208 ICR_a063_ADCVoltage 1;
BA_ "Confidence" SG_ 1208 ICR_a133_nearClutter 1;
BA_ "Confidence" SG_ 1208 ICR_a133_farClutter 1;
BA_ "Confidence" SG_ 1208 ICR_a137_nearClutter 1;
BA_ "Confidence" SG_ 1208 ICR_a137_farClutter 1;
BA_ "Confidence" SG_ 1208 ICR_a139_nearClutter 1;
BA_ "Confidence" SG_ 1208 ICR_a139_farClutter 1;
BA_ "Confidence" SG_ 952 ICR_matrixIndex 1;
BA_ "SystemSignalLongSymbol" SG_ 952 ICR_a139_AbnormalBlockageDetecte "ICR_a139_AbnormalBlockageDetected";
BA_ "SystemSignalLongSymbol" SG_ 952 ICR_a140_OccupancyExceptionEncou "ICR_a140_OccupancyExceptionEncountered";
BA_ "Confidence" SG_ 941 ICR_infoIndex 1;
BA_ "Confidence" SG_ 941 ICR_infoBuildType 0;
BA_ "Confidence" SG_ 941 ICR_infoPcbaId 0;
BA_ "Confidence" SG_ 941 ICR_infoAssemblyId 0;
BA_ "Confidence" SG_ 941 ICR_infoUsageId 0;
BA_ "Confidence" SG_ 941 ICR_infoAppCrc 0;
BA_ "Confidence" SG_ 941 ICR_infoBoardPartNumber17 0;
BA_ "Confidence" SG_ 941 ICR_infoBoardPartNumber814 0;
BA_ "Confidence" SG_ 941 ICR_infoBoardPartNumber1520 0;
BA_ "Confidence" SG_ 536 ICR_occupancy1LRaw 0;
BA_ "GenSigSNA" SG_ 536 ICR_occupancy1LRaw "3";
BA_ "Confidence" SG_ 536 ICR_occupancy1RRaw 0;
BA_ "GenSigSNA" SG_ 536 ICR_occupancy1RRaw "3";
BA_ "Confidence" SG_ 536 ICR_occupancy1LVoteCnt 0;
BA_ "Confidence" SG_ 536 ICR_occupancy1RVoteCnt 0;
BA_ "Confidence" SG_ 536 ICR_userPresenceFilt 1;
BA_ "GenSigSNA" SG_ 536 ICR_userPresenceFilt "3";
BA_ "Confidence" SG_ 536 ICR_userPresenceRaw 1;
BA_ "GenSigSNA" SG_ 536 ICR_userPresenceRaw "3";
BA_ "Confidence" SG_ 536 ICR_occupancy1LFilt 1;
BA_ "GenSigSNA" SG_ 536 ICR_occupancy1LFilt "3";
BA_ "Confidence" SG_ 536 ICR_occupancy1RFilt 1;
BA_ "GenSigSNA" SG_ 536 ICR_occupancy1RFilt "3";
BA_ "Confidence" SG_ 536 ICR_occupancy2LFilt 1;
BA_ "GenSigSNA" SG_ 536 ICR_occupancy2LFilt "3";
BA_ "Confidence" SG_ 536 ICR_occupancy2CFilt 1;
BA_ "GenSigSNA" SG_ 536 ICR_occupancy2CFilt "3";
BA_ "Confidence" SG_ 536 ICR_occupancy2RFilt 1;
BA_ "GenSigSNA" SG_ 536 ICR_occupancy2RFilt "3";
BA_ "Confidence" SG_ 536 ICR_childPresenceFilt 1;
BA_ "GenSigSNA" SG_ 536 ICR_childPresenceFilt "0";
BA_ "Confidence" SG_ 536 ICR_childPresenceRaw 1;
BA_ "GenSigSNA" SG_ 536 ICR_childPresenceRaw "0";
BA_ "Confidence" SG_ 536 ICR_classification1LFilt 1;
BA_ "GenSigSNA" SG_ 536 ICR_classification1LFilt "0";
BA_ "Confidence" SG_ 536 ICR_classification1RqF 1;
BA_ "Confidence" SG_ 536 ICR_occupancy1RFiltExp 1;
BA_ "GenSigSNA" SG_ 536 ICR_occupancy1RFiltExp "3";
BA_ "Confidence" SG_ 670 ICR_userPresenceMLOutput 1;
BA_ "GenSigSNA" SG_ 670 ICR_userPresenceMLOutput "255";
BA_ "Confidence" SG_ 670 ICR_childPresenceMLOutput 1;
BA_ "GenSigSNA" SG_ 670 ICR_childPresenceMLOutput "255";
BA_ "Confidence" SG_ 670 ICR_classification1RFilt 1;
BA_ "GenSigSNA" SG_ 670 ICR_classification1RFilt "0";
BA_ "Confidence" SG_ 670 ICR_classification1LRaw 1;
BA_ "GenSigSNA" SG_ 670 ICR_classification1LRaw "0";
BA_ "Confidence" SG_ 670 ICR_classification1RRaw 1;
BA_ "GenSigSNA" SG_ 670 ICR_classification1RRaw "0";
BA_ "Confidence" SG_ 670 ICR_classification1LMLOutput 1;
BA_ "GenSigSNA" SG_ 670 ICR_classification1LMLOutput "255";
BA_ "Confidence" SG_ 670 ICR_classification1RMLOutput 1;
BA_ "GenSigSNA" SG_ 670 ICR_classification1RMLOutput "255";
BA_ "Confidence" SG_ 670 ICR_occupancy2Checksum 0;
BA_ "Confidence" SG_ 664 ICR_sensorMode 1;
BA_ "Confidence" SG_ 664 ICR_blocked 1;
BA_ "GenSigSNA" SG_ 664 ICR_blocked "0";
BA_ "Confidence" SG_ 664 ICR_algoVersion 1;
BA_ "Confidence" SG_ 664 ICR_l2HeapUsage 1;
BA_ "Confidence" SG_ 664 ICR_intrusionStatus 1;
BA_ "Confidence" SG_ 664 ICR_booted 1;
BA_ "Confidence" SG_ 1012 LS_lightShowIndex 1;
BA_ "Confidence" SG_ 1012 LS_lightLeftRampedChannel1Reques 0;
BA_ "SystemSignalLongSymbol" SG_ 1012 LS_lightLeftRampedChannel1Reques "LS_lightLeftRampedChannel1Request";
BA_ "Confidence" SG_ 1012 LS_lightLeftRampedChannel1Durati 0;
BA_ "SystemSignalLongSymbol" SG_ 1012 LS_lightLeftRampedChannel1Durati "LS_lightLeftRampedChannel1Duration";
BA_ "Confidence" SG_ 1012 LS_lightLeftRampedChannel2Reques 0;
BA_ "SystemSignalLongSymbol" SG_ 1012 LS_lightLeftRampedChannel2Reques "LS_lightLeftRampedChannel2Request";
BA_ "Confidence" SG_ 1012 LS_lightLeftRampedChannel2Durati 0;
BA_ "SystemSignalLongSymbol" SG_ 1012 LS_lightLeftRampedChannel2Durati "LS_lightLeftRampedChannel2Duration";
BA_ "Confidence" SG_ 1012 LS_lightLeftRampedChannel3Reques 0;
BA_ "SystemSignalLongSymbol" SG_ 1012 LS_lightLeftRampedChannel3Reques "LS_lightLeftRampedChannel3Request";
BA_ "Confidence" SG_ 1012 LS_lightLeftRampedChannel3Durati 0;
BA_ "SystemSignalLongSymbol" SG_ 1012 LS_lightLeftRampedChannel3Durati "LS_lightLeftRampedChannel3Duration";
BA_ "Confidence" SG_ 1012 LS_lightLeftRampedChannel4Reques 0;
BA_ "SystemSignalLongSymbol" SG_ 1012 LS_lightLeftRampedChannel4Reques "LS_lightLeftRampedChannel4Request";
BA_ "Confidence" SG_ 1012 LS_lightLeftRampedChannel4Durati 0;
BA_ "SystemSignalLongSymbol" SG_ 1012 LS_lightLeftRampedChannel4Durati "LS_lightLeftRampedChannel4Duration";
BA_ "Confidence" SG_ 1012 LS_lightLeftRampedChannel5Reques 0;
BA_ "SystemSignalLongSymbol" SG_ 1012 LS_lightLeftRampedChannel5Reques "LS_lightLeftRampedChannel5Request";
BA_ "Confidence" SG_ 1012 LS_lightLeftRampedChannel5Durati 0;
BA_ "SystemSignalLongSymbol" SG_ 1012 LS_lightLeftRampedChannel5Durati "LS_lightLeftRampedChannel5Duration";
BA_ "Confidence" SG_ 1012 LS_lightLeftRampedChannel6Reques 0;
BA_ "SystemSignalLongSymbol" SG_ 1012 LS_lightLeftRampedChannel6Reques "LS_lightLeftRampedChannel6Request";
BA_ "Confidence" SG_ 1012 LS_lightLeftRampedChannel6Durati 0;
BA_ "SystemSignalLongSymbol" SG_ 1012 LS_lightLeftRampedChannel6Durati "LS_lightLeftRampedChannel6Duration";
BA_ "Confidence" SG_ 1012 LS_lightLeftRampedChannel7Reques 0;
BA_ "SystemSignalLongSymbol" SG_ 1012 LS_lightLeftRampedChannel7Reques "LS_lightLeftRampedChannel7Request";
BA_ "Confidence" SG_ 1012 LS_lightLeftRampedChannel7Durati 0;
BA_ "SystemSignalLongSymbol" SG_ 1012 LS_lightLeftRampedChannel7Durati "LS_lightLeftRampedChannel7Duration";
BA_ "Confidence" SG_ 1012 LS_lightRightRampedChannel1Reque 0;
BA_ "SystemSignalLongSymbol" SG_ 1012 LS_lightRightRampedChannel1Reque "LS_lightRightRampedChannel1Request";
BA_ "Confidence" SG_ 1012 LS_lightRightRampedChannel1Durat 0;
BA_ "GenSigSNA" SG_ 1012 LS_lightRightRampedChannel1Durat "1";
BA_ "SystemSignalLongSymbol" SG_ 1012 LS_lightRightRampedChannel1Durat "LS_lightRightRampedChannel1Duration";
BA_ "Confidence" SG_ 1012 LS_lightRightRampedChannel2Reque 0;
BA_ "SystemSignalLongSymbol" SG_ 1012 LS_lightRightRampedChannel2Reque "LS_lightRightRampedChannel2Request";
BA_ "Confidence" SG_ 1012 LS_lightRightRampedChannel2Durat 0;
BA_ "GenSigSNA" SG_ 1012 LS_lightRightRampedChannel2Durat "1";
BA_ "SystemSignalLongSymbol" SG_ 1012 LS_lightRightRampedChannel2Durat "LS_lightRightRampedChannel2Duration";
BA_ "Confidence" SG_ 1012 LS_lightRightRampedChannel3Reque 0;
BA_ "SystemSignalLongSymbol" SG_ 1012 LS_lightRightRampedChannel3Reque "LS_lightRightRampedChannel3Request";
BA_ "Confidence" SG_ 1012 LS_lightRightRampedChannel3Durat 0;
BA_ "SystemSignalLongSymbol" SG_ 1012 LS_lightRightRampedChannel3Durat "LS_lightRightRampedChannel3Duration";
BA_ "Confidence" SG_ 1012 LS_lightRightRampedChannel4Reque 0;
BA_ "SystemSignalLongSymbol" SG_ 1012 LS_lightRightRampedChannel4Reque "LS_lightRightRampedChannel4Request";
BA_ "Confidence" SG_ 1012 LS_lightRightRampedChannel4Durat 0;
BA_ "SystemSignalLongSymbol" SG_ 1012 LS_lightRightRampedChannel4Durat "LS_lightRightRampedChannel4Duration";
BA_ "Confidence" SG_ 1012 LS_lightRightRampedChannel5Reque 0;
BA_ "SystemSignalLongSymbol" SG_ 1012 LS_lightRightRampedChannel5Reque "LS_lightRightRampedChannel5Request";
BA_ "Confidence" SG_ 1012 LS_lightRightRampedChannel5Durat 0;
BA_ "SystemSignalLongSymbol" SG_ 1012 LS_lightRightRampedChannel5Durat "LS_lightRightRampedChannel5Duration";
BA_ "Confidence" SG_ 1012 LS_lightRightRampedChannel6Reque 0;
BA_ "SystemSignalLongSymbol" SG_ 1012 LS_lightRightRampedChannel6Reque "LS_lightRightRampedChannel6Request";
BA_ "Confidence" SG_ 1012 LS_lightRightRampedChannel6Durat 0;
BA_ "SystemSignalLongSymbol" SG_ 1012 LS_lightRightRampedChannel6Durat "LS_lightRightRampedChannel6Duration";
BA_ "Confidence" SG_ 1012 LS_lightRightRampedChannel7Reque 0;
BA_ "SystemSignalLongSymbol" SG_ 1012 LS_lightRightRampedChannel7Reque "LS_lightRightRampedChannel7Request";
BA_ "Confidence" SG_ 1012 LS_lightRightRampedChannel7Durat 0;
BA_ "SystemSignalLongSymbol" SG_ 1012 LS_lightRightRampedChannel7Durat "LS_lightRightRampedChannel7Duration";
BA_ "Confidence" SG_ 1012 LS_lightRearTurnLeftRequest 0;
BA_ "Confidence" SG_ 1012 LS_lightRearTurnRightRequest 0;
BA_ "Confidence" SG_ 1012 LS_lightSideRepeaterLeftRequest 0;
BA_ "Confidence" SG_ 1012 LS_lightSideRepeaterRightRequest 0;
BA_ "Confidence" SG_ 1012 LS_lightSideMarkerLeftRequest 0;
BA_ "Confidence" SG_ 1012 LS_lightSideMarkerRightRequest 0;
BA_ "Confidence" SG_ 1012 LS_lightFrontFogLeftRequest 0;
BA_ "Confidence" SG_ 1012 LS_lightFrontFogRightRequest 0;
BA_ "Confidence" SG_ 1012 LS_lightRearFogRequest 0;
BA_ "Confidence" SG_ 1012 LS_lightBrakeRequest 0;
BA_ "Confidence" SG_ 1012 LS_lightTailLeftRequest 0;
BA_ "Confidence" SG_ 1012 LS_lightTailRightRequest 0;
BA_ "Confidence" SG_ 1012 LS_lightLicensePlateRequest 0;
BA_ "Confidence" SG_ 1012 LS_lightReverseRequest 0;
BA_ "Confidence" SG_ 1012 LS_lightAuxParkLeftRequest 0;
BA_ "Confidence" SG_ 1012 LS_lightAuxParkRightRequest 0;
BA_ "Confidence" SG_ 1012 LS_mirrorRequestLeft 0;
BA_ "Confidence" SG_ 1012 LS_mirrorRequestRight 0;
BA_ "Confidence" SG_ 1012 LS_liftgateRequest 0;
BA_ "Confidence" SG_ 1012 LS_windowRequestLF 0;
BA_ "Confidence" SG_ 1012 LS_windowRequestLR 0;
BA_ "Confidence" SG_ 1012 LS_windowRequestRF 0;
BA_ "Confidence" SG_ 1012 LS_windowRequestRR 0;
BA_ "Confidence" SG_ 1012 LS_presentingHandleRequestLF 0;
BA_ "Confidence" SG_ 1012 LS_presentingHandleRequestLR 0;
BA_ "Confidence" SG_ 1012 LS_presentingHandleRequestRF 0;
BA_ "Confidence" SG_ 1012 LS_presentingHandleRequestRR 0;
BA_ "Confidence" SG_ 1012 LS_powerFrontDoorRequestLeft 0;
BA_ "Confidence" SG_ 1012 LS_powerFrontDoorRequestRight 0;
BA_ "Confidence" SG_ 1012 LS_falconDoorRequestLeft 0;
BA_ "Confidence" SG_ 1012 LS_falconDoorRequestRight 0;
BA_ "Confidence" SG_ 1012 LS_chargePortRequest 0;
BA_ "GenSigSNA" SG_ 1012 LS_chargePortRequest "3";
BA_ "Confidence" SG_ 1012 LS_chargePortRaveRequest 0;
BA_ "Confidence" SG_ 1012 LS_suspensionRequest 0;
BA_ "GenSigSNA" SG_ 1012 LS_suspensionRequest "3";
BA_ "Confidence" SG_ 1012 LS_rgbIPFLRed 0;
BA_ "Confidence" SG_ 1012 LS_rgbIPFLGreen 0;
BA_ "Confidence" SG_ 1012 LS_rgbIPFLBlue 0;
BA_ "Confidence" SG_ 1012 LS_rgbIPFRRed 0;
BA_ "Confidence" SG_ 1012 LS_rgbIPFRGreen 0;
BA_ "Confidence" SG_ 1012 LS_rgbIPFRBlue 0;
BA_ "Confidence" SG_ 1012 LS_rgbDoorFLForeRed 0;
BA_ "Confidence" SG_ 1012 LS_rgbDoorFLForeGreen 0;
BA_ "Confidence" SG_ 1012 LS_rgbDoorFLForeBlue 0;
BA_ "Confidence" SG_ 1012 LS_rgbDoorFLAftRed 0;
BA_ "Confidence" SG_ 1012 LS_rgbDoorFLAftGreen 0;
BA_ "Confidence" SG_ 1012 LS_rgbDoorFLAftBlue 0;
BA_ "Confidence" SG_ 1012 LS_rgbDoorFRForeRed 0;
BA_ "Confidence" SG_ 1012 LS_rgbDoorFRForeGreen 0;
BA_ "Confidence" SG_ 1012 LS_rgbDoorFRForeBlue 0;
BA_ "Confidence" SG_ 1012 LS_rgbDoorFRAftRed 0;
BA_ "Confidence" SG_ 1012 LS_rgbDoorFRAftGreen 0;
BA_ "Confidence" SG_ 1012 LS_rgbDoorFRAftBlue 0;
BA_ "Confidence" SG_ 1012 LS_rgbDoorRLForeRed 0;
BA_ "Confidence" SG_ 1012 LS_rgbDoorRLForeGreen 0;
BA_ "Confidence" SG_ 1012 LS_rgbDoorRLForeBlue 0;
BA_ "Confidence" SG_ 1012 LS_rgbDoorRLAftRed 0;
BA_ "Confidence" SG_ 1012 LS_rgbDoorRLAftGreen 0;
BA_ "Confidence" SG_ 1012 LS_rgbDoorRLAftBlue 0;
BA_ "Confidence" SG_ 1012 LS_rgbDoorRRForeRed 0;
BA_ "Confidence" SG_ 1012 LS_rgbDoorRRForeGreen 0;
BA_ "Confidence" SG_ 1012 LS_rgbDoorRRForeBlue 0;
BA_ "Confidence" SG_ 1012 LS_rgbDoorRRAftRed 0;
BA_ "Confidence" SG_ 1012 LS_rgbDoorRRAftGreen 0;
BA_ "Confidence" SG_ 1012 LS_rgbDoorRRAftBlue 0;
BA_ "Confidence" SG_ 1012 LS_frontMatrix0 0;
BA_ "Confidence" SG_ 1012 LS_frontMatrix1 0;
BA_ "Confidence" SG_ 1012 LS_frontMatrix2 0;
BA_ "Confidence" SG_ 1012 LS_frontMatrix3 0;
BA_ "Confidence" SG_ 1012 LS_frontMatrix4 0;
BA_ "Confidence" SG_ 1012 LS_frontMatrix5 0;
BA_ "Confidence" SG_ 1012 LS_frontMatrix6 0;
BA_ "Confidence" SG_ 1012 LS_frontMatrix7 0;
BA_ "Confidence" SG_ 1012 LS_frontMatrix8 0;
BA_ "Confidence" SG_ 1012 LS_frontMatrix9 0;
BA_ "Confidence" SG_ 1012 LS_frontMatrix10 0;
BA_ "Confidence" SG_ 1012 LS_frontMatrix11 0;
BA_ "Confidence" SG_ 1012 LS_frontMatrix12 0;
BA_ "Confidence" SG_ 1012 LS_frontMatrix13 0;
BA_ "Confidence" SG_ 1012 LS_frontMatrix14 0;
BA_ "Confidence" SG_ 1012 LS_frontMatrix15 0;
BA_ "Confidence" SG_ 1012 LS_frontMatrix16 0;
BA_ "Confidence" SG_ 1012 LS_frontMatrix17 0;
BA_ "Confidence" SG_ 1012 LS_frontMatrix18 0;
BA_ "Confidence" SG_ 1012 LS_frontMatrix19 0;
BA_ "Confidence" SG_ 1012 LS_frontMatrix20 0;
BA_ "Confidence" SG_ 1012 LS_frontMatrix21 0;
BA_ "Confidence" SG_ 1012 LS_frontMatrix22 0;
BA_ "Confidence" SG_ 1012 LS_frontMatrix23 0;
BA_ "Confidence" SG_ 1012 LS_frontMatrix24 0;
BA_ "Confidence" SG_ 1012 LS_frontMatrix25 0;
BA_ "Confidence" SG_ 1012 LS_frontMatrix26 0;
BA_ "Confidence" SG_ 1012 LS_frontMatrix27 0;
BA_ "Confidence" SG_ 1012 LS_frontMatrix28 0;
BA_ "Confidence" SG_ 1012 LS_frontMatrix29 0;
BA_ "Confidence" SG_ 1012 LS_frontMatrix30 0;
BA_ "Confidence" SG_ 1012 LS_frontMatrix31 0;
BA_ "Confidence" SG_ 1012 LS_frontMatrix32 0;
BA_ "Confidence" SG_ 1012 LS_frontMatrix33 0;
BA_ "Confidence" SG_ 1012 LS_frontMatrix34 0;
BA_ "Confidence" SG_ 1012 LS_frontMatrix35 0;
BA_ "Confidence" SG_ 1012 LS_frontMatrix36 0;
BA_ "Confidence" SG_ 1012 LS_frontMatrix37 0;
BA_ "Confidence" SG_ 1012 LS_frontMatrix38 0;
BA_ "Confidence" SG_ 1012 LS_frontMatrix39 0;
BA_ "Confidence" SG_ 1012 LS_frontMatrix40 0;
BA_ "Confidence" SG_ 1012 LS_frontMatrix41 0;
BA_ "Confidence" SG_ 1012 LS_frontMatrix42 0;
BA_ "Confidence" SG_ 1012 LS_frontMatrix43 0;
BA_ "Confidence" SG_ 1012 LS_frontMatrix44 0;
BA_ "Confidence" SG_ 1012 LS_frontMatrix45 0;
BA_ "Confidence" SG_ 1012 LS_frontMatrix46 0;
BA_ "Confidence" SG_ 1012 LS_frontMatrix47 0;
BA_ "Confidence" SG_ 1012 LS_frontMatrix48 0;
BA_ "Confidence" SG_ 1012 LS_frontMatrix49 0;
BA_ "Confidence" SG_ 1012 LS_frontMatrix50 0;
BA_ "Confidence" SG_ 1012 LS_frontMatrix51 0;
BA_ "Confidence" SG_ 1012 LS_frontMatrix52 0;
BA_ "Confidence" SG_ 1012 LS_frontMatrix53 0;
BA_ "Confidence" SG_ 1012 LS_frontMatrix54 0;
BA_ "Confidence" SG_ 1012 LS_frontMatrix55 0;
BA_ "Confidence" SG_ 1012 LS_frontMatrix56 0;
BA_ "Confidence" SG_ 1012 LS_frontMatrix57 0;
BA_ "Confidence" SG_ 1012 LS_frontMatrix58 0;
BA_ "Confidence" SG_ 1012 LS_frontMatrix59 0;
BA_ "Confidence" SG_ 1012 LS_rearMatrix0 0;
BA_ "Confidence" SG_ 1012 LS_rearMatrix1 0;
BA_ "Confidence" SG_ 1012 LS_rearMatrix2 0;
BA_ "Confidence" SG_ 1012 LS_rearMatrix3 0;
BA_ "Confidence" SG_ 1012 LS_rearMatrix4 0;
BA_ "Confidence" SG_ 1012 LS_rearMatrix5 0;
BA_ "Confidence" SG_ 1012 LS_rearMatrix6 0;
BA_ "Confidence" SG_ 1012 LS_rearMatrix7 0;
BA_ "Confidence" SG_ 1012 LS_rearMatrix8 0;
BA_ "Confidence" SG_ 1012 LS_rearMatrix9 0;
BA_ "Confidence" SG_ 1012 LS_rearMatrix10 0;
BA_ "Confidence" SG_ 1012 LS_rearMatrix11 0;
BA_ "Confidence" SG_ 1012 LS_rearMatrix12 0;
BA_ "Confidence" SG_ 1012 LS_rearMatrix13 0;
BA_ "Confidence" SG_ 1012 LS_rearMatrix14 0;
BA_ "Confidence" SG_ 1012 LS_rearMatrix15 0;
BA_ "Confidence" SG_ 1012 LS_rearMatrix16 0;
BA_ "Confidence" SG_ 1012 LS_rearMatrix17 0;
BA_ "Confidence" SG_ 1012 LS_rearMatrix18 0;
BA_ "Confidence" SG_ 1012 LS_rearMatrix19 0;
BA_ "Confidence" SG_ 1012 LS_rearMatrix20 0;
BA_ "Confidence" SG_ 1012 LS_rearMatrix21 0;
BA_ "Confidence" SG_ 1012 LS_rearMatrix22 0;
BA_ "Confidence" SG_ 1012 LS_rearMatrix23 0;
BA_ "Confidence" SG_ 1012 LS_rearMatrix24 0;
BA_ "Confidence" SG_ 1012 LS_rearMatrix25 0;
BA_ "Confidence" SG_ 1012 LS_rearMatrix26 0;
BA_ "Confidence" SG_ 1012 LS_rearMatrix27 0;
BA_ "Confidence" SG_ 1012 LS_rearMatrix28 0;
BA_ "Confidence" SG_ 1012 LS_rearMatrix29 0;
BA_ "Confidence" SG_ 1012 LS_rearMatrix30 0;
BA_ "Confidence" SG_ 1012 LS_rearMatrix31 0;
BA_ "Confidence" SG_ 1012 LS_rearMatrix32 0;
BA_ "Confidence" SG_ 1012 LS_rearMatrix33 0;
BA_ "Confidence" SG_ 1012 LS_rearMatrix34 0;
BA_ "Confidence" SG_ 1012 LS_rearMatrix35 0;
BA_ "Confidence" SG_ 1012 LS_rearMatrix36 0;
BA_ "Confidence" SG_ 1012 LS_rearMatrix37 0;
BA_ "Confidence" SG_ 1012 LS_rearMatrix38 0;
BA_ "Confidence" SG_ 1012 LS_rearMatrix39 0;
BA_ "Confidence" SG_ 1012 LS_rearMatrix40 0;
BA_ "Confidence" SG_ 1012 LS_rearMatrix41 0;
BA_ "Confidence" SG_ 1012 LS_rearMatrix42 0;
BA_ "Confidence" SG_ 1012 LS_rearMatrix43 0;
BA_ "Confidence" SG_ 1012 LS_rearMatrix44 0;
BA_ "Confidence" SG_ 1012 LS_rearMatrix45 0;
BA_ "Confidence" SG_ 1012 LS_rearMatrix46 0;
BA_ "Confidence" SG_ 1012 LS_rearMatrix47 0;
BA_ "Confidence" SG_ 1012 LS_rearMatrix48 0;
BA_ "Confidence" SG_ 1012 LS_rearMatrix49 0;
BA_ "Confidence" SG_ 1012 LS_rearMatrix50 0;
BA_ "Confidence" SG_ 1012 LS_rearMatrix51 0;
BA_ "Confidence" SG_ 1012 LS_rearMatrix52 0;
BA_ "Confidence" SG_ 1012 LS_rearMatrix53 0;
BA_ "Confidence" SG_ 1012 LS_rearMatrix54 0;
BA_ "Confidence" SG_ 1012 LS_rearMatrix55 0;
BA_ "Confidence" SG_ 1012 LS_rearMatrix56 0;
BA_ "Confidence" SG_ 1012 LS_rearMatrix57 0;
BA_ "Confidence" SG_ 1012 LS_rearMatrix58 0;
BA_ "Confidence" SG_ 1012 LS_rearMatrix59 0;
BA_ "Confidence" SG_ 1012 LS_offroadLightBar0 0;
BA_ "Confidence" SG_ 1012 LS_offroadLightBar1 0;
BA_ "Confidence" SG_ 1012 LS_offroadLightBar2 0;
BA_ "Confidence" SG_ 1012 LS_offroadLightBar3 0;
BA_ "Confidence" SG_ 1012 LS_offroadLightBar4 0;
BA_ "Confidence" SG_ 1012 LS_offroadLightBar5 0;
BA_ "Confidence" SG_ 1060 PCS_alertID 1;
BA_ "Confidence" SG_ 1060 PCS_alertSet 1;
BA_ "Confidence" SG_ 1060 PCS_alertSource 1;
BA_ "Confidence" SG_ 1060 PCS_a001_llcFrequency 1;
BA_ "Confidence" SG_ 1060 PCS_a001_llcCurrent 1;
BA_ "Confidence" SG_ 1060 PCS_a001_phState 1;
BA_ "Confidence" SG_ 1060 PCS_a001_pfcCurrentRms 1;
BA_ "Confidence" SG_ 1060 PCS_a001_intBusV 1;
BA_ "Confidence" SG_ 1060 PCS_a002_phState 1;
BA_ "Confidence" SG_ 1060 PCS_a003_phState 1;
BA_ "Confidence" SG_ 1060 PCS_a004_phState 1;
BA_ "Confidence" SG_ 1060 PCS_a005_outputV 1;
BA_ "Confidence" SG_ 1060 PCS_a005_outputVOvThreshold 1;
BA_ "Confidence" SG_ 1060 PCS_a006_phState 1;
BA_ "Confidence" SG_ 1060 PCS_a006_intBusPrechargeTarget 1;
BA_ "Confidence" SG_ 1060 PCS_a006_intBusV 1;
BA_ "Confidence" SG_ 1060 PCS_a006_inputVrms 1;
BA_ "Confidence" SG_ 1060 PCS_a006_inputVToIntBusDeltaMax 1;
BA_ "Confidence" SG_ 1060 PCS_a006_inputFrequency 1;
BA_ "Confidence" SG_ 1060 PCS_a007_phATemperature 1;
BA_ "Confidence" SG_ 1060 PCS_a007_phBTemperature 1;
BA_ "Confidence" SG_ 1060 PCS_a007_phCTemperature 1;
BA_ "Confidence" SG_ 1060 PCS_a007_ambientTemperature 1;
BA_ "Confidence" SG_ 1060 PCS_a007_inputVrms 1;
BA_ "Confidence" SG_ 1060 PCS_a007_inputIrms 1;
BA_ "Confidence" SG_ 1060 PCS_a008_phState 1;
BA_ "Confidence" SG_ 1060 PCS_a008_phaseTemperature 1;
BA_ "Confidence" SG_ 1060 PCS_a008_inputVrms 1;
BA_ "Confidence" SG_ 1060 PCS_a008_inputIrms 1;
BA_ "Confidence" SG_ 1060 PCS_a009_phState 1;
BA_ "Confidence" SG_ 1060 PCS_a009_pfcCurrentRms 1;
BA_ "Confidence" SG_ 1060 PCS_a009_pfcCurrentTarget 1;
BA_ "Confidence" SG_ 1060 PCS_a009_llcCurrent 1;
BA_ "Confidence" SG_ 1060 PCS_a009_intBusV 1;
BA_ "Confidence" SG_ 1060 PCS_a010_phState 1;
BA_ "Confidence" SG_ 1060 PCS_a010_pfcCurrentRms 1;
BA_ "Confidence" SG_ 1060 PCS_a010_llcCurrent 1;
BA_ "Confidence" SG_ 1060 PCS_a010_intBusV 1;
BA_ "Confidence" SG_ 1060 PCS_a010_intBusVTarget 1;
BA_ "Confidence" SG_ 1060 PCS_a011_phState 1;
BA_ "Confidence" SG_ 1060 PCS_a011_llcCurrent 1;
BA_ "Confidence" SG_ 1060 PCS_a011_llcCurrentTarget 1;
BA_ "Confidence" SG_ 1060 PCS_a011_llcFrequency 1;
BA_ "Confidence" SG_ 1060 PCS_a011_intBusV 1;
BA_ "Confidence" SG_ 1060 PCS_a011_outputV 1;
BA_ "Confidence" SG_ 1060 PCS_a012_phState 1;
BA_ "Confidence" SG_ 1060 PCS_a012_llcFrequency 1;
BA_ "Confidence" SG_ 1060 PCS_a012_llcCurrent 1;
BA_ "Confidence" SG_ 1060 PCS_a012_outOfIBandDuration 1;
BA_ "Confidence" SG_ 1060 PCS_a012_batteryV 1;
BA_ "Confidence" SG_ 1060 PCS_a012_transientRetryCount 1;
BA_ "Confidence" SG_ 1060 PCS_a013_phState 1;
BA_ "Confidence" SG_ 1060 PCS_a013_intBusPrechargeTarget 1;
BA_ "Confidence" SG_ 1060 PCS_a013_intBusV 1;
BA_ "Confidence" SG_ 1060 PCS_a013_inputVrms 1;
BA_ "Confidence" SG_ 1060 PCS_a013_inputVToIntBusDeltaMax 1;
BA_ "Confidence" SG_ 1060 PCS_a013_inputFrequency 1;
BA_ "Confidence" SG_ 1060 PCS_a014_phaTemperature 1;
BA_ "Confidence" SG_ 1060 PCS_a014_phbTemperature 1;
BA_ "Confidence" SG_ 1060 PCS_a014_phcTemperature 1;
BA_ "Confidence" SG_ 1060 PCS_a015_lvBusVoltage 1;
BA_ "SystemSignalLongSymbol" SG_ 1060 PCS_a016_phAVoltSrcMissingDetect "PCS_a016_phAVoltSrcMissingDetected";
BA_ "SystemSignalLongSymbol" SG_ 1060 PCS_a016_phBVoltSrcMissingDetect "PCS_a016_phBVoltSrcMissingDetected";
BA_ "SystemSignalLongSymbol" SG_ 1060 PCS_a016_phCVoltSrcMissingDetect "PCS_a016_phCVoltSrcMissingDetected";
BA_ "Confidence" SG_ 1060 PCS_a018_PhaseDiff_L1N_L2N 1;
BA_ "Confidence" SG_ 1060 PCS_a018_PhaseDiff_L2N_L3N 1;
BA_ "Confidence" SG_ 1060 PCS_a018_PhaseDiff_L1N_L3N 1;
BA_ "Confidence" SG_ 1060 PCS_a018_PhaseDiff_L1L2_L1N 1;
BA_ "Confidence" SG_ 1060 PCS_a019_pcsMaxAvailablePower 1;
BA_ "Confidence" SG_ 1060 PCS_a019_utilityPowerAvailable 1;
BA_ "Confidence" SG_ 1060 PCS_a019_userPowerRequest 1;
BA_ "Confidence" SG_ 1060 PCS_a025_cpu2ErrorCode 1;
BA_ "SystemSignalLongSymbol" SG_ 1060 PCS_a025_bootromRequestStatusFla "PCS_a025_bootromRequestStatusFlag";
BA_ "Confidence" SG_ 1060 PCS_a027_chgPhATemp 1;
BA_ "Confidence" SG_ 1060 PCS_a027_chgPhBTemp 1;
BA_ "Confidence" SG_ 1060 PCS_a027_chgPhCTemp 1;
BA_ "Confidence" SG_ 1060 PCS_a027_chgPhANoFlowBucket 1;
BA_ "Confidence" SG_ 1060 PCS_a027_chgPhBNoFlowBucket 1;
BA_ "Confidence" SG_ 1060 PCS_a027_chgPhCNoFlowBucket 1;
BA_ "Confidence" SG_ 1060 PCS_a028_outputV 1;
BA_ "Confidence" SG_ 1060 PCS_a028_outputVUvThreshold 1;
BA_ "Confidence" SG_ 1060 PCS_a029_inputVrms 1;
BA_ "Confidence" SG_ 1060 PCS_a029_chgInputPower 1;
BA_ "Confidence" SG_ 1060 PCS_a029_bmsPowerCommand 1;
BA_ "Confidence" SG_ 1060 PCS_a029_phaseConfig 1;
BA_ "GenSigSNA" SG_ 1060 PCS_a029_phaseConfig "0";
BA_ "Confidence" SG_ 1060 PCS_a030_canRxErrorType 1;
BA_ "Confidence" SG_ 1060 PCS_a032_phATransientRetryCount 1;
BA_ "Confidence" SG_ 1060 PCS_a032_phBTransientRetryCount 1;
BA_ "Confidence" SG_ 1060 PCS_a032_phCTransientRetryCount 1;
BA_ "Confidence" SG_ 1060 PCS_a033_HV_busV 1;
BA_ "Confidence" SG_ 1060 PCS_a034_HV_busV 1;
BA_ "Confidence" SG_ 1060 PCS_a035_LV_busV 1;
BA_ "Confidence" SG_ 1060 PCS_a036_LV_busV 1;
BA_ "Confidence" SG_ 1060 PCS_a038_dcdcClaFaultCode 1;
BA_ "Confidence" SG_ 1060 PCS_a038_dcdcSubState 1;
BA_ "Confidence" SG_ 1060 PCS_a038_dcdcLvBusV 1;
BA_ "Confidence" SG_ 1060 PCS_a038_dcdcHvBusV 1;
BA_ "Confidence" SG_ 1060 PCS_a038_dcdcLvBusCurrent_A 1;
BA_ "SystemSignalLongSymbol" SG_ 1060 PCS_a038_dcdcPwmEnableDeasserted "PCS_a038_dcdcPwmEnableDeassertedCount";
BA_ "Confidence" SG_ 1060 PCS_a040_dcdcLvVoltageTarget 1;
BA_ "Confidence" SG_ 1060 PCS_a040_dcdcLvVoltage 1;
BA_ "Confidence" SG_ 1060 PCS_a040_dcdcLvOutputCurrent 1;
BA_ "Confidence" SG_ 1060 PCS_a041_dcdcTemperature 1;
BA_ "Confidence" SG_ 1060 PCS_a043_dcdcLvBusV 1;
BA_ "Confidence" SG_ 1060 PCS_a043_dcdcHvBusV 1;
BA_ "Confidence" SG_ 1060 PCS_a043_hvPrechargeTargetV 1;
BA_ "Confidence" SG_ 1060 PCS_a044_FaultReasonCode 1;
BA_ "GenSigSNA" SG_ 1060 PCS_a044_FaultReasonCode "0";
BA_ "Confidence" SG_ 1060 PCS_a044_shortTime_us 1;
BA_ "Confidence" SG_ 1060 PCS_a044_dcdcLvBusCurrent_A 1;
BA_ "Confidence" SG_ 1060 PCS_a044_vTankPeak_abs_V 1;
BA_ "Confidence" SG_ 1060 PCS_a045_hvBusEstimated_C_uF 1;
BA_ "Confidence" SG_ 1060 PCS_a045_hvBusEstimated_R_kOhm 1;
BA_ "Confidence" SG_ 1060 PCS_a046_hvBusEstimated_C_uF 1;
BA_ "Confidence" SG_ 1060 PCS_a046_hvBusEstimated_R_kOhm 1;
BA_ "SystemSignalLongSymbol" SG_ 1060 PCS_a047_cpu1BootLoaderCrcMismat "PCS_a047_cpu1BootLoaderCrcMismatch";
BA_ "SystemSignalLongSymbol" SG_ 1060 PCS_a047_cpu2BootLoaderCrcMismat "PCS_a047_cpu2BootLoaderCrcMismatch";
BA_ "Confidence" SG_ 1060 PCS_a049_dcdcTemperature 1;
BA_ "Confidence" SG_ 1060 PCS_a051_phState 1;
BA_ "Confidence" SG_ 1060 PCS_a051_pfcCurrentRms 1;
BA_ "Confidence" SG_ 1060 PCS_a051_llcCurrent 1;
BA_ "Confidence" SG_ 1060 PCS_a051_intBusV 1;
BA_ "Confidence" SG_ 1060 PCS_a051_intBusVTarget 1;
BA_ "Confidence" SG_ 1060 PCS_a051_intBusStaticRipple 1;
BA_ "Confidence" SG_ 1060 PCS_a052_inputVrms 1;
BA_ "Confidence" SG_ 1060 PCS_a053_inputVrms 1;
BA_ "Confidence" SG_ 1060 PCS_a053_inputIrms 1;
BA_ "Confidence" SG_ 1060 PCS_a053_acChargeCurrentLimit 1;
BA_ "Confidence" SG_ 1060 PCS_a053_startingInputVrms 1;
BA_ "Confidence" SG_ 1060 PCS_a053_phaseConfig 1;
BA_ "GenSigSNA" SG_ 1060 PCS_a053_phaseConfig "0";
BA_ "Confidence" SG_ 1060 PCS_a054_inputVrms 1;
BA_ "Confidence" SG_ 1060 PCS_a054_inputIrms 1;
BA_ "Confidence" SG_ 1060 PCS_a054_acChargeCurrentLimit 1;
BA_ "Confidence" SG_ 1060 PCS_a054_startingInputVrms 1;
BA_ "Confidence" SG_ 1060 PCS_a054_phaseConfig 1;
BA_ "GenSigSNA" SG_ 1060 PCS_a054_phaseConfig "0";
BA_ "Confidence" SG_ 1060 PCS_a057_inputVrms 1;
BA_ "Confidence" SG_ 1060 PCS_a057_inputFrequency 1;
BA_ "Confidence" SG_ 1060 PCS_a058_inputVrms 1;
BA_ "Confidence" SG_ 1060 PCS_a058_inputFrequency 1;
BA_ "Confidence" SG_ 1060 PCS_a059_inputVrms 1;
BA_ "Confidence" SG_ 1060 PCS_a059_inputOvRmsThreshold 1;
BA_ "Confidence" SG_ 1060 PCS_a060_inputVPeak 1;
BA_ "Confidence" SG_ 1060 PCS_a060_inputOvPeakThreshold 1;
BA_ "Confidence" SG_ 1060 PCS_a061_chgInputVdcOffset_L1N 1;
BA_ "Confidence" SG_ 1060 PCS_a061_chgInputVdcOffset_L2N 1;
BA_ "Confidence" SG_ 1060 PCS_a061_chgInputVdcOffset_L3N 1;
BA_ "Confidence" SG_ 1060 PCS_a061_chgInputVdcOffset_L1L2 1;
BA_ "SystemSignalLongSymbol" SG_ 1060 PCS_a061_PllSourceIrrational_L1L "PCS_a061_PllSourceIrrational_L1L2";
BA_ "Confidence" SG_ 1060 PCS_a062_chgInputIOffset 1;
BA_ "Confidence" SG_ 1060 PCS_a063_chgOutputV 1;
BA_ "Confidence" SG_ 1060 PCS_a063_hvpHvLinkVoltage 1;
BA_ "Confidence" SG_ 1060 PCS_a064_chgOutputIOffset 1;
BA_ "Confidence" SG_ 1060 PCS_a065_inputVrms 1;
BA_ "Confidence" SG_ 1060 PCS_a065_inputFrequency 1;
BA_ "Confidence" SG_ 1060 PCS_a066_dcdcHvBusVolt 1;
BA_ "Confidence" SG_ 1060 PCS_a066_hvpHvLinkVoltage 1;
BA_ "Confidence" SG_ 1060 PCS_a067_dcdcLvBusVolt 1;
BA_ "Confidence" SG_ 1060 PCS_a067_vcfrontPcsEFuseV 1;
BA_ "GenSigSNA" SG_ 1060 PCS_a067_vcfrontPcsEFuseV "1023";
BA_ "Confidence" SG_ 1060 PCS_a067_vcfrontVcrightVoltage 1;
BA_ "GenSigSNA" SG_ 1060 PCS_a067_vcfrontVcrightVoltage "1023";
BA_ "Confidence" SG_ 1060 PCS_a068_dcdcTankVolt 1;
BA_ "Confidence" SG_ 1060 PCS_a068_dcdcTankVoltOffset 1;
BA_ "Confidence" SG_ 1060 PCS_a069_phState 1;
BA_ "Confidence" SG_ 1060 PCS_a069_inputIDelta 1;
BA_ "Confidence" SG_ 1060 PCS_a069_inputVrms 1;
BA_ "Confidence" SG_ 1060 PCS_a069_intBusV 1;
BA_ "Confidence" SG_ 1060 PCS_a069_inputFrequency 1;
BA_ "Confidence" SG_ 1060 PCS_a070_phState 1;
BA_ "Confidence" SG_ 1060 PCS_a070_inputVDelta 1;
BA_ "Confidence" SG_ 1060 PCS_a070_inputVrms 1;
BA_ "Confidence" SG_ 1060 PCS_a070_intBusV 1;
BA_ "Confidence" SG_ 1060 PCS_a070_inputFrequency 1;
BA_ "Confidence" SG_ 1060 PCS_a071_phState 1;
BA_ "Confidence" SG_ 1060 PCS_a071_inputVrms 1;
BA_ "Confidence" SG_ 1060 PCS_a071_intBusV 1;
BA_ "Confidence" SG_ 1060 PCS_a071_inputFrequency 1;
BA_ "Confidence" SG_ 1060 PCS_a071_llcFrequency 1;
BA_ "Confidence" SG_ 1060 PCS_a073_inputL1NVrms 1;
BA_ "Confidence" SG_ 1060 PCS_a073_inputL2NVrms 1;
BA_ "Confidence" SG_ 1060 PCS_a073_inputL3NVrms 1;
BA_ "Confidence" SG_ 1060 PCS_a073_inputNGVrms 1;
BA_ "Confidence" SG_ 1060 PCS_a073_phaseConfig 1;
BA_ "GenSigSNA" SG_ 1060 PCS_a073_phaseConfig "0";
BA_ "Confidence" SG_ 1060 PCS_a073_cpType 1;
BA_ "Confidence" SG_ 1060 PCS_a074_dcdcLvBusV 1;
BA_ "Confidence" SG_ 1060 PCS_a074_dcdcHvBusV 1;
BA_ "Confidence" SG_ 1060 PCS_a075_dcdcLvBusV 1;
BA_ "Confidence" SG_ 1060 PCS_a075_dcdcHvBusV 1;
BA_ "Confidence" SG_ 1060 PCS_a075_dcdcSubState 1;
BA_ "Confidence" SG_ 1060 PCS_a076_pcsControlRequest 1;
BA_ "Confidence" SG_ 1060 PCS_a076_dcdcSubState 1;
BA_ "SystemSignalLongSymbol" SG_ 1060 PCS_a076_dcdcPwmEnableDeasserted "PCS_a076_dcdcPwmEnableDeassertedCount";
BA_ "Confidence" SG_ 1060 PCS_a078_phaTemperature 1;
BA_ "Confidence" SG_ 1060 PCS_a078_phbTemperature 1;
BA_ "Confidence" SG_ 1060 PCS_a078_phcTemperature 1;
BA_ "Confidence" SG_ 1060 PCS_a078_dcdcTemperature 1;
BA_ "Confidence" SG_ 1060 PCS_a078_ptCoolantTemp 1;
BA_ "Confidence" SG_ 1060 PCS_a079_eepromOperation 1;
BA_ "GenSigSNA" SG_ 1060 PCS_a079_eepromOperation "15";
BA_ "Confidence" SG_ 1060 PCS_a079_eepromOperationRegion 1;
BA_ "SystemSignalLongSymbol" SG_ 1060 PCS_a079_eepromOperationErrorCod "PCS_a079_eepromOperationErrorCode";
BA_ "Confidence" SG_ 1060 PCS_a080_phANVRAMStoredState 1;
BA_ "Confidence" SG_ 1060 PCS_a080_phBNVRAMStoredState 1;
BA_ "Confidence" SG_ 1060 PCS_a080_phCNVRAMStoredState 1;
BA_ "Confidence" SG_ 1060 PCS_a081_dcdcLvBusV 1;
BA_ "Confidence" SG_ 1060 PCS_a081_dcdcHvBusV 1;
BA_ "Confidence" SG_ 1060 PCS_a081_faultedSubstate 1;
BA_ "Confidence" SG_ 1060 PCS_a082_dcdcLvBusV 1;
BA_ "Confidence" SG_ 1060 PCS_a082_dcdcHvBusV 1;
BA_ "Confidence" SG_ 1060 PCS_a082_faultedSubstate 1;
BA_ "Confidence" SG_ 1060 PCS_a085_dcdcHalfPeriodUs 1;
BA_ "Confidence" SG_ 1060 PCS_a086_dcdcTemperature 1;
BA_ "Confidence" SG_ 1060 PCS_a086_pcsAmbientTemperature 1;
BA_ "Confidence" SG_ 1060 PCS_a086_vcfrontPTCoolantTemp 1;
BA_ "Confidence" SG_ 1060 PCS_a088_gridConfig 1;
BA_ "GenSigSNA" SG_ 1060 PCS_a088_gridConfig "0";
BA_ "Confidence" SG_ 1060 PCS_a088_phAFrequency 1;
BA_ "Confidence" SG_ 1060 PCS_a088_phBFrequency 1;
BA_ "Confidence" SG_ 1060 PCS_a088_phCFrequency 1;
BA_ "Confidence" SG_ 1060 PCS_a089_hvSlewRate 1;
BA_ "Confidence" SG_ 1060 PCS_a089_avgSlewRate 1;
BA_ "Confidence" SG_ 1060 PCS_a089_G 1;
BA_ "Confidence" SG_ 1060 PCS_a089_HV_busV 1;
BA_ "Confidence" SG_ 1060 PCS_a089_PhaseShift 1;
BA_ "Confidence" SG_ 1060 PCS_a089_Freq 1;
BA_ "Confidence" SG_ 1060 PCS_a090_vRmsL1N 1;
BA_ "Confidence" SG_ 1060 PCS_a090_vRmsL2N 1;
BA_ "Confidence" SG_ 1060 PCS_a090_vRmsL3N 1;
BA_ "Confidence" SG_ 1060 PCS_a090_vRmsL1L2 1;
BA_ "Confidence" SG_ 1060 PCS_a090_evaluatedGridConfig 1;
BA_ "GenSigSNA" SG_ 1060 PCS_a090_evaluatedGridConfig "0";
BA_ "Confidence" SG_ 1060 PCS_a091_intBusTarget 1;
BA_ "Confidence" SG_ 1060 PCS_a091_intBusMaxRippleLevel 1;
BA_ "Confidence" SG_ 1060 PCS_a091_pfcCurrentIrms 1;
BA_ "Confidence" SG_ 1060 PCS_a091_phaseInputVrms 1;
BA_ "Confidence" SG_ 1060 PCS_a091_phaseTemp 1;
BA_ "Confidence" SG_ 1060 PCS_a092_pfcIrmsPhA 1;
BA_ "Confidence" SG_ 1060 PCS_a092_pfcIrmsPhB 1;
BA_ "Confidence" SG_ 1060 PCS_a092_pfcIrmsPhC 1;
BA_ "Confidence" SG_ 1060 PCS_a092_chgTempPhA 1;
BA_ "Confidence" SG_ 1060 PCS_a092_chgTempPhB 1;
BA_ "Confidence" SG_ 1060 PCS_a092_chgTempPhC 1;
BA_ "Confidence" SG_ 1060 PCS_a093_powerRail5VN 1;
BA_ "Confidence" SG_ 1060 PCS_a093_powerRail3V3 1;
BA_ "Confidence" SG_ 1060 PCS_a093_powerRail1V5 1;
BA_ "Confidence" SG_ 1060 PCS_a093_powerRail1V2 1;
BA_ "Confidence" SG_ 1060 PCS_a094_malfunctionCode 1;
BA_ "Confidence" SG_ 1060 PCS_a095_powerRail5VN 1;
BA_ "Confidence" SG_ 1060 PCS_a095_pcsControlRequest 1;
BA_ "Confidence" SG_ 1060 PCS_a096_gridConfig 1;
BA_ "GenSigSNA" SG_ 1060 PCS_a096_gridConfig "0";
BA_ "Confidence" SG_ 1060 PCS_a096_phAFrequency 1;
BA_ "Confidence" SG_ 1060 PCS_a096_phBFrequency 1;
BA_ "Confidence" SG_ 1060 PCS_a096_phCFrequency 1;
BA_ "Confidence" SG_ 1060 PCS_a097_phANVRAMStoredState 1;
BA_ "Confidence" SG_ 1060 PCS_a097_phBNVRAMStoredState 1;
BA_ "Confidence" SG_ 1060 PCS_a097_phCNVRAMStoredState 1;
BA_ "Confidence" SG_ 1060 PCS_a100_inputVrms 1;
BA_ "Confidence" SG_ 1060 PCS_a100_phIntBusVolt 1;
BA_ "Confidence" SG_ 1060 PCS_a100_phKwhCounter 1;
BA_ "Confidence" SG_ 1060 PCS_a100_phKwhCounterDeltaFromMa 1;
BA_ "SystemSignalLongSymbol" SG_ 1060 PCS_a100_phKwhCounterDeltaFromMa "PCS_a100_phKwhCounterDeltaFromMax";
BA_ "Confidence" SG_ 1060 PCS_a102_pcsControlRequest 1;
BA_ "Confidence" SG_ 1060 PCS_a104_ambientTemperature 1;
BA_ "SystemSignalLongSymbol" SG_ 1060 PCS_a108_installedInAWrongPlatfo "PCS_a108_installedInAWrongPlatform";
BA_ "Confidence" SG_ 1060 PCS_a109_inputL2NVrms 1;
BA_ "Confidence" SG_ 1060 PCS_a109_inputL3NVrms 1;
VAL_ 1962 HVP_debugMessageMultiplexer 12 "Mux12" 11 "Mux11" 10 "Mux10" 9 "Mux9" 8 "Mux8" 7 "Mux7" 6 "Mux6" 5 "Mux5" 4 "Mux4" 3 "Mux3" 2 "Mux2" 1 "Mux1" 0 "Mux0" ;
VAL_ 1962 HVP_ecuLogUploadRequest 3 "REQUEST_PRIORITY_3" 2 "REQUEST_PRIORITY_2" 1 "REQUEST_PRIORITY_1" 0 "REQUEST_PRIORITY_NONE" ;
VAL_ 554 HVP_pcsControlRequest 3 "DISCHARGE" 2 "PRECHARGE" 1 "SUPPORT" 0 "SHUTDOWN" ;
VAL_ 554 HVP_dcLinkVoltageFiltered -550 "SNA" ;
VAL_ 784 HVP_infoIndex 255 "END" 31 "SUBCOMPONENT_GITHASH" 30 "PACKAGE_SN_8_14" 29 "PACKAGE_SN_1_7" 27 "PACKAGE_PN_15_20" 26 "PACKAGE_PN_8_14" 25 "PACKAGE_PN_1_7" 23 "SUBCOMPONENT2" 22 "VARIANTCRC" 20 "UDS_PROTOCOL_BOOTCRC" 19 "VERSION_DEPRECATED" 18 "BOOTLOADER_GITHASH" 17 "APP_GITHASH" 16 "SUBCOMPONENT" 15 "BOOTLOADER_CRC" 14 "BOOTLOADER_SVN" 13 "APP_CRC" 11 "PCBAID_ASSYID_USAGEID" 10 "BUILD_HWID_COMPONENTID" 9 "DEPRECATED_9" 8 "DEPRECATED_8" 7 "DEPRECATED_7" 6 "DEPRECATED_6" 5 "DEPRECATED_5" 4 "DEPRECATED_4" 3 "DEPRECATED_3" 2 "DEPRECATED_2" 1 "DEPRECATED_1" 0 "DEPRECATED_0" ;
VAL_ 784 HVP_buildType 4 "INFO_MFG_BUILD" 3 "INFO_TRACEABLE_CI_BUILD" 2 "INFO_LOCAL_BUILD" 1 "INFO_PLATFORM_BUILD" 0 "INFO_UNKNOWN_BUILD" ;
VAL_ 1914 HVP_log1HzIndex 1 "Mux1" 0 "Mux0" ;
VAL_ 1914 HVP_bmbAsicType 3 "BQ796xx" 2 "ADBMS6830" 1 "LTC831" 0 "UNKNOWN" ;
VAL_ 1914 HVP_shuntCurrentAuxLog 8388000 "PACK_CURRENT_SNA" ;
VAL_ 1914 HVP_pyroSquibResistance 65535 "SNA" ;
VAL_ 1914 HVP_hvilCalType 2 "CAN" 1 "LV" 0 "UNKNOWN" ;
VAL_ 1208 ICR_alertID 142 "a142_ModeOverrideActive" 141 "a141_RequiresReplacement" 140 "a140_OccupancyExceptionEncountered" 139 "a139_AbnormalBlockageDetected" 138 "a138_DriverSideMismatch" 137 "a137_radarBlocked" 136 "a136_radarHighTemperature" 135 "a135_radarTxBallBreak" 134 "a134_radarPgood" 133 "a133_radarBlocked" 64 "a064_busSleepReqTimeout" 63 "a063_SwitchFault" 62 "a062_XCPWasConnected" 61 "a061_XCPConnected" 60 "a060_engineeringBuild" 59 "a059_inputResistanceHigh" 58 "a058_inputRHighSyncDebug" 46 "a046_Task1000msError" 45 "a045_Task100msError" 44 "a044_Task10msError" 43 "a043_Task1msError" 42 "a042_HighStackUsage" 41 "a041_HighCPULoad" 31 "a031_UDSActive" 30 "a030_ECULogUploadRequest" 29 "a029_CoreDump" 22 "a022_TaskInitError" 21 "a021_TaskSchedulerError" 16 "a016_NVMMRecordError" 15 "a015_NVMMError" 13 "a013_AlertManagerFault" 12 "a012_CPUReset" 6 "a006_CANTX_cyclicError" 5 "a005_CANTXError" 3 "a003_SWAssertion" 2 "a002_PowerLossReset" 1 "a001_WatchdogReset" 0 "ALERT_DO_NOT_USE_ZERO" ;
VAL_ 1208 ICR_alertState 1 "SET" 0 "CLEARED" ;
VAL_ 952 ICR_matrixIndex 2 "AlertMatrix2" 1 "AlertMatrix1" 0 "AlertMatrix0" ;
VAL_ 941 ICR_infoIndex 255 "END" 31 "SUBCOMPONENT_GITHASH" 30 "PACKAGE_SN_8_14" 29 "PACKAGE_SN_1_7" 27 "PACKAGE_PN_15_20" 26 "PACKAGE_PN_8_14" 25 "PACKAGE_PN_1_7" 23 "SUBCOMPONENT2" 22 "VARIANTCRC" 20 "UDS_PROTOCOL_BOOTCRC" 19 "VERSION_DEPRECATED" 18 "BOOTLOADER_GITHASH" 17 "APP_GITHASH" 16 "SUBCOMPONENT" 15 "BOOTLOADER_CRC" 14 "BOOTLOADER_SVN" 13 "APP_CRC" 11 "PCBAID_ASSYID_USAGEID" 10 "BUILD_HWID_COMPONENTID" 9 "DEPRECATED_9" 8 "DEPRECATED_8" 7 "DEPRECATED_7" 6 "DEPRECATED_6" 5 "DEPRECATED_5" 4 "DEPRECATED_4" 3 "DEPRECATED_3" 2 "DEPRECATED_2" 1 "DEPRECATED_1" 0 "DEPRECATED_0" ;
VAL_ 941 ICR_infoBuildType 4 "INFO_MFG_BUILD" 3 "INFO_TRACEABLE_CI_BUILD" 2 "INFO_LOCAL_BUILD" 1 "INFO_PLATFORM_BUILD" 0 "INFO_UNKNOWN_BUILD" ;
VAL_ 536 ICR_occupancy1LRaw 3 "SBRStatus_SEAT_SNA" 2 "SBRStatus_SEAT_FAULTED" 1 "SBRStatus_SEAT_OCCUPIED" 0 "SBRStatus_SEAT_UNOCCUPIED" ;
VAL_ 536 ICR_occupancy1RRaw 3 "SBRStatus_SEAT_SNA" 2 "SBRStatus_SEAT_FAULTED" 1 "SBRStatus_SEAT_OCCUPIED" 0 "SBRStatus_SEAT_UNOCCUPIED" ;
VAL_ 536 ICR_userPresenceFilt 3 "SBRStatus_SEAT_SNA" 2 "SBRStatus_SEAT_FAULTED" 1 "SBRStatus_SEAT_OCCUPIED" 0 "SBRStatus_SEAT_UNOCCUPIED" ;
VAL_ 536 ICR_userPresenceRaw 3 "SBRStatus_SEAT_SNA" 2 "SBRStatus_SEAT_FAULTED" 1 "SBRStatus_SEAT_OCCUPIED" 0 "SBRStatus_SEAT_UNOCCUPIED" ;
VAL_ 536 ICR_occupancy1LFilt 3 "SBRStatus_SEAT_SNA" 2 "SBRStatus_SEAT_FAULTED" 1 "SBRStatus_SEAT_OCCUPIED" 0 "SBRStatus_SEAT_UNOCCUPIED" ;
VAL_ 536 ICR_occupancy1RFilt 3 "SBRStatus_SEAT_SNA" 2 "SBRStatus_SEAT_FAULTED" 1 "SBRStatus_SEAT_OCCUPIED" 0 "SBRStatus_SEAT_UNOCCUPIED" ;
VAL_ 536 ICR_occupancy2LFilt 3 "SBRStatus_SEAT_SNA" 2 "SBRStatus_SEAT_FAULTED" 1 "SBRStatus_SEAT_OCCUPIED" 0 "SBRStatus_SEAT_UNOCCUPIED" ;
VAL_ 536 ICR_occupancy2CFilt 3 "SBRStatus_SEAT_SNA" 2 "SBRStatus_SEAT_FAULTED" 1 "SBRStatus_SEAT_OCCUPIED" 0 "SBRStatus_SEAT_UNOCCUPIED" ;
VAL_ 536 ICR_occupancy2RFilt 3 "SBRStatus_SEAT_SNA" 2 "SBRStatus_SEAT_FAULTED" 1 "SBRStatus_SEAT_OCCUPIED" 0 "SBRStatus_SEAT_UNOCCUPIED" ;
VAL_ 536 ICR_childPresenceFilt 2 "DETECTED" 1 "NOT_DETECTED" 0 "DETECTED_SNA" ;
VAL_ 536 ICR_childPresenceRaw 2 "DETECTED" 1 "NOT_DETECTED" 0 "DETECTED_SNA" ;
VAL_ 536 ICR_classification1LFilt 4 "OCCUPANT_CLASSIFICATION_OCCUPIED_ALLOW" 3 "OCCUPANT_CLASSIFICATION_OCCUPIED_INHIBIT" 2 "OCCUPANT_CLASSIFICATION_EMPTY" 1 "OCCUPANT_CLASSIFICATION_INIT" 0 "OCCUPANT_CLASSIFICATION_SNA" ;
VAL_ 536 ICR_classification1RqF 1 "OCCUPANT_CLASSIFICATION_NOT_FAULTED" 0 "OCCUPANT_CLASSIFICATION_FAULTED" ;
VAL_ 536 ICR_occupancy1RFiltExp 3 "SBRStatus_SEAT_SNA" 2 "SBRStatus_SEAT_FAULTED" 1 "SBRStatus_SEAT_OCCUPIED" 0 "SBRStatus_SEAT_UNOCCUPIED" ;
VAL_ 670 ICR_userPresenceMLOutput 255 "SNA" ;
VAL_ 670 ICR_childPresenceMLOutput 255 "SNA" ;
VAL_ 670 ICR_classification1RFilt 4 "OCCUPANT_CLASSIFICATION_OCCUPIED_ALLOW" 3 "OCCUPANT_CLASSIFICATION_OCCUPIED_INHIBIT" 2 "OCCUPANT_CLASSIFICATION_EMPTY" 1 "OCCUPANT_CLASSIFICATION_INIT" 0 "OCCUPANT_CLASSIFICATION_SNA" ;
VAL_ 670 ICR_classification1LRaw 4 "OCCUPANT_CLASSIFICATION_OCCUPIED_ALLOW" 3 "OCCUPANT_CLASSIFICATION_OCCUPIED_INHIBIT" 2 "OCCUPANT_CLASSIFICATION_EMPTY" 1 "OCCUPANT_CLASSIFICATION_INIT" 0 "OCCUPANT_CLASSIFICATION_SNA" ;
VAL_ 670 ICR_classification1RRaw 4 "OCCUPANT_CLASSIFICATION_OCCUPIED_ALLOW" 3 "OCCUPANT_CLASSIFICATION_OCCUPIED_INHIBIT" 2 "OCCUPANT_CLASSIFICATION_EMPTY" 1 "OCCUPANT_CLASSIFICATION_INIT" 0 "OCCUPANT_CLASSIFICATION_SNA" ;
VAL_ 670 ICR_classification1LMLOutput 255 "SNA" ;
VAL_ 670 ICR_classification1RMLOutput 255 "SNA" ;
VAL_ 664 ICR_sensorMode 15 "ICR_SENSOR_INTERFACE_MODE_ERROR" 7 "ICR_SENSOR_INTERFACE_MODE_LPM_TEST" 6 "ICR_SENSOR_INTERFACE_MODE_OCCUPANCY_DETECTION" 5 "ICR_SENSOR_INTERFACE_MODE_HPM_TEST" 4 "ICR_SENSOR_INTERFACE_MODE_CALIBRATION" 3 "ICR_SENSOR_INTERFACE_MODE_CW" 2 "ICR_SENSOR_MODE_END_OF_LINE_TEST" 1 "ICR_SENSOR_MODE_INTRUSTION" 0 "ICR_SENSOR_MODE_SENSOR_STOPPED" ;
VAL_ 664 ICR_blocked 2 "ICR_BLOCKED_TRUE" 1 "ICR_BLOCKED_FALSE" 0 "ICR_BLOCKED_SNA" ;
VAL_ 664 ICR_algoVersion 37 "ICR_ALGO_VERSION_FUTURE_RELEASE_37" 36 "ICR_ALGO_VERSION_v06112025" 35 "ICR_ALGO_VERSION_v04232025" 34 "ICR_ALGO_VERSION_v03192025" 33 "ICR_ALGO_VERSION_v02142025" 32 "ICR_ALGO_VERSION_v01222025" 31 "ICR_ALGO_VERSION_v10072024" 30 "ICR_ALGO_VERSION_v08282024" 29 "ICR_ALGO_VERSION_v07172024" 28 "ICR_ALGO_VERSION_v06122024" 27 "ICR_ALGO_VERSION_v04242024" 26 "ICR_ALGO_VERSION_v03142024" 25 "ICR_ALGO_VERSION_v01312024" 24 "ICR_ALGO_VERSION_v12192023" 23 "ICR_ALGO_VERSION_v10252023" 22 "ICR_ALGO_VERSION_v10112023" 21 "ICR_ALGO_VERSION_v09222023" 20 "ICR_ALGO_VERSION_V08302023" 19 "ICR_ALGO_VERSION_V07172023" 18 "ICR_ALGO_VERSION_V06152023" 17 "ICR_ALGO_VERSION_V06072023" 16 "ICR_ALGO_VERSION_V05192023" 15 "ICR_ALGO_VERSION_V04262023" 14 "ICR_ALGO_VERSION_V1222" 13 "ICR_ALGO_VERSION_V1125" 12 "ICR_ALGO_VERSION_V1118" 11 "ICR_ALGO_VERSION_V1103" 10 "ICR_ALGO_VERSION_V1013" 9 "ICR_ALGO_VERSION_V1006" 8 "ICR_ALGO_VERSION_V927" 7 "ICR_ALGO_VERSION_V902" 6 "ICR_ALGO_VERSION_V826" 5 "ICR_ALGO_VERSION_V803" 4 "ICR_ALGO_VERSION_V715" 3 "ICR_ALGO_VERSION_V711" 2 "ICR_ALGO_VERSION_V204" 1 "ICR_ALGO_VERSION_EXPERIMENTAL" 0 "ICR_ALGO_VERSION_NONE" ;
VAL_ 664 ICR_intrusionStatus 2 "INSTRUSION_STATUS_INTRUSION_DETECTED" 1 "INSTRUSION_STATUS_NONE" 0 "INSTRUSION_STATUS_UNKNOWN" ;
VAL_ 1012 LS_lightShowIndex 24 "LightShowMux24" 23 "LightShowMux23" 22 "LightShowMux22" 21 "LightShowMux21" 20 "LightShowMux20" 19 "LightShowMux19" 18 "LightShowMux18" 17 "LightShowMux17" 16 "LightShowMux16" 15 "LightShowMux15" 14 "LightShowMux14" 13 "LightShowMux13" 12 "LightShowMux12" 11 "LightShowMux11" 10 "LightShowMux10" 9 "LightShowMux9" 8 "LightShowMux8" 7 "LightShowMux7" 6 "LightShowMux6" 5 "LightShowMux5" 4 "LightShowMux4" 3 "LightShowMux3" 2 "LightShowMux2" 1 "LightShowMux1" 0 "LightShowMux0" ;
VAL_ 1012 LS_lightLeftRampedChannel1Durati 3 "TWO_SECONDS" 2 "ONE_SECOND" 1 "HALF_SECOND" 0 "INSTANT" ;
VAL_ 1012 LS_lightLeftRampedChannel2Durati 3 "TWO_SECONDS" 2 "ONE_SECOND" 1 "HALF_SECOND" 0 "INSTANT" ;
VAL_ 1012 LS_lightLeftRampedChannel3Durati 3 "TWO_SECONDS" 2 "ONE_SECOND" 1 "HALF_SECOND" 0 "INSTANT" ;
VAL_ 1012 LS_lightLeftRampedChannel4Durati 3 "TWO_SECONDS" 2 "ONE_SECOND" 1 "HALF_SECOND" 0 "INSTANT" ;
VAL_ 1012 LS_lightLeftRampedChannel5Durati 3 "TWO_SECONDS" 2 "ONE_SECOND" 1 "HALF_SECOND" 0 "INSTANT" ;
VAL_ 1012 LS_lightLeftRampedChannel6Durati 3 "TWO_SECONDS" 2 "ONE_SECOND" 1 "HALF_SECOND" 0 "INSTANT" ;
VAL_ 1012 LS_lightLeftRampedChannel7Durati 3 "TWO_SECONDS" 2 "ONE_SECOND" 1 "HALF_SECOND" 0 "INSTANT" ;
VAL_ 1012 LS_lightRightRampedChannel1Durat 3 "TWO_SECONDS" 2 "ONE_SECOND" 1 "HALF_SECOND" 0 "INSTANT" ;
VAL_ 1012 LS_lightRightRampedChannel2Durat 3 "TWO_SECONDS" 2 "ONE_SECOND" 1 "HALF_SECOND" 0 "INSTANT" ;
VAL_ 1012 LS_lightRightRampedChannel3Durat 3 "TWO_SECONDS" 2 "ONE_SECOND" 1 "HALF_SECOND" 0 "INSTANT" ;
VAL_ 1012 LS_lightRightRampedChannel4Durat 3 "TWO_SECONDS" 2 "ONE_SECOND" 1 "HALF_SECOND" 0 "INSTANT" ;
VAL_ 1012 LS_lightRightRampedChannel5Durat 3 "TWO_SECONDS" 2 "ONE_SECOND" 1 "HALF_SECOND" 0 "INSTANT" ;
VAL_ 1012 LS_lightRightRampedChannel6Durat 3 "TWO_SECONDS" 2 "ONE_SECOND" 1 "HALF_SECOND" 0 "INSTANT" ;
VAL_ 1012 LS_lightRightRampedChannel7Durat 3 "TWO_SECONDS" 2 "ONE_SECOND" 1 "HALF_SECOND" 0 "INSTANT" ;
VAL_ 1012 LS_mirrorRequestLeft 4 "HOLIDAY_PARTY_STOP" 3 "HOLIDAY_PARTY_CLOSE" 2 "HOLIDAY_PARTY_DANCE" 1 "HOLIDAY_PARTY_OPEN" 0 "HOLIDAY_PARTY_IDLE" ;
VAL_ 1012 LS_mirrorRequestRight 4 "HOLIDAY_PARTY_STOP" 3 "HOLIDAY_PARTY_CLOSE" 2 "HOLIDAY_PARTY_DANCE" 1 "HOLIDAY_PARTY_OPEN" 0 "HOLIDAY_PARTY_IDLE" ;
VAL_ 1012 LS_liftgateRequest 4 "HOLIDAY_PARTY_STOP" 3 "HOLIDAY_PARTY_CLOSE" 2 "HOLIDAY_PARTY_DANCE" 1 "HOLIDAY_PARTY_OPEN" 0 "HOLIDAY_PARTY_IDLE" ;
VAL_ 1012 LS_windowRequestLF 4 "HOLIDAY_PARTY_STOP" 3 "HOLIDAY_PARTY_CLOSE" 2 "HOLIDAY_PARTY_DANCE" 1 "HOLIDAY_PARTY_OPEN" 0 "HOLIDAY_PARTY_IDLE" ;
VAL_ 1012 LS_windowRequestLR 4 "HOLIDAY_PARTY_STOP" 3 "HOLIDAY_PARTY_CLOSE" 2 "HOLIDAY_PARTY_DANCE" 1 "HOLIDAY_PARTY_OPEN" 0 "HOLIDAY_PARTY_IDLE" ;
VAL_ 1012 LS_windowRequestRF 4 "HOLIDAY_PARTY_STOP" 3 "HOLIDAY_PARTY_CLOSE" 2 "HOLIDAY_PARTY_DANCE" 1 "HOLIDAY_PARTY_OPEN" 0 "HOLIDAY_PARTY_IDLE" ;
VAL_ 1012 LS_windowRequestRR 4 "HOLIDAY_PARTY_STOP" 3 "HOLIDAY_PARTY_CLOSE" 2 "HOLIDAY_PARTY_DANCE" 1 "HOLIDAY_PARTY_OPEN" 0 "HOLIDAY_PARTY_IDLE" ;
VAL_ 1012 LS_presentingHandleRequestLF 4 "HOLIDAY_PARTY_STOP" 3 "HOLIDAY_PARTY_CLOSE" 2 "HOLIDAY_PARTY_DANCE" 1 "HOLIDAY_PARTY_OPEN" 0 "HOLIDAY_PARTY_IDLE" ;
VAL_ 1012 LS_presentingHandleRequestLR 4 "HOLIDAY_PARTY_STOP" 3 "HOLIDAY_PARTY_CLOSE" 2 "HOLIDAY_PARTY_DANCE" 1 "HOLIDAY_PARTY_OPEN" 0 "HOLIDAY_PARTY_IDLE" ;
VAL_ 1012 LS_presentingHandleRequestRF 4 "HOLIDAY_PARTY_STOP" 3 "HOLIDAY_PARTY_CLOSE" 2 "HOLIDAY_PARTY_DANCE" 1 "HOLIDAY_PARTY_OPEN" 0 "HOLIDAY_PARTY_IDLE" ;
VAL_ 1012 LS_presentingHandleRequestRR 4 "HOLIDAY_PARTY_STOP" 3 "HOLIDAY_PARTY_CLOSE" 2 "HOLIDAY_PARTY_DANCE" 1 "HOLIDAY_PARTY_OPEN" 0 "HOLIDAY_PARTY_IDLE" ;
VAL_ 1012 LS_powerFrontDoorRequestLeft 4 "HOLIDAY_PARTY_STOP" 3 "HOLIDAY_PARTY_CLOSE" 2 "HOLIDAY_PARTY_DANCE" 1 "HOLIDAY_PARTY_OPEN" 0 "HOLIDAY_PARTY_IDLE" ;
VAL_ 1012 LS_powerFrontDoorRequestRight 4 "HOLIDAY_PARTY_STOP" 3 "HOLIDAY_PARTY_CLOSE" 2 "HOLIDAY_PARTY_DANCE" 1 "HOLIDAY_PARTY_OPEN" 0 "HOLIDAY_PARTY_IDLE" ;
VAL_ 1012 LS_falconDoorRequestLeft 4 "HOLIDAY_PARTY_STOP" 3 "HOLIDAY_PARTY_CLOSE" 2 "HOLIDAY_PARTY_DANCE" 1 "HOLIDAY_PARTY_OPEN" 0 "HOLIDAY_PARTY_IDLE" ;
VAL_ 1012 LS_falconDoorRequestRight 4 "HOLIDAY_PARTY_STOP" 3 "HOLIDAY_PARTY_CLOSE" 2 "HOLIDAY_PARTY_DANCE" 1 "HOLIDAY_PARTY_OPEN" 0 "HOLIDAY_PARTY_IDLE" ;
VAL_ 1012 LS_chargePortRequest 3 "REQUEST_SNA" 2 "REQUEST_CLOSE" 1 "REQUEST_OPEN" 0 "REQUEST_NONE" ;
VAL_ 1012 LS_suspensionRequest 3 "SUSPENSION_REQUEST_SNA" 2 "SUSPENSION_REQUEST_LOWER" 1 "SUSPENSION_REQUEST_RAISE" 0 "SUSPENSION_REQUEST_NONE" ;
VAL_ 1060 PCS_alertID 109 "a109_deltaChargingL2L3SwappedDetected" 108 "a108_misconfigurationDetected" 107 "a107_vcPcsDCDCInterfaceMia" 106 "a106_clockSourceNotFromExternalCrystal" 105 "a105_redundantVoltageSourceIrrational" 104 "a104_ambientTempRationality" 103 "a103_pchgWithLowLvDetected" 102 "a102_resetWithDCDCCmdAsserted" 101 "a101_phMachineModelIrrational" 100 "a100_suspectedViperChipIssue" 99 "a099_microGridOverLoadedSilent" 98 "a098_gridFreqDroopDetectedSilent" 97 "a097_rebootPhaseDetected" 96 "a096_microGridOverLoaded" 95 "a095_dcdcSensorlessModeActive" 94 "a094_pcsDcdcNeedService" 93 "a093_powerRailRationality" 92 "a092_chgPowerLimitedByBusRipple" 91 "a091_chgIntBusRationality" 90 "a090_expectedAcVoltageSourceMissing" 89 "a089_hvBusDischargeIrrational" 88 "a088_gridFreqDroopDetected" 87 "a087_nvramRecordStatusError" 86 "a086_dcdcInsufficientCooling" 85 "a085_dcdcFetsNotSwitching" 84 "a084_vDropFastInParasiticDiodeRegion" 83 "a083_triggerOdin" 82 "a082_dcdcPchgUnsafeDiVoltage" 81 "a081_dcdcPchgTimeout" 80 "a080_damagedPhaseDetected" 79 "a079_eepromOperationError" 78 "a078_chgStopDcdcTooHot" 77 "a077_microGridWobbleDetected" 76 "a076_dcdcEnDeassertedErr" 75 "a075_hvBusDischargeTimeout" 74 "a074_hvBusDischargeFailure" 73 "a073_unexpectedAcInputVoltage" 72 "a072_cpu2ClaStopped" 71 "a071_chgPfcILoopRationality" 70 "a070_chgPfcLineDvdt" 69 "a069_chgPfcLineDidt" 68 "a068_dcdcTankvRationality" 67 "a067_dcdcLvRationality" 66 "a066_dcdcHvRationality" 65 "a065_chgPllNotLocked" 64 "a064_chgIOutRationality" 63 "a063_chgVOutRationality" 62 "a062_chgILineRationality" 61 "a061_chgVLineRationality" 60 "a060_chgInputOvPeak" 59 "a059_chgInputOvRms" 58 "a058_chgInputUnderFreq" 57 "a057_chgInputOverFreq" 56 "a056_chgLineImpedanceTooHigh" 55 "a055_chgLineImpedanceHigh" 54 "a054_chgInputVDropTooHigh" 53 "a053_chgInputVDropHigh" 52 "a052_acVoltageNotPresent" 51 "a051_chgIntBusUv" 50 "a050_dcdc12VsupportFaulted" 49 "a049_dcdcTempRationality" 48 "a048_softwareAssertion" 47 "a047_bootloaderCrcMismatch" 46 "a046_hvBusHighImpedence" 45 "a045_hvBusLowImpedance" 44 "a044_12vSupportRegulation" 43 "a043_hvBusPrechargeFailure" 42 "a042_dcdcEnableLineMismatch" 41 "a041_dcdcOverTemp" 40 "a040_dcdcMaxPowerReached" 39 "a039_sdModuleClkFault" 38 "a038_claFaulted" 37 "a037_resonantTankOc" 36 "a036_lvBusOv" 35 "a035_lvBusUv" 34 "a034_hvBusOv" 33 "a033_hvBusUv" 32 "a032_excessiveGridTransientsDetected" 31 "a031_uiMia" 30 "a030_canRationality" 29 "a029_chgPowerRationality" 28 "a028_chgOutputUv" 27 "a027_chgInsufficientCooling" 26 "a026_watchdogAlarmed" 25 "a025_cpu2Malfunction" 24 "a024_vcfrontMia" 23 "a023_cpMia" 22 "a022_bmsMia" 21 "a021_hvpMia" 20 "a020_chgEnableLineMismatch" 19 "a019_acChargePowerLimited" 18 "a018_chgUnknownGridConfig" 17 "a017_chgWallPowerRemoval" 16 "a016_chgAllPhasesFaulted" 15 "a015_chg12vUv" 14 "a014_chgTempRationality" 13 "a013_chgPrechargeFailedBoost" 12 "a012_chgPfcIBandTracerFault" 11 "a011_chgLlcCurrentRegulation" 10 "a010_chgIntBusVRegulation" 9 "a009_chgPfcCurrentRegulation" 8 "a008_chgPhaseOverTemp" 7 "a007_chgPhaseTempHot" 6 "a006_chgPrechargeFailedScr" 5 "a005_chgOutputOv" 4 "a004_chgHwIntBusOv" 3 "a003_chgHwInputOv" 2 "a002_chgHwOutputOc" 1 "a001_chgHwInputOc" 0 "ALERT_DO_NOT_USE_ZERO" ;
VAL_ 1060 PCS_alertSet 1 "SET" 0 "CLEARED" ;
VAL_ 1060 PCS_alertSource 5 "DCDC" 4 "CHG_SYSTEM" 3 "CHG_PHC" 2 "CHG_PHB" 1 "CHG_PHA" 0 "DEFAULT" ;
VAL_ 1060 PCS_a001_phState 6 "SHUTTING_DOWN" 5 "CLEAR_FAULTS" 4 "FAULT" 3 "ENABLE" 2 "PRECHARGE" 1 "IDLE" 0 "INIT" ;
VAL_ 1060 PCS_a002_phState 6 "SHUTTING_DOWN" 5 "CLEAR_FAULTS" 4 "FAULT" 3 "ENABLE" 2 "PRECHARGE" 1 "IDLE" 0 "INIT" ;
VAL_ 1060 PCS_a003_phState 6 "SHUTTING_DOWN" 5 "CLEAR_FAULTS" 4 "FAULT" 3 "ENABLE" 2 "PRECHARGE" 1 "IDLE" 0 "INIT" ;
VAL_ 1060 PCS_a004_phState 6 "SHUTTING_DOWN" 5 "CLEAR_FAULTS" 4 "FAULT" 3 "ENABLE" 2 "PRECHARGE" 1 "IDLE" 0 "INIT" ;
VAL_ 1060 PCS_a006_phState 6 "SHUTTING_DOWN" 5 "CLEAR_FAULTS" 4 "FAULT" 3 "ENABLE" 2 "PRECHARGE" 1 "IDLE" 0 "INIT" ;
VAL_ 1060 PCS_a006_inputFrequency 0 "FREQUENCY_UNKNOWN" ;
VAL_ 1060 PCS_a008_phState 6 "SHUTTING_DOWN" 5 "CLEAR_FAULTS" 4 "FAULT" 3 "ENABLE" 2 "PRECHARGE" 1 "IDLE" 0 "INIT" ;
VAL_ 1060 PCS_a009_phState 6 "SHUTTING_DOWN" 5 "CLEAR_FAULTS" 4 "FAULT" 3 "ENABLE" 2 "PRECHARGE" 1 "IDLE" 0 "INIT" ;
VAL_ 1060 PCS_a010_phState 6 "SHUTTING_DOWN" 5 "CLEAR_FAULTS" 4 "FAULT" 3 "ENABLE" 2 "PRECHARGE" 1 "IDLE" 0 "INIT" ;
VAL_ 1060 PCS_a011_phState 6 "SHUTTING_DOWN" 5 "CLEAR_FAULTS" 4 "FAULT" 3 "ENABLE" 2 "PRECHARGE" 1 "IDLE" 0 "INIT" ;
VAL_ 1060 PCS_a012_phState 6 "SHUTTING_DOWN" 5 "CLEAR_FAULTS" 4 "FAULT" 3 "ENABLE" 2 "PRECHARGE" 1 "IDLE" 0 "INIT" ;
VAL_ 1060 PCS_a013_phState 6 "SHUTTING_DOWN" 5 "CLEAR_FAULTS" 4 "FAULT" 3 "ENABLE" 2 "PRECHARGE" 1 "IDLE" 0 "INIT" ;
VAL_ 1060 PCS_a013_inputFrequency 0 "FREQUENCY_UNKNOWN" ;
VAL_ 1060 PCS_a018_PhaseDiff_L1N_L2N 0 "PHASE_DIFF_UNKNOWN" ;
VAL_ 1060 PCS_a018_PhaseDiff_L2N_L3N 0 "PHASE_DIFF_UNKNOWN" ;
VAL_ 1060 PCS_a018_PhaseDiff_L1N_L3N 0 "PHASE_DIFF_UNKNOWN" ;
VAL_ 1060 PCS_a018_PhaseDiff_L1L2_L1N 0 "PHASE_DIFF_UNKNOWN" ;
VAL_ 1060 PCS_a025_cpu2ErrorCode 10 "CPU2_HWID_CHK_INCOMPLETED" 9 "CRC_VALIDATION_FAILED" 8 "APP_HWID_BAD" 7 "FAILED_TO_RETRIEVE_HWID" 6 "BOOTLOADER_STATUS_INVALID" 5 "FAILED_TO_RETRIEVE_APPCRC" 4 "BOOTSTATUS_INVALID" 3 "APPCRC_MISMATCH" 2 "NO_APP_INSTALLED" 1 "LOSSCOMMS_BOOTLOADER" 0 "NONE" ;
VAL_ 1060 PCS_a029_phaseConfig 9 "TOTAL_NUM" 8 "SINGLE_PHASE_EVSE_PARALLEL" 7 "SINGLE_PHASE_BRIDGED_HARNESS" 6 "MFG_TEST_CONFIG_2" 5 "MFG_TEST_CONFIG_1" 4 "SINGLE_PHASE_IEC_GB" 3 "THREE_PHASE_DELTA" 2 "THREE_PHASE" 1 "SINGLE_PHASE" 0 "SNA" ;
VAL_ 1060 PCS_a030_canRxErrorType 6 "UNKNOWN_ID" 5 "DATAINVALID" 4 "SEQUENCE" 3 "CHECKSUM" 2 "LENGTH_LONG" 1 "LENGTH_SHORT" 0 "NONE" ;
VAL_ 1060 PCS_a038_dcdcClaFaultCode 8 "DEBUG_FORCED" 7 "VTANK_DVDT" 6 "TBCTR_TIMEOUT" 5 "LV_BRD_B_BOOTSTRAP_PRD" 4 "LV_BRD_A_BOOTSTRAP_PRD" 3 "UNEQUAL_ONTIME_ACCUM" 2 "UNEQUAL_ONTIME" 1 "UNEQUAL_PERIOD" 0 "NOT_FAULTED" ;
VAL_ 1060 PCS_a038_dcdcSubState 18 "NUM" 17 "FAULTED" 16 "CLEAR_FAULTS" 15 "PCHG_FAULTED" 14 "DIS_HVBUS_FAULTED" 13 "LV_SUPPORT_FAULTED" 12 "SHUTDOWN" 11 "PCHG_FLT_FAST_DIS_HVBUS" 10 "PCHG_ACTIVE" 9 "PCHG_DI_RECOVERY_WAIT" 8 "PCHG_DWELL_WAIT" 7 "PCHG_DWELL_CHARGE" 6 "PCHG_SLOW_DIS_HVBUS" 5 "PCHG_FAST_DIS_HVBUS" 4 "SLOW_DIS_HVBUS" 3 "FAST_DIS_HVBUS" 2 "LV_SUPPORT_ACTIVE" 1 "STANDBY" 0 "PWR_UP_INIT" ;
VAL_ 1060 PCS_a044_FaultReasonCode 3 "IRRATIONAL_SHORTTIME" 2 "WRONG_DIRECTION" 1 "HIGH_CURRENT" 0 "SNA" ;
VAL_ 1060 PCS_a051_phState 6 "SHUTTING_DOWN" 5 "CLEAR_FAULTS" 4 "FAULT" 3 "ENABLE" 2 "PRECHARGE" 1 "IDLE" 0 "INIT" ;
VAL_ 1060 PCS_a053_phaseConfig 9 "TOTAL_NUM" 8 "SINGLE_PHASE_EVSE_PARALLEL" 7 "SINGLE_PHASE_BRIDGED_HARNESS" 6 "MFG_TEST_CONFIG_2" 5 "MFG_TEST_CONFIG_1" 4 "SINGLE_PHASE_IEC_GB" 3 "THREE_PHASE_DELTA" 2 "THREE_PHASE" 1 "SINGLE_PHASE" 0 "SNA" ;
VAL_ 1060 PCS_a054_phaseConfig 9 "TOTAL_NUM" 8 "SINGLE_PHASE_EVSE_PARALLEL" 7 "SINGLE_PHASE_BRIDGED_HARNESS" 6 "MFG_TEST_CONFIG_2" 5 "MFG_TEST_CONFIG_1" 4 "SINGLE_PHASE_IEC_GB" 3 "THREE_PHASE_DELTA" 2 "THREE_PHASE" 1 "SINGLE_PHASE" 0 "SNA" ;
VAL_ 1060 PCS_a057_inputFrequency 0 "FREQUENCY_UNKNOWN" ;
VAL_ 1060 PCS_a058_inputFrequency 0 "FREQUENCY_UNKNOWN" ;
VAL_ 1060 PCS_a065_inputFrequency 0 "FREQUENCY_UNKNOWN" ;
VAL_ 1060 PCS_a067_vcfrontPcsEFuseV 1023 "SNA" ;
VAL_ 1060 PCS_a067_vcfrontVcrightVoltage 1023 "SNA" ;
VAL_ 1060 PCS_a069_phState 6 "SHUTTING_DOWN" 5 "CLEAR_FAULTS" 4 "FAULT" 3 "ENABLE" 2 "PRECHARGE" 1 "IDLE" 0 "INIT" ;
VAL_ 1060 PCS_a069_inputFrequency 0 "FREQUENCY_UNKNOWN" ;
VAL_ 1060 PCS_a070_phState 6 "SHUTTING_DOWN" 5 "CLEAR_FAULTS" 4 "FAULT" 3 "ENABLE" 2 "PRECHARGE" 1 "IDLE" 0 "INIT" ;
VAL_ 1060 PCS_a070_inputFrequency 0 "FREQUENCY_UNKNOWN" ;
VAL_ 1060 PCS_a071_phState 6 "SHUTTING_DOWN" 5 "CLEAR_FAULTS" 4 "FAULT" 3 "ENABLE" 2 "PRECHARGE" 1 "IDLE" 0 "INIT" ;
VAL_ 1060 PCS_a071_inputFrequency 0 "FREQUENCY_UNKNOWN" ;
VAL_ 1060 PCS_a073_phaseConfig 9 "TOTAL_NUM" 8 "SINGLE_PHASE_EVSE_PARALLEL" 7 "SINGLE_PHASE_BRIDGED_HARNESS" 6 "MFG_TEST_CONFIG_2" 5 "MFG_TEST_CONFIG_1" 4 "SINGLE_PHASE_IEC_GB" 3 "THREE_PHASE_DELTA" 2 "THREE_PHASE" 1 "SINGLE_PHASE" 0 "SNA" ;
VAL_ 1060 PCS_a073_cpType 3 "IEC_CCS" 2 "GB" 1 "EURO_IEC" 0 "US_TESLA" ;
VAL_ 1060 PCS_a075_dcdcSubState 18 "NUM" 17 "FAULTED" 16 "CLEAR_FAULTS" 15 "PCHG_FAULTED" 14 "DIS_HVBUS_FAULTED" 13 "LV_SUPPORT_FAULTED" 12 "SHUTDOWN" 11 "PCHG_FLT_FAST_DIS_HVBUS" 10 "PCHG_ACTIVE" 9 "PCHG_DI_RECOVERY_WAIT" 8 "PCHG_DWELL_WAIT" 7 "PCHG_DWELL_CHARGE" 6 "PCHG_SLOW_DIS_HVBUS" 5 "PCHG_FAST_DIS_HVBUS" 4 "SLOW_DIS_HVBUS" 3 "FAST_DIS_HVBUS" 2 "LV_SUPPORT_ACTIVE" 1 "STANDBY" 0 "PWR_UP_INIT" ;
VAL_ 1060 PCS_a076_pcsControlRequest 3 "DISCHARGE" 2 "PRECHARGE" 1 "SUPPORT" 0 "SHUTDOWN" ;
VAL_ 1060 PCS_a076_dcdcSubState 18 "NUM" 17 "FAULTED" 16 "CLEAR_FAULTS" 15 "PCHG_FAULTED" 14 "DIS_HVBUS_FAULTED" 13 "LV_SUPPORT_FAULTED" 12 "SHUTDOWN" 11 "PCHG_FLT_FAST_DIS_HVBUS" 10 "PCHG_ACTIVE" 9 "PCHG_DI_RECOVERY_WAIT" 8 "PCHG_DWELL_WAIT" 7 "PCHG_DWELL_CHARGE" 6 "PCHG_SLOW_DIS_HVBUS" 5 "PCHG_FAST_DIS_HVBUS" 4 "SLOW_DIS_HVBUS" 3 "FAST_DIS_HVBUS" 2 "LV_SUPPORT_ACTIVE" 1 "STANDBY" 0 "PWR_UP_INIT" ;
VAL_ 1060 PCS_a079_eepromOperation 15 "OPERATION_SNA" 9 "WRITE_RECORD_DATA" 8 "WRITE_RECORD_DESC" 7 "WRITE_RECORD_METADATA" 6 "WRITE_VALIDITY_MARKER" 5 "WRITE_REGION_VALIDITY" 4 "READ_RECORD_DATA" 3 "READ_RECORD_DESC" 2 "READ_RECORD_METADATA" 1 "READ_REGION_VALIDITY_MARKERS" 0 "READ_REGION_VALIDITY" ;
VAL_ 1060 PCS_a079_eepromOperationRegion 3 "UNDEFINED_REGION" 2 "SECONDARY_REGION" 1 "PRIMARY_REGION" 0 "VALIDITY_REGION" ;
VAL_ 1060 PCS_a080_phANVRAMStoredState 4 "RUNNING_CNT_EXPIRED" 3 "RUNNING_CNT_2" 2 "RUNNING_CNT_1" 1 "RUNNING_CNT_0" 0 "PENDING" ;
VAL_ 1060 PCS_a080_phBNVRAMStoredState 4 "RUNNING_CNT_EXPIRED" 3 "RUNNING_CNT_2" 2 "RUNNING_CNT_1" 1 "RUNNING_CNT_0" 0 "PENDING" ;
VAL_ 1060 PCS_a080_phCNVRAMStoredState 4 "RUNNING_CNT_EXPIRED" 3 "RUNNING_CNT_2" 2 "RUNNING_CNT_1" 1 "RUNNING_CNT_0" 0 "PENDING" ;
VAL_ 1060 PCS_a081_faultedSubstate 18 "NUM" 17 "FAULTED" 16 "CLEAR_FAULTS" 15 "PCHG_FAULTED" 14 "DIS_HVBUS_FAULTED" 13 "LV_SUPPORT_FAULTED" 12 "SHUTDOWN" 11 "PCHG_FLT_FAST_DIS_HVBUS" 10 "PCHG_ACTIVE" 9 "PCHG_DI_RECOVERY_WAIT" 8 "PCHG_DWELL_WAIT" 7 "PCHG_DWELL_CHARGE" 6 "PCHG_SLOW_DIS_HVBUS" 5 "PCHG_FAST_DIS_HVBUS" 4 "SLOW_DIS_HVBUS" 3 "FAST_DIS_HVBUS" 2 "LV_SUPPORT_ACTIVE" 1 "STANDBY" 0 "PWR_UP_INIT" ;
VAL_ 1060 PCS_a082_faultedSubstate 18 "NUM" 17 "FAULTED" 16 "CLEAR_FAULTS" 15 "PCHG_FAULTED" 14 "DIS_HVBUS_FAULTED" 13 "LV_SUPPORT_FAULTED" 12 "SHUTDOWN" 11 "PCHG_FLT_FAST_DIS_HVBUS" 10 "PCHG_ACTIVE" 9 "PCHG_DI_RECOVERY_WAIT" 8 "PCHG_DWELL_WAIT" 7 "PCHG_DWELL_CHARGE" 6 "PCHG_SLOW_DIS_HVBUS" 5 "PCHG_FAST_DIS_HVBUS" 4 "SLOW_DIS_HVBUS" 3 "FAST_DIS_HVBUS" 2 "LV_SUPPORT_ACTIVE" 1 "STANDBY" 0 "PWR_UP_INIT" ;
VAL_ 1060 PCS_a088_gridConfig 9 "TOTAL_NUM" 8 "SINGLE_PHASE_EVSE_PARALLEL" 7 "SINGLE_PHASE_BRIDGED_HARNESS" 6 "MFG_TEST_CONFIG_2" 5 "MFG_TEST_CONFIG_1" 4 "SINGLE_PHASE_IEC_GB" 3 "THREE_PHASE_DELTA" 2 "THREE_PHASE" 1 "SINGLE_PHASE" 0 "SNA" ;
VAL_ 1060 PCS_a088_phAFrequency 0 "FREQUENCY_UNKNOWN" ;
VAL_ 1060 PCS_a088_phBFrequency 0 "FREQUENCY_UNKNOWN" ;
VAL_ 1060 PCS_a088_phCFrequency 0 "FREQUENCY_UNKNOWN" ;
VAL_ 1060 PCS_a090_evaluatedGridConfig 9 "TOTAL_NUM" 8 "SINGLE_PHASE_EVSE_PARALLEL" 7 "SINGLE_PHASE_BRIDGED_HARNESS" 6 "MFG_TEST_CONFIG_2" 5 "MFG_TEST_CONFIG_1" 4 "SINGLE_PHASE_IEC_GB" 3 "THREE_PHASE_DELTA" 2 "THREE_PHASE" 1 "SINGLE_PHASE" 0 "SNA" ;
VAL_ 1060 PCS_a094_malfunctionCode 2 "SENSORS" 1 "POWERRAIL" 0 "NONE" ;
VAL_ 1060 PCS_a095_pcsControlRequest 3 "DISCHARGE" 2 "PRECHARGE" 1 "SUPPORT" 0 "SHUTDOWN" ;
VAL_ 1060 PCS_a096_gridConfig 9 "TOTAL_NUM" 8 "SINGLE_PHASE_EVSE_PARALLEL" 7 "SINGLE_PHASE_BRIDGED_HARNESS" 6 "MFG_TEST_CONFIG_2" 5 "MFG_TEST_CONFIG_1" 4 "SINGLE_PHASE_IEC_GB" 3 "THREE_PHASE_DELTA" 2 "THREE_PHASE" 1 "SINGLE_PHASE" 0 "SNA" ;
VAL_ 1060 PCS_a096_phAFrequency 0 "FREQUENCY_UNKNOWN" ;
VAL_ 1060 PCS_a096_phBFrequency 0 "FREQUENCY_UNKNOWN" ;
VAL_ 1060 PCS_a096_phCFrequency 0 "FREQUENCY_UNKNOWN" ;
VAL_ 1060 PCS_a097_phANVRAMStoredState 4 "RUNNING_CNT_EXPIRED" 3 "RUNNING_CNT_2" 2 "RUNNING_CNT_1" 1 "RUNNING_CNT_0" 0 "PENDING" ;
VAL_ 1060 PCS_a097_phBNVRAMStoredState 4 "RUNNING_CNT_EXPIRED" 3 "RUNNING_CNT_2" 2 "RUNNING_CNT_1" 1 "RUNNING_CNT_0" 0 "PENDING" ;
VAL_ 1060 PCS_a097_phCNVRAMStoredState 4 "RUNNING_CNT_EXPIRED" 3 "RUNNING_CNT_2" 2 "RUNNING_CNT_1" 1 "RUNNING_CNT_0" 0 "PENDING" ;
VAL_ 1060 PCS_a102_pcsControlRequest 3 "DISCHARGE" 2 "PRECHARGE" 1 "SUPPORT" 0 "SHUTDOWN" ;
